VERSION ""

NS_ :

BS_:

BU_: PPIM HCP SGW IDCM EVCU2 BPCM

BO_ 834 GLIWA_T1_TX: 8 EVCU2
 SG_ N_PDU_342 : 7|64@0+ (1,0) [0|0] ""  SGW

BO_ 835 GLIWA_T1_RX: 8 SGW
 SG_ N_PDU_343 : 7|64@0+ (1,0) [0|0] ""  EVCU2

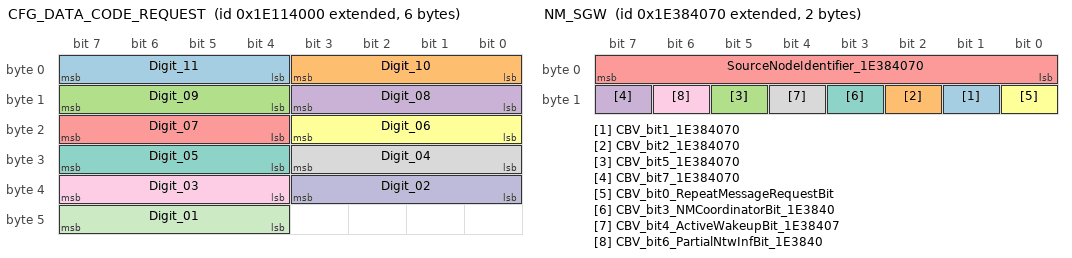
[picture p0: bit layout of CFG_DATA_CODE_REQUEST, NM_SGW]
BO_ 2651930624 CFG_DATA_CODE_REQUEST: 6 EVCU2
 SG_ Digit_11 : 7|4@0+ (1,0) [0|15] ""  PPIM,IDCM,BPCM
 SG_ Digit_10 : 3|4@0+ (1,0) [0|15] ""  PPIM,IDCM,BPCM
 SG_ Digit_09 : 15|4@0+ (1,0) [0|15] ""  PPIM,IDCM,BPCM
 SG_ Digit_08 : 11|4@0+ (1,0) [0|15] ""  PPIM,IDCM,BPCM
 SG_ Digit_07 : 23|4@0+ (1,0) [0|15] ""  PPIM,IDCM,BPCM
 SG_ Digit_06 : 19|4@0+ (1,0) [0|15] ""  PPIM,IDCM,BPCM
 SG_ Digit_05 : 31|4@0+ (1,0) [0|15] ""  PPIM,IDCM,BPCM
 SG_ Digit_04 : 27|4@0+ (1,0) [0|15] ""  PPIM,IDCM,BPCM
 SG_ Digit_03 : 39|4@0+ (1,0) [0|15] ""  PPIM,IDCM,BPCM
 SG_ Digit_02 : 35|4@0+ (1,0) [0|15] ""  PPIM,IDCM,BPCM
 SG_ Digit_01 : 47|4@0+ (1,0) [0|15] ""  PPIM,IDCM,BPCM

BO_ 2564554481 DIAGNOSTIC_REQUEST_FUNCTIONAL: 8 SGW
 SG_ N_PDU_18DBFEF1 : 7|64@0+ (1,0) [0|0] ""  PPIM,IDCM,BPCM,HCP

BO_ 2564502513 DIAGNOSTIC_REQUEST_FUNC_OBD: 8 SGW
 SG_ N_PDU_18DB33F1 : 7|64@0+ (1,0) [0|0] ""  EVCU2,IDCM,BPCM

BO_ 2564485444 DIAGNOSTIC_RESPONSE_BPCM: 8 BPCM
 SG_ N_PDU_18DAF144 : 7|64@0+ (1,0) [0|0] ""  SGW

BO_ 2564441329 DIAGNOSTIC_REQUEST_BPCM: 8 SGW
 SG_ N_PDU_18DA44F1 : 7|64@0+ (1,0) [0|0] ""  BPCM

BO_ 2564485451 DIAGNOSTIC_RESPONSE_HCP: 8 HCP
 SG_ N_PDU_18DAF14B : 7|64@0+ (1,0) [0|0] ""  SGW

BO_ 2564443121 DIAGNOSTIC_REQUEST_HCP: 8 SGW
 SG_ N_PDU_18DA4BF1 : 7|64@0+ (1,0) [0|0] ""  HCP

BO_ 2564485456 DIAGNOSTIC_RESPONSE_IDCM: 8 IDCM
 SG_ N_PDU_18DAF150 : 7|64@0+ (1,0) [0|0] ""  SGW

BO_ 2564444401 DIAGNOSTIC_REQUEST_IDCM: 8 SGW
 SG_ N_PDU_18DA50F1 : 7|64@0+ (1,0) [0|0] ""  IDCM

BO_ 1053 VIN: 32 EVCU2
 SG_ VIN_MSG : 75|2@0+ (1,0) [0|3] ""  PPIM,IDCM,BPCM
 SG_ VIN_DATA : 87|56@0+ (1,0) [0|7.20575940379279E+016] ""  PPIM,IDCM,BPCM

BO_ 520 TRANSM_FD_2: 32 EVCU2
 SG_ GearEngagedForDisplay : 15|5@0+ (1,0) [0|30] "-"  IDCM,BPCM

BO_ 156 TELEMATIC_FD_1: 32 EVCU2
 SG_ GPS_UTC_Second : 151|16@0+ (0.01,0) [0|59.99] "s"  IDCM,BPCM
 SG_ GPS_UTC_Minute : 47|8@0+ (1,0) [0|59] "min"  IDCM,BPCM
 SG_ GPS_UTC_Hour : 55|8@0+ (1,0) [0|23] "h"  IDCM,BPCM
 SG_ GPS_Date_Year : 167|16@0+ (1,0) [0|65534] "Years"  IDCM,BPCM
 SG_ GPS_Date_Month : 71|8@0+ (1,0) [1|12] "Months"  IDCM,BPCM
 SG_ GPS_Date_Day : 63|8@0+ (1,0) [1|31] "Days"  IDCM,BPCM

BO_ 1058 OBD_CONTENT_FRAME: 32 HCP
 SG_ CARB_PERM : 119|1@0+ (1,0) [0|1] "-"  BPCM
 SG_ OAT_PT_EstV : 60|1@0+ (1,0) [0|0] "-"  BPCM
 SG_ OAT_PT_Est : 55|8@0+ (1,-64) [-64|191] "°C"  BPCM

BO_ 1829 IPC_FD_1: 32 EVCU2
 SG_ TotalOdometer : 75|20@0+ (1,0) [0|1048575] "km"  PPIM,IDCM,BPCM

BO_ 1626 IMPACT_INFO: 32 EVCU2
 SG_ IMPACTConfirm : 81|1@0+ (1,0) [0|1] "-"  IDCM,BPCM
 SG_ IMPACTCommand : 80|1@0+ (1,0) [0|1] "-"  IDCM,BPCM

BO_ 2564554482 DIAGNOSTIC_REQUEST_FD_FUNCTIONAL: 64 SGW
 SG_ N_PDU_18DBFEF2 : 7|64@0+ (1,0) [0|0] ""  PPIM,EVCU2,IDCM,BPCM,HCP

BO_ 609 BRAKE_FD_4: 32 EVCU2
 SG_ EPBSts : 115|4@0+ (1,0) [0|14] "-"  IDCM,BPCM

BO_ 1066 BCM_FD_9: 32 EVCU2
 SG_ ExternalTemperature : 0|9@0+ (0.5,-85) [-85|170] "°C"  IDCM,BPCM

BO_ 1827 BCM_FD_7: 32 EVCU2
 SG_ IgnitionOnCounter : 95|16@0+ (1,0) [0|65535] "-"  PPIM,IDCM,BPCM

BO_ 256 BCM_FD_2: 32 EVCU2
 SG_ OperationalModeSts : 75|4@0+ (1,0) [0|15] ""  IDCM,BPCM

BO_ 1153 BCM_FD_10: 32 EVCU2
 SG_ ExternalTemperatureC : 80|9@0+ (0.5,-85) [-85|170] "°C"  PPIM,IDCM,BPCM
 SG_ CmdIgnSts : 138|3@0+ (1,0) [0|7] ""  PPIM,IDCM,BPCM

BO_ 1373 LV_CHARGER3: 32 BPCM
 SG_ DCDC_OutputPower : 81|10@0+ (3,0) [0|3066] "W"  SGW,HCP
 SG_ LVDC_LowVoltageSts : 112|1@0+ (1,0) [0|0] "-"  HCP
 SG_ LVDC_HighVoltageSts : 111|1@0+ (1,0) [0|0] "-"  HCP
 SG_ LVDC_HighCurrentSts : 103|1@0+ (1,0) [0|0] "-"  HCP
 SG_ HVDC_OvervoltageSts : 87|1@0+ (1,0) [0|0] "-"  HCP
 SG_ DCDC_Utilization : 102|7@0+ (1,0) [0|126] "%"  HCP
 SG_ DCDC_TotalOperatingTime : 23|16@0+ (1,0) [0|65534] "Hours"  HCP
 SG_ DCDC_InputPower : 65|10@0+ (3,0) [0|3066] "W"  HCP
 SG_ DCDC_DeratingReason : 86|5@0+ (1,0) [0|0] "-"  HCP
 SG_ DCDC_DeratingPower : 71|6@0+ (50,0) [0|3100] "W"  HCP
 SG_ DCDC_DeratingModeSts : 54|3@0+ (1,0) [0|0] "-"  HCP
 SG_ DCDC_CurrentCycleTime : 7|16@0+ (1,0) [0|65534] "sec"  HCP
 SG_ DCDC_BatteryFeedVoltage : 51|12@0+ (0.0097703,0) [0|40] "V"  HCP

BO_ 1030 LV_CHARGER2: 32 BPCM
 SG_ DCDC_FailureReason : 7|6@0+ (1,0) [0|0] "-"  SGW,HCP
 SG_ LVDC_VoltageSetpointFdbk : 63|8@0+ (0.0625,0) [0|15.875] "V"  HCP
 SG_ LVDC_CurrentSetpointFdbk : 16|9@0+ (1,-255) [-255|255] "Amp"  HCP
 SG_ HVDC_VoltageSetpointFdbk : 32|9@0+ (1,0) [0|510] "V"  HCP
 SG_ HVDC_CurrentSetpointFdbk : 1|10@0+ (0.2,-100) [-100|104.4] "Amp"  HCP
 SG_ DCDC_InternalMode : 19|3@0+ (1,0) [0|0] "-"  HCP
 SG_ DCDC_FailureType : 23|2@0+ (1,0) [0|0] "-"  HCP
 SG_ DCDC_EstimatedPowerLoss : 55|8@0+ (2,0) [0|504] "W"  HCP

BO_ 753 LV_CHARGER1: 32 IDCM
 SG_ LVDC_CurrentFeedback : 19|12@0+ (0.15,-299) [-299|299.5] "Amp"  HCP
 SG_ DCDC_OperationModeSts : 7|4@0+ (1,0) [0|0] "-"  HCP
 SG_ MessageCounter_LV_CHARGER1 : 179|4@0+ (1,0) [0|15] "-" Vector__XXX
 SG_ CRC_LV_CHARGER1 : 191|8@0+ (1,0) [0|255] "-" Vector__XXX
 SG_ LVDC_VoltageFeedback : 51|12@0+ (0.005,0) [0|199.999] "V"  HCP
 SG_ HVDC_VoltageFeedback : 35|12@0+ (0.125,0) [0|510] "V"  HCP
 SG_ HVDC_CurrentFeedback : 3|12@0+ (0.1,-149) [-149|150] "Amp"  HCP
 SG_ IDCM_Wakeup_HCP : 23|1@0+ (1,0) [0|1] "-"  EVCU2

BO_ 752 IBS3_DATA_1: 32 HCP
 SG_ IBS3_Vbatt : 96|9@0+ (0.025,5) [5|17.75] "V"  BPCM

BO_ 267 HYBRID_SYSTEM_EPT1: 32 EVCU2
 SG_ MessageCounter_HYBRID_SYSTEM_EPT : 179|4@0+ (1,0) [0|15] "-"  BPCM
 SG_ LOC_DiagEnable_ePT : 9|2@0+ (1,0) [0|0] "-"  BPCM
 SG_ HybridDriveModeSts : 3|4@0+ (1,0) [0|0] "-"  SGW
 SG_ HCP_ShutdownCommand : 6|3@0+ (1,0) [0|0] "-"  BPCM
 SG_ CRC_HYBRID_SYSTEM_EPT1 : 191|8@0+ (1,0) [0|255] "-"  BPCM
 SG_ WU_Timer_Value : 23|16@0+ (1,0) [0|65535] "min"  IDCM,BPCM
 SG_ PerWakeUp_Diag : 33|10@0+ (1,0) [0|1023] "-"  IDCM,BPCM
 SG_ PropulsionSystemActive_10B : 7|1@0+ (1,0) [0|1] "-"  BPCM

BO_ 1956 HYBRID_RM_MOTORS: 32 HCP
 SG_ MotorB_Temperature : 151|8@0+ (1,-40) [-40|215] "oC"  SGW
 SG_ MotorB_RPM : 23|16@0+ (1,-32768) [-32768|32767] "RPM"  SGW
 SG_ MotorB_InverterTemp : 159|8@0+ (1,-40) [-40|215] "oC"  SGW
 SG_ MotorB_DC_Voltage : 113|10@0+ (1,0) [0|1023] "V"  SGW
 SG_ MotorB_DC_Current : 54|15@0+ (0.1,-1638.4) [-1638.4|1638.3] "A"  SGW
 SG_ MotorA_Temperature : 135|8@0+ (1,-40) [-40|215] "oC"  SGW
 SG_ MotorA_RPM : 7|16@0+ (1,-32768) [-32768|32767] "RPM"  SGW
 SG_ MotorA_InverterTemp : 143|8@0+ (1,-40) [-40|215] "oC"  SGW
 SG_ MotorA_DC_Voltage : 97|10@0+ (1,0) [0|1023] "V"  SGW
 SG_ MotorA_DC_Current : 38|15@0+ (0.1,-1638.4) [-1638.4|1638.3] "A"  SGW
 SG_ Warning_MotorB_Overtemp : 55|1@0+ (1,0) [0|1] ""  SGW
 SG_ Warning_MotorA_Overtemp : 39|1@0+ (1,0) [0|1] ""  SGW
 SG_ Warning_InverterA_Overtemp : 69|1@0+ (1,0) [0|1] ""  SGW
 SG_ Warning_DCDCTemp_DPT : 71|1@0+ (1,0) [0|1] ""  SGW
 SG_ Warning_DCDCPerformance_DPT : 85|1@0+ (1,0) [0|1] ""  SGW
 SG_ MotorB_InverterState : 117|4@0+ (1,0) [0|15] ""  SGW
 SG_ MotorA_InverterState : 101|4@0+ (1,0) [0|15] ""  SGW
 SG_ Warning_InverterB_Overtemp : 70|1@0+ (1,0) [0|1] ""  SGW
 SG_ MotorB_TorqueAchieved : 84|13@0+ (0.125,-512) [-512|511.875] "Nm"  SGW
 SG_ MotorA_TorqueAchieved : 68|13@0+ (0.125,-512) [-512|511.875] "Nm"  SGW

BO_ 1033 HYBRID_POWERTRAIN5: 32 HCP
 SG_ MCP_DC_Current : 6|15@0+ (0.1,-1638.4) [-1638.3|1638.3] "Amp"  BPCM
 SG_ MCP_DC_CurrentV : 23|1@0+ (1,0) [0|0] "-"  BPCM

BO_ 1834 HVBATTERY5: 32 BPCM
 SG_ HVBattery_RealTimeClockV : 36|1@0+ (1,0) [0|0] "-"  EVCU2
 SG_ HVBattery_RealTimeClock : 7|32@0+ (1,0) [0|4294967294] "sec"  EVCU2
 SG_ HVBatteryBalanceMode : 54|1@0+ (1,0) [0|0] "-"  HCP
 SG_ HVBatteryBalanceComplete : 55|1@0+ (1,0) [0|0] "-"  HCP
 SG_ HVBatCellOCVoltage_MinV : 39|1@0+ (1,0) [0|0] "-"  HCP
 SG_ HVBatCellOCVoltage_Min : 67|12@0+ (0.001,1.5) [1.5|4.5] "Volts"  HCP
 SG_ HVBatCellOCVoltage_MaxV : 38|1@0+ (1,0) [0|0] "-"  HCP
 SG_ HVBatCellOCVoltage_Max : 51|12@0+ (0.001,1.5) [1.5|4.5] "Volts"  HCP
 SG_ HVBatCellOCVoltage_AverageV : 37|1@0+ (1,0) [0|0] "-"  HCP
 SG_ HVBatCellOCVoltage_Average : 35|12@0+ (0.001,1.5) [1.5|4.5] "Volts"  HCP
 SG_ HVBatCellDischargeImped_Min : 99|12@0+ (0.01,0) [0|40.9] "Ohms"  HCP
 SG_ HVBatCellDischargeImped_Max : 83|12@0+ (0.01,0) [0|40.9] "Ohms"  HCP

BO_ 1029 HVBATTERY3: 32 BPCM
 SG_ HVBatPowerLimited : 117|1@0+ (1,0) [0|0] "-"  HCP
 SG_ BSGDischargePower_ShortV : 114|1@0+ (1,0) [0|0] "-"  HCP
 SG_ BSGDischargePower_Short : 87|8@0+ (0.1,0) [0|25] "kW"  HCP
 SG_ BSGDischargePower_LongV : 113|1@0+ (1,0) [0|0] "-"  HCP
 SG_ BSGDischargePower_Long : 79|8@0+ (0.1,0) [0|25] "kW"  HCP
 SG_ BSGDischargePower_InstantV : 115|1@0+ (1,0) [0|0] "-"  HCP
 SG_ BSGDischargePower_Instant : 95|8@0+ (0.1,0) [0|25] "kW"  HCP
 SG_ BSGChargePower_ShortV : 111|1@0+ (1,0) [0|0] "-"  HCP
 SG_ BSGChargePower_Short : 63|8@0+ (0.1,0) [0|25] "kW"  HCP
 SG_ BSGChargePower_LongV : 110|1@0+ (1,0) [0|0] "-"  HCP
 SG_ BSGChargePower_Long : 55|8@0+ (0.1,0) [0|25] "kW"  HCP
 SG_ BSGChargePower_InstantV : 112|1@0+ (1,0) [0|0] "-"  HCP
 SG_ BSGChargePower_Instant : 71|8@0+ (0.1,0) [0|25] "kW"  HCP

BO_ 1027 HVBATTERY2: 32 BPCM
 SG_ HVBatterySOCV : 52|1@0+ (1,0) [0|0] "-"  HCP
 SG_ HVBatterySOC : 3|12@0+ (0.02442,0) [0|100] "%"  SGW,HCP
 SG_ HVBatteryMILRequest : 7|1@0+ (1,0) [0|0] "-"  HCP
 SG_ HVBatterySOH : 39|8@0+ (0.2,50) [50|100] "%"  HCP
 SG_ HVBatterySOC_Min : 31|8@0+ (0.392157,0) [0|100] "%"  HCP
 SG_ HVBatterySOC_Max : 23|8@0+ (0.392157,0) [0|100] "%"  HCP
 SG_ HVBatteryServiceRequest : 51|1@0+ (1,0) [0|0] "-"  HCP
 SG_ PrechargePenaltyTimer : 49|10@0+ (2,0) [0|1800] "sec"  HCP

BO_ 266 HVBATTERY1: 32 BPCM
 SG_ HVBatteryCurrent : 5|14@0+ (0.1,-512.1) [-512|512] "Amp"  HCP
 SG_ HVBatContactorSts : 23|3@0+ (1,0) [0|0] "-"  HCP
 SG_ HVBatCellVoltage_NumMax : 71|4@0+ (1,0) [0|15] "Volts"  HCP
 SG_ HVBatCellVoltage_Min : 108|13@0+ (0.001,0) [0|5] "Volts"  HCP
 SG_ HVBatCellVoltage_Max : 36|13@0+ (0.001,0) [0|5] "Volts"  HCP
 SG_ HVBatteryVoltageV : 98|1@0+ (1,0) [0|0] "-"  HCP
 SG_ HVBatteryReady : 97|1@0+ (1,0) [0|0] "-"  HCP
 SG_ HVBatteryCurrentV : 96|1@0+ (1,0) [0|0] "-"  HCP
 SG_ HVBatContactorReq : 55|1@0+ (1,0) [0|0] "-"  HCP
 SG_ HVBatContactorOpen : 39|1@0+ (1,0) [0|0] "-"  HCP
 SG_ HVBatCellVoltage_MinV : 101|1@0+ (1,0) [0|0] "-"  HCP
 SG_ HVBatCellVoltage_MaxV : 100|1@0+ (1,0) [0|0] "-"  HCP
 SG_ HVBatCellVoltage_AverageV : 99|1@0+ (1,0) [0|0] "-"  HCP
 SG_ HVBatCellVoltage_Average : 20|13@0+ (0.001,0) [0|5] "Volts"  HCP
 SG_ HVBatteryVoltage_BSG : 85|6@0+ (1,20) [20|70] "-"  HCP
 SG_ HVBatCellVoltage_NumMin : 51|4@0+ (1,0) [0|15] "Volts"  HCP
 SG_ HVBatShutdownReady : 183|2@0+ (1,0) [0|3] "-"  HCP
 SG_ HVBatContactorWelded : 110|2@0+ (1,0) [0|2] "-"  HCP

BO_ 1034 HVBATTERY_THERMAL: 48 BPCM
 SG_ HVBatModuleTemp_MinV : 87|1@0+ (1,0) [0|0] "-"  HCP
 SG_ HVBatModuleTemp_Min : 159|8@0+ (1,-40) [-40|214] "°C"  SGW,HCP
 SG_ HVBatModuleTemp_MaxV : 209|1@0+ (1,0) [0|0] "-"  HCP
 SG_ HVBatModuleTemp_Max : 151|8@0+ (1,-40) [-40|214] "°C"  SGW,HCP
 SG_ HVBatSleepTime : 7|8@0+ (0.2,0) [0|48] "Days"  EVCU2
 SG_ HVBatModuleTemp_AverageV : 210|1@0+ (1,0) [0|0] "-"  HCP
 SG_ HVBatModuleTemp_Average : 143|8@0+ (1,-40) [-40|214] "°C"  HCP
 SG_ HVBatLowTempThreshold : 231|8@0+ (1,-40) [-40|214] "°C"  HCP
 SG_ HVBatHighTempThreshold : 223|8@0+ (1,-40) [-40|214] "°C"  HCP
 SG_ HVBatModuleTemp_NumMin : 268|5@0+ (1,0) [0|31] "-"  SGW
 SG_ HVBatModuleTemp_NumMax : 260|5@0+ (1,0) [0|31] "-"  SGW

BO_ 1839 HVBATTERY_RM_MODS1: 48 BPCM
 SG_ HVBatModuleTemp_16 : 127|8@0+ (1,-40) [-40|215] "°C"  SGW
 SG_ HVBatModuleTemp_15 : 119|8@0+ (1,-40) [-40|215] "°C"  SGW
 SG_ HVBatModuleTemp_14 : 111|8@0+ (1,-40) [-40|215] "°C"  SGW
 SG_ HVBatModuleTemp_13 : 103|8@0+ (1,-40) [-40|215] "°C"  SGW
 SG_ HVBatModuleTemp_12 : 95|8@0+ (1,-40) [-40|215] "°C"  SGW
 SG_ HVBatModuleTemp_11 : 87|8@0+ (1,-40) [-40|215] "°C"  SGW
 SG_ HVBatModuleTemp_10 : 79|8@0+ (1,-40) [-40|215] "°C"  SGW
 SG_ HVBatModuleTemp_09 : 71|8@0+ (1,-40) [-40|215] "°C"  SGW
 SG_ HVBatModuleTemp_08 : 63|8@0+ (1,-40) [-40|215] "°C"  SGW
 SG_ HVBatModuleTemp_07 : 55|8@0+ (1,-40) [-40|215] "°C"  SGW
 SG_ HVBatModuleTemp_06 : 47|8@0+ (1,-40) [-40|215] "°C"  SGW
 SG_ HVBatModuleTemp_05 : 39|8@0+ (1,-40) [-40|215] "°C"  SGW
 SG_ HVBatModuleTemp_04 : 31|8@0+ (1,-40) [-40|215] "°C"  SGW
 SG_ HVBatModuleTemp_03 : 23|8@0+ (1,-40) [-40|215] "°C"  SGW
 SG_ HVBatModuleTemp_02 : 15|8@0+ (1,-40) [-40|215] "°C"  SGW
 SG_ HVBatModuleTemp_01 : 7|8@0+ (1,-40) [-40|215] "°C"  SGW
 SG_ HVBatModuleTemp_38 : 303|8@0+ (1,-40) [-40|215] "°C" Vector__XXX
 SG_ HVBatModuleTemp_37 : 295|8@0+ (1,-40) [-40|215] "°C" Vector__XXX
 SG_ HVBatModuleTemp_36 : 287|8@0+ (1,-40) [-40|215] "°C" Vector__XXX
 SG_ HVBatModuleTemp_35 : 279|8@0+ (1,-40) [-40|215] "°C" Vector__XXX
 SG_ HVBatModuleTemp_34 : 271|8@0+ (1,-40) [-40|215] "°C" Vector__XXX
 SG_ HVBatModuleTemp_33 : 263|8@0+ (1,-40) [-40|215] "°C" Vector__XXX
 SG_ HVBatModuleTemp_32 : 255|8@0+ (1,-40) [-40|215] "°C" Vector__XXX
 SG_ HVBatModuleTemp_31 : 247|8@0+ (1,-40) [-40|215] "°C" Vector__XXX
 SG_ HVBatModuleTemp_30 : 239|8@0+ (1,-40) [-40|215] "°C" Vector__XXX
 SG_ HVBatModuleTemp_29 : 231|8@0+ (1,-40) [-40|215] "°C" Vector__XXX
 SG_ HVBatModuleTemp_28 : 223|8@0+ (1,-40) [-40|215] "°C" Vector__XXX
 SG_ HVBatModuleTemp_27 : 215|8@0+ (1,-40) [-40|215] "°C" Vector__XXX
 SG_ HVBatModuleTemp_26 : 207|8@0+ (1,-40) [-40|215] "°C" Vector__XXX
 SG_ HVBatModuleTemp_25 : 199|8@0+ (1,-40) [-40|215] "°C" Vector__XXX
 SG_ HVBatModuleTemp_24 : 191|8@0+ (1,-40) [-40|215] "°C" Vector__XXX
 SG_ HVBatModuleTemp_23 : 183|8@0+ (1,-40) [-40|215] "°C" Vector__XXX
 SG_ HVBatModuleTemp_22 : 175|8@0+ (1,-40) [-40|215] "°C" Vector__XXX
 SG_ HVBatModuleTemp_21 : 167|8@0+ (1,-40) [-40|215] "°C" Vector__XXX
 SG_ HVBatModuleTemp_20 : 159|8@0+ (1,-40) [-40|215] "°C" Vector__XXX
 SG_ HVBatModuleTemp_19 : 151|8@0+ (1,-40) [-40|215] "°C" Vector__XXX
 SG_ HVBatModuleTemp_18 : 143|8@0+ (1,-40) [-40|215] "°C" Vector__XXX
 SG_ HVBatModuleTemp_17 : 135|8@0+ (1,-40) [-40|215] "°C" Vector__XXX

BO_ 1840 HVBATTERY_RM_CHARGING1: 32 BPCM
 SG_ IsolationResistance : 7|16@0+ (1,0) [0|65534] "kOhm"  SGW
 SG_ Warning_SOCJump : 24|1@0+ (1,0) [0|1] "-"  SGW
 SG_ Warning_PackUnmatched : 27|1@0+ (1,0) [0|1] "-"  SGW
 SG_ Warning_PackUndervoltage : 19|1@0+ (1,0) [0|1] "-"  SGW
 SG_ Warning_PackTempHigh : 26|1@0+ (1,0) [0|1] "-"  EVCU2,SGW
 SG_ Warning_PackTempDiff : 25|1@0+ (1,0) [0|1] "-"  SGW
 SG_ Warning_PackOvervoltage : 20|1@0+ (1,0) [0|1] "-"  SGW
 SG_ Warning_Overcharging : 21|1@0+ (1,0) [0|1] "-"  SGW
 SG_ Warning_LowSOC : 22|1@0+ (1,0) [0|1] "-"  SGW
 SG_ Warning_Insulation : 28|1@0+ (1,0) [0|1] "-"  SGW
 SG_ Warning_HVIL : 29|1@0+ (1,0) [0|1] "-"  SGW
 SG_ Warning_HighSOC : 23|1@0+ (1,0) [0|1] "-"  SGW
 SG_ Warning_CellUndervoltage : 17|1@0+ (1,0) [0|1] "-"  SGW
 SG_ Warning_CellOvervoltage : 18|1@0+ (1,0) [0|1] "-"  SGW
 SG_ Warning_CellBalance : 16|1@0+ (1,0) [0|1] "-"  SGW
 SG_ HighestWarningLevel : 39|2@0+ (1,0) [0|3] "-"  SGW

BO_ 1838 HVBATTERY_RM_CELLS4: 64 BPCM
 SG_ HVBatCellVoltage_Cell096 : 228|13@0+ (0.001,0) [0|5] "V"  SGW
 SG_ HVBatCellVoltage_Cell095 : 212|13@0+ (0.001,0) [0|5] "V"  SGW
 SG_ HVBatCellVoltage_Cell094 : 196|13@0+ (0.001,0) [0|5] "V"  SGW
 SG_ HVBatCellVoltage_Cell093 : 180|13@0+ (0.001,0) [0|5] "V"  SGW
 SG_ HVBatCellVoltage_Cell092 : 164|13@0+ (0.001,0) [0|5] "V"  SGW
 SG_ HVBatCellVoltage_Cell091 : 148|13@0+ (0.001,0) [0|5] "V"  SGW
 SG_ HVBatCellVoltage_Cell090 : 132|13@0+ (0.001,0) [0|5] "V"  SGW
 SG_ HVBatCellVoltage_Cell089 : 116|13@0+ (0.001,0) [0|5] "V"  SGW
 SG_ HVBatCellVoltage_Cell088 : 100|13@0+ (0.001,0) [0|5] "V"  SGW
 SG_ HVBatCellVoltage_Cell087 : 84|13@0+ (0.001,0) [0|5] "V"  SGW
 SG_ HVBatCellVoltage_Cell086 : 68|13@0+ (0.001,0) [0|5] "V"  SGW
 SG_ HVBatCellVoltage_Cell085 : 52|13@0+ (0.001,0) [0|5] "V"  SGW
 SG_ HVBatCellVoltage_Cell084 : 36|13@0+ (0.001,0) [0|5] "V"  SGW
 SG_ HVBatCellVoltage_Cell083 : 20|13@0+ (0.001,0) [0|5] "V"  SGW
 SG_ HVBatCellVoltage_Cell082 : 4|13@0+ (0.001,0) [0|5] "V"  SGW
 SG_ HVBatCellVoltage_Cell108 : 420|13@0+ (0.001,0) [0|5] "V"  SGW
 SG_ HVBatCellVoltage_Cell107 : 404|13@0+ (0.001,0) [0|5] "V"  SGW
 SG_ HVBatCellVoltage_Cell106 : 388|13@0+ (0.001,0) [0|5] "V"  SGW
 SG_ HVBatCellVoltage_Cell105 : 372|13@0+ (0.001,0) [0|5] "V"  SGW
 SG_ HVBatCellVoltage_Cell104 : 356|13@0+ (0.001,0) [0|5] "V"  SGW
 SG_ HVBatCellVoltage_Cell103 : 340|13@0+ (0.001,0) [0|5] "V"  SGW
 SG_ HVBatCellVoltage_Cell102 : 324|13@0+ (0.001,0) [0|5] "V"  SGW
 SG_ HVBatCellVoltage_Cell101 : 308|13@0+ (0.001,0) [0|5] "V"  SGW
 SG_ HVBatCellVoltage_Cell100 : 292|13@0+ (0.001,0) [0|5] "V"  SGW
 SG_ HVBatCellVoltage_Cell099 : 276|13@0+ (0.001,0) [0|5] "V"  SGW
 SG_ HVBatCellVoltage_Cell098 : 260|13@0+ (0.001,0) [0|5] "V"  SGW
 SG_ HVBatCellVoltage_Cell097 : 244|13@0+ (0.001,0) [0|5] "V"  SGW

BO_ 1837 HVBATTERY_RM_CELLS3: 64 BPCM
 SG_ HVBatCellVoltage_Cell081 : 420|13@0+ (0.001,0) [0|5] "V"  SGW
 SG_ HVBatCellVoltage_Cell080 : 404|13@0+ (0.001,0) [0|5] "V"  SGW
 SG_ HVBatCellVoltage_Cell079 : 388|13@0+ (0.001,0) [0|5] "V"  SGW
 SG_ HVBatCellVoltage_Cell078 : 372|13@0+ (0.001,0) [0|5] "V"  SGW
 SG_ HVBatCellVoltage_Cell077 : 356|13@0+ (0.001,0) [0|5] "V"  SGW
 SG_ HVBatCellVoltage_Cell076 : 340|13@0+ (0.001,0) [0|5] "V"  SGW
 SG_ HVBatCellVoltage_Cell075 : 324|13@0+ (0.001,0) [0|5] "V"  SGW
 SG_ HVBatCellVoltage_Cell074 : 308|13@0+ (0.001,0) [0|5] "V"  SGW
 SG_ HVBatCellVoltage_Cell073 : 292|13@0+ (0.001,0) [0|5] "V"  SGW
 SG_ HVBatCellVoltage_Cell072 : 276|13@0+ (0.001,0) [0|5] "V"  SGW
 SG_ HVBatCellVoltage_Cell071 : 260|13@0+ (0.001,0) [0|5] "V"  SGW
 SG_ HVBatCellVoltage_Cell070 : 244|13@0+ (0.001,0) [0|5] "V"  SGW
 SG_ HVBatCellVoltage_Cell069 : 228|13@0+ (0.001,0) [0|5] "V"  SGW
 SG_ HVBatCellVoltage_Cell068 : 212|13@0+ (0.001,0) [0|5] "V"  SGW
 SG_ HVBatCellVoltage_Cell067 : 196|13@0+ (0.001,0) [0|5] "V"  SGW
 SG_ HVBatCellVoltage_Cell066 : 180|13@0+ (0.001,0) [0|5] "V"  SGW
 SG_ HVBatCellVoltage_Cell065 : 164|13@0+ (0.001,0) [0|5] "V"  SGW
 SG_ HVBatCellVoltage_Cell064 : 148|13@0+ (0.001,0) [0|5] "V"  SGW
 SG_ HVBatCellVoltage_Cell063 : 132|13@0+ (0.001,0) [0|5] "V"  SGW
 SG_ HVBatCellVoltage_Cell062 : 116|13@0+ (0.001,0) [0|5] "V"  SGW
 SG_ HVBatCellVoltage_Cell061 : 100|13@0+ (0.001,0) [0|5] "V"  SGW
 SG_ HVBatCellVoltage_Cell060 : 84|13@0+ (0.001,0) [0|5] "V"  SGW
 SG_ HVBatCellVoltage_Cell059 : 68|13@0+ (0.001,0) [0|5] "V"  SGW
 SG_ HVBatCellVoltage_Cell058 : 52|13@0+ (0.001,0) [0|5] "V"  SGW
 SG_ HVBatCellVoltage_Cell057 : 36|13@0+ (0.001,0) [0|5] "V"  SGW
 SG_ HVBatCellVoltage_Cell056 : 20|13@0+ (0.001,0) [0|5] "V"  SGW
 SG_ HVBatCellVoltage_Cell055 : 4|13@0+ (0.001,0) [0|5] "V"  SGW

BO_ 1836 HVBATTERY_RM_CELLS2: 64 BPCM
 SG_ HVBatCellVoltage_Cell054 : 420|13@0+ (0.001,0) [0|5] "V"  SGW
 SG_ HVBatCellVoltage_Cell053 : 404|13@0+ (0.001,0) [0|5] "V"  SGW
 SG_ HVBatCellVoltage_Cell052 : 388|13@0+ (0.001,0) [0|5] "V"  SGW
 SG_ HVBatCellVoltage_Cell051 : 372|13@0+ (0.001,0) [0|5] "V"  SGW
 SG_ HVBatCellVoltage_Cell050 : 356|13@0+ (0.001,0) [0|5] "V"  SGW
 SG_ HVBatCellVoltage_Cell049 : 340|13@0+ (0.001,0) [0|5] "V"  SGW
 SG_ HVBatCellVoltage_Cell048 : 324|13@0+ (0.001,0) [0|5] "V"  SGW
 SG_ HVBatCellVoltage_Cell047 : 308|13@0+ (0.001,0) [0|5] "V"  SGW
 SG_ HVBatCellVoltage_Cell046 : 292|13@0+ (0.001,0) [0|5] "V"  SGW
 SG_ HVBatCellVoltage_Cell045 : 276|13@0+ (0.001,0) [0|5] "V"  SGW
 SG_ HVBatCellVoltage_Cell044 : 260|13@0+ (0.001,0) [0|5] "V"  SGW
 SG_ HVBatCellVoltage_Cell043 : 244|13@0+ (0.001,0) [0|5] "V"  SGW
 SG_ HVBatCellVoltage_Cell042 : 228|13@0+ (0.001,0) [0|5] "V"  SGW
 SG_ HVBatCellVoltage_Cell041 : 212|13@0+ (0.001,0) [0|5] "V"  SGW
 SG_ HVBatCellVoltage_Cell040 : 196|13@0+ (0.001,0) [0|5] "V"  SGW
 SG_ HVBatCellVoltage_Cell039 : 180|13@0+ (0.001,0) [0|5] "V"  SGW
 SG_ HVBatCellVoltage_Cell038 : 164|13@0+ (0.001,0) [0|5] "V"  SGW
 SG_ HVBatCellVoltage_Cell037 : 148|13@0+ (0.001,0) [0|5] "V"  SGW
 SG_ HVBatCellVoltage_Cell036 : 132|13@0+ (0.001,0) [0|5] "V"  SGW
 SG_ HVBatCellVoltage_Cell035 : 116|13@0+ (0.001,0) [0|5] "V"  SGW
 SG_ HVBatCellVoltage_Cell034 : 100|13@0+ (0.001,0) [0|5] "V"  SGW
 SG_ HVBatCellVoltage_Cell033 : 84|13@0+ (0.001,0) [0|5] "V"  SGW
 SG_ HVBatCellVoltage_Cell032 : 68|13@0+ (0.001,0) [0|5] "V"  SGW
 SG_ HVBatCellVoltage_Cell031 : 52|13@0+ (0.001,0) [0|5] "V"  SGW
 SG_ HVBatCellVoltage_Cell030 : 36|13@0+ (0.001,0) [0|5] "V"  SGW
 SG_ HVBatCellVoltage_Cell029 : 20|13@0+ (0.001,0) [0|5] "V"  SGW
 SG_ HVBatCellVoltage_Cell028 : 4|13@0+ (0.001,0) [0|5] "V"  SGW

BO_ 1835 HVBATTERY_RM_CELLS1: 64 BPCM
 SG_ HVBatCellVoltage_Cell027 : 420|13@0+ (0.001,0) [0|5] "V"  SGW
 SG_ HVBatCellVoltage_Cell026 : 404|13@0+ (0.001,0) [0|5] "V"  SGW
 SG_ HVBatCellVoltage_Cell025 : 388|13@0+ (0.001,0) [0|5] "V"  SGW
 SG_ HVBatCellVoltage_Cell024 : 372|13@0+ (0.001,0) [0|5] "V"  SGW
 SG_ HVBatCellVoltage_Cell023 : 356|13@0+ (0.001,0) [0|5] "V"  SGW
 SG_ HVBatCellVoltage_Cell022 : 340|13@0+ (0.001,0) [0|5] "V"  SGW
 SG_ HVBatCellVoltage_Cell021 : 324|13@0+ (0.001,0) [0|5] "V"  SGW
 SG_ HVBatCellVoltage_Cell020 : 308|13@0+ (0.001,0) [0|5] "V"  SGW
 SG_ HVBatCellVoltage_Cell019 : 292|13@0+ (0.001,0) [0|5] "V"  SGW
 SG_ HVBatCellVoltage_Cell018 : 276|13@0+ (0.001,0) [0|5] "V"  SGW
 SG_ HVBatCellVoltage_Cell017 : 260|13@0+ (0.001,0) [0|5] "V"  SGW
 SG_ HVBatCellVoltage_Cell016 : 244|13@0+ (0.001,0) [0|5] "V"  SGW
 SG_ HVBatCellVoltage_Cell015 : 228|13@0+ (0.001,0) [0|5] "V"  SGW
 SG_ HVBatCellVoltage_Cell014 : 212|13@0+ (0.001,0) [0|5] "V"  SGW
 SG_ HVBatCellVoltage_Cell013 : 196|13@0+ (0.001,0) [0|5] "V"  SGW
 SG_ HVBatCellVoltage_Cell012 : 180|13@0+ (0.001,0) [0|5] "V"  SGW
 SG_ HVBatCellVoltage_Cell011 : 164|13@0+ (0.001,0) [0|5] "V"  SGW
 SG_ HVBatCellVoltage_Cell010 : 148|13@0+ (0.001,0) [0|5] "V"  SGW
 SG_ HVBatCellVoltage_Cell009 : 132|13@0+ (0.001,0) [0|5] "V"  SGW
 SG_ HVBatCellVoltage_Cell008 : 116|13@0+ (0.001,0) [0|5] "V"  SGW
 SG_ HVBatCellVoltage_Cell007 : 100|13@0+ (0.001,0) [0|5] "V"  SGW
 SG_ HVBatCellVoltage_Cell006 : 84|13@0+ (0.001,0) [0|5] "V"  SGW
 SG_ HVBatCellVoltage_Cell005 : 68|13@0+ (0.001,0) [0|5] "V"  SGW
 SG_ HVBatCellVoltage_Cell004 : 52|13@0+ (0.001,0) [0|5] "V"  SGW
 SG_ HVBatCellVoltage_Cell003 : 36|13@0+ (0.001,0) [0|5] "V"  SGW
 SG_ HVBatCellVoltage_Cell002 : 20|13@0+ (0.001,0) [0|5] "V"  SGW
 SG_ HVBatCellVoltage_Cell001 : 4|13@0+ (0.001,0) [0|5] "V"  SGW

BO_ 1035 ENGINE_HYBD_FD_3: 32 HCP
 SG_ RadFanReq : 158|7@0+ (1,0) [0|100] "%"  BPCM
 SG_ EngSpd : 7|16@0+ (0.125,0) [0|8160] "rpm"  BPCM
 SG_ EngCltTmpV : 69|1@0+ (1,0) [0|1] ""  BPCM
 SG_ EngCltTmp : 167|8@0+ (1,-40) [-40|214] "°C"  BPCM

BO_ 750 BCM_FD_3: 32 EVCU2
 SG_ Battery_Volt_1 : 56|9@0+ (0.025,5) [5|17.75] "Volt"  PPIM,IDCM,BPCM

BO_ 1436 BCM_FD_27: 32 HCP
 SG_ Blower_Speed : 136|9@0+ (1,0) [0|350] "Hz"  BPCM

BO_ 2654486640 NM_SGW: 2 SGW
 SG_ CBV_bit1_1E384070 : 9|1@0+ (1,0) [0|1] ""  EVCU2,IDCM,BPCM,HCP
 SG_ CBV_bit2_1E384070 : 10|1@0+ (1,0) [0|1] ""  EVCU2,IDCM,BPCM,HCP
 SG_ CBV_bit5_1E384070 : 13|1@0+ (1,0) [0|1] ""  EVCU2,IDCM,BPCM,HCP
 SG_ CBV_bit7_1E384070 : 15|1@0+ (1,0) [0|1] ""  EVCU2,IDCM,BPCM,HCP
 SG_ SourceNodeIdentifier_1E384070 : 7|8@0+ (1,0) [0|255] "-"  EVCU2,IDCM,BPCM,HCP
 SG_ CBV_bit0_RepeatMessageRequestBit : 8|1@0+ (1,0) [0|1] ""  EVCU2,IDCM,BPCM,HCP
 SG_ CBV_bit3_NMCoordinatorBit_1E3840 : 11|1@0+ (1,0) [0|1] ""  EVCU2,IDCM,BPCM,HCP
 SG_ CBV_bit4_ActiveWakeupBit_1E38407 : 12|1@0+ (1,0) [0|1] ""  EVCU2,IDCM,BPCM,HCP
 SG_ CBV_bit6_PartialNtwInfBit_1E3840 : 14|1@0+ (1,0) [0|1] ""  EVCU2,IDCM,BPCM,HCP

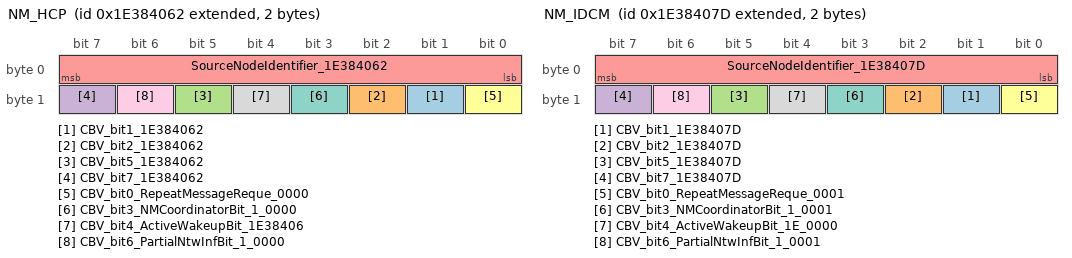
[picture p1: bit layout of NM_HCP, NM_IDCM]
BO_ 2654486626 NM_HCP: 2 HCP
 SG_ CBV_bit1_1E384062 : 9|1@0+ (1,0) [0|1] ""  PPIM,EVCU2,IDCM,SGW,BPCM
 SG_ CBV_bit2_1E384062 : 10|1@0+ (1,0) [0|1] ""  PPIM,EVCU2,IDCM,SGW,BPCM
 SG_ CBV_bit5_1E384062 : 13|1@0+ (1,0) [0|1] ""  PPIM,EVCU2,IDCM,SGW,BPCM
 SG_ CBV_bit7_1E384062 : 15|1@0+ (1,0) [0|1] ""  PPIM,EVCU2,IDCM,SGW,BPCM
 SG_ SourceNodeIdentifier_1E384062 : 7|8@0+ (1,0) [0|255] "-"  PPIM,EVCU2,IDCM,SGW,BPCM
 SG_ CBV_bit0_RepeatMessageReque_0000 : 8|1@0+ (1,0) [0|1] ""  PPIM,EVCU2,IDCM,SGW,BPCM
 SG_ CBV_bit3_NMCoordinatorBit_1_0000 : 11|1@0+ (1,0) [0|1] ""  PPIM,EVCU2,IDCM,SGW,BPCM
 SG_ CBV_bit4_ActiveWakeupBit_1E38406 : 12|1@0+ (1,0) [0|1] ""  PPIM,EVCU2,IDCM,SGW,BPCM
 SG_ CBV_bit6_PartialNtwInfBit_1_0000 : 14|1@0+ (1,0) [0|1] ""  PPIM,EVCU2,IDCM,SGW,BPCM

BO_ 276 HYBRID_POWERTRAIN1: 64 EVCU2
 SG_ HEV_ESS_Mode : 271|4@0+ (1,0) [0|0] "-"  BPCM
 SG_ PropulsionSystemActive_114 : 408|1@0+ (1,0) [0|1] "-"  BPCM

BO_ 262 ENGINE_FD_2: 64 EVCU2
 SG_ PowertrainPrplsnActv : 181|1@0+ (1,0) [0|1] ""  IDCM,BPCM
 SG_ EngineSpeed_W : 21|14@0+ (1,0) [0|16382] "1/min"  PPIM,IDCM,BPCM

BO_ 258 BRAKE_FD_2: 64 EVCU2
 SG_ VehicleSpeedVSOSig : 4|13@0+ (0.0625,0) [0|511.875] "Km/h"  PPIM,IDCM,BPCM

BO_ 2654486653 NM_IDCM: 2 IDCM
 SG_ CBV_bit1_1E38407D : 9|1@0+ (1,0) [0|1] ""  PPIM,EVCU2,SGW,BPCM,HCP
 SG_ CBV_bit2_1E38407D : 10|1@0+ (1,0) [0|1] ""  PPIM,EVCU2,SGW,BPCM,HCP
 SG_ CBV_bit5_1E38407D : 13|1@0+ (1,0) [0|1] ""  PPIM,EVCU2,SGW,BPCM,HCP
 SG_ CBV_bit7_1E38407D : 15|1@0+ (1,0) [0|1] ""  PPIM,EVCU2,SGW,BPCM,HCP
 SG_ SourceNodeIdentifier_1E38407D : 7|8@0+ (1,0) [0|255] "-"  PPIM,EVCU2,SGW,BPCM,HCP
 SG_ CBV_bit0_RepeatMessageReque_0001 : 8|1@0+ (1,0) [0|1] ""  PPIM,EVCU2,SGW,BPCM,HCP
 SG_ CBV_bit3_NMCoordinatorBit_1_0001 : 11|1@0+ (1,0) [0|1] ""  PPIM,EVCU2,SGW,BPCM,HCP
 SG_ CBV_bit4_ActiveWakeupBit_1E_0000 : 12|1@0+ (1,0) [0|1] ""  PPIM,EVCU2,SGW,BPCM,HCP
 SG_ CBV_bit6_PartialNtwInfBit_1_0001 : 14|1@0+ (1,0) [0|1] ""  PPIM,EVCU2,SGW,BPCM,HCP

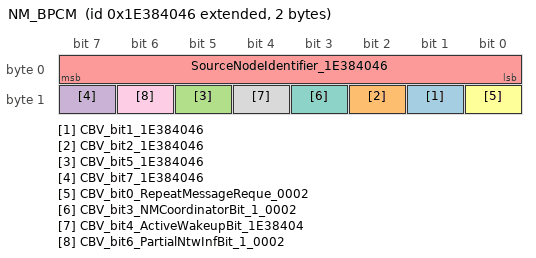
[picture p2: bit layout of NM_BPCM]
BO_ 2654486598 NM_BPCM: 2 BPCM
 SG_ CBV_bit1_1E384046 : 9|1@0+ (1,0) [0|1] ""  EVCU2,IDCM,SGW,HCP
 SG_ CBV_bit2_1E384046 : 10|1@0+ (1,0) [0|1] ""  EVCU2,IDCM,SGW,HCP
 SG_ CBV_bit5_1E384046 : 13|1@0+ (1,0) [0|1] ""  EVCU2,IDCM,SGW,HCP
 SG_ CBV_bit7_1E384046 : 15|1@0+ (1,0) [0|1] ""  EVCU2,IDCM,SGW,HCP
 SG_ SourceNodeIdentifier_1E384046 : 7|8@0+ (1,0) [0|255] "-"  EVCU2,IDCM,SGW,HCP
 SG_ CBV_bit0_RepeatMessageReque_0002 : 8|1@0+ (1,0) [0|1] ""  EVCU2,IDCM,SGW,HCP
 SG_ CBV_bit3_NMCoordinatorBit_1_0002 : 11|1@0+ (1,0) [0|1] ""  EVCU2,IDCM,SGW,HCP
 SG_ CBV_bit4_ActiveWakeupBit_1E38404 : 12|1@0+ (1,0) [0|1] ""  EVCU2,IDCM,SGW,HCP
 SG_ CBV_bit6_PartialNtwInfBit_1_0002 : 14|1@0+ (1,0) [0|1] ""  EVCU2,IDCM,SGW,HCP

BO_TX_BU_ 2651930624 : EVCU2,SGW,HCP;
BO_TX_BU_ 1053 : EVCU2,HCP;
BO_TX_BU_ 520 : EVCU2,HCP;
BO_TX_BU_ 1829 : EVCU2,HCP;
BO_TX_BU_ 1827 : EVCU2,HCP;
BO_TX_BU_ 1153 : EVCU2,HCP;
BO_TX_BU_ 753 : IDCM,BPCM;
BO_TX_BU_ 267 : EVCU2,HCP;
BO_TX_BU_ 1840 : BPCM,HCP;
BO_TX_BU_ 750 : EVCU2,HCP;
BO_TX_BU_ 276 : EVCU2,HCP;
BO_TX_BU_ 262 : EVCU2,HCP;
BO_TX_BU_ 258 : EVCU2,HCP;

CM_ "Project_WS25_ProjectStandard_FD-CAN11 [CS00155_FD]";
CM_ SG_ 2564554481 N_PDU_18DBFEF1 "This signal is used for diagnostic purposes";
CM_ SG_ 2564502513 N_PDU_18DB33F1 "This signal is used for diagnostic purposes";
CM_ SG_ 2564485444 N_PDU_18DAF144 "This signal is used for diagnostic purposes";
CM_ SG_ 2564441329 N_PDU_18DA44F1 "This signal is used for diagnostic purposes";
CM_ SG_ 2564485451 N_PDU_18DAF14B "This signal is used for diagnostic purposes";
CM_ SG_ 2564443121 N_PDU_18DA4BF1 "This signal is used for diagnostic purposes";
CM_ SG_ 2564485456 N_PDU_18DAF150 "This signal is used for diagnostic purposes";
CM_ SG_ 2564444401 N_PDU_18DA50F1 "This signal is used for diagnostic purposes";
CM_ SG_ 1053 VIN_MSG "VIN Message Information";
CM_ SG_ 1053 VIN_DATA "VIN Digits (8 bit ascii encoded)";
CM_ SG_ 520 GearEngagedForDisplay "Transmission Gear engaged signal for Display on cluster.";
CM_ SG_ 156 GPS_UTC_Second "GPS UTC second";
CM_ SG_ 156 GPS_UTC_Minute "GPS UTC minute";
CM_ SG_ 156 GPS_UTC_Hour "GPS UTC hour";
CM_ SG_ 156 GPS_Date_Year "GPS date year";
CM_ SG_ 156 GPS_Date_Month "GPS date month";
CM_ SG_ 156 GPS_Date_Day "GPS date day";
CM_ SG_ 1058 CARB_PERM "Fault code for diagnostics.";
CM_ SG_ 1058 OAT_PT_EstV "Outside air temperature powertrain estimated validity; Invalid = [1]";
CM_ SG_ 1058 OAT_PT_Est "Outside air temperature powertrain estimated";
CM_ SG_ 1829 TotalOdometer "Used to give information about the total odometer value in km.";
CM_ SG_ 1626 IMPACTConfirm "This signal is used to confirm that a crash happened";
CM_ SG_ 1626 IMPACTCommand "This signal is used to indicate that a crash happened";
CM_ SG_ 2564554482 N_PDU_18DBFEF2 "This signal is used for diagnostic purposes";
CM_ SG_ 609 EPBSts "0";
CM_ SG_ 1153 ExternalTemperatureC "Used to indicate the external temperature value in °C";
CM_ SG_ 1153 CmdIgnSts "Used to give information about the key selector position";
CM_ SG_ 1373 DCDC_OutputPower "APM output power";
CM_ SG_ 1373 LVDC_LowVoltageSts "Low voltage at LV side";
CM_ SG_ 1373 LVDC_HighVoltageSts "High voltage at LV side";
CM_ SG_ 1373 LVDC_HighCurrentSts "High current at LV side";
CM_ SG_ 1373 HVDC_OvervoltageSts "over voltage at HV";
CM_ SG_ 1373 DCDC_Utilization "Utilization of DCDC output power capability";
CM_ SG_ 1373 DCDC_TotalOperatingTime "APM total operating time in hours";
CM_ SG_ 1373 DCDC_InputPower "APM input power";
CM_ SG_ 1373 DCDC_DeratingReason "APM Derating";
CM_ SG_ 1373 DCDC_DeratingPower "Available power during derating mode";
CM_ SG_ 1373 DCDC_DeratingModeSts "APM Derating status during operation";
CM_ SG_ 1373 DCDC_CurrentCycleTime "APM current cycle time";
CM_ SG_ 1373 DCDC_BatteryFeedVoltage "Battery feed voltage";
CM_ SG_ 1030 DCDC_FailureReason "FailureReason";
CM_ SG_ 1030 LVDC_VoltageSetpointFdbk "setpoint of low voltage";
CM_ SG_ 1030 LVDC_CurrentSetpointFdbk "APM LV  Current set point feedback";
CM_ SG_ 1030 HVDC_VoltageSetpointFdbk "APM HV  Voltage set point feedback";
CM_ SG_ 1030 HVDC_CurrentSetpointFdbk "Feedback of set point high voltage current";
CM_ SG_ 1030 DCDC_InternalMode "APM internal mode status";
CM_ SG_ 1030 DCDC_FailureType "APM Failure type";
CM_ SG_ 1030 DCDC_EstimatedPowerLoss "Estimated Power Loss";
CM_ SG_ 753 LVDC_CurrentFeedback "Low side current feedback";
CM_ SG_ 753 DCDC_OperationModeSts "APM Operation  mode  Status";
CM_ SG_ 753 MessageCounter_LV_CHARGER1 "This signal is a counter used for safety checks strategies. This counter is incremented of 1 (one) unit at each frame transmission.";
CM_ SG_ 753 CRC_LV_CHARGER1 "CRC according to SAE J1850 standard at each frame transmission.";
CM_ SG_ 753 LVDC_VoltageFeedback "Low side voltage feedback";
CM_ SG_ 753 HVDC_VoltageFeedback "High side  voltage feedback";
CM_ SG_ 753 HVDC_CurrentFeedback "High side current feedback";
CM_ SG_ 753 IDCM_Wakeup_HCP "IDCM wakeup event for charging";
CM_ SG_ 752 IBS3_Vbatt "Battery voltage measured at the terminals";
CM_ SG_ 267 MessageCounter_HYBRID_SYSTEM_EPT "This signal is a counter used for safety checks strategies. This counter is incremented of 1 (one) unit at each frame transmission.";
CM_ SG_ 267 LOC_DiagEnable_ePT ".";
CM_ SG_ 267 HybridDriveModeSts "Drive mode select switch status (from CAN C).";
CM_ SG_ 267 HCP_ShutdownCommand "HCP System Shutdown Command";
CM_ SG_ 267 CRC_HYBRID_SYSTEM_EPT1 "CRC according to SAE J1850 standard at each frame transmission.";
CM_ SG_ 267 WU_Timer_Value "HCP wake-up timer value";
CM_ SG_ 267 PerWakeUp_Diag "Periodic wakeup diagnostics";
CM_ SG_ 267 PropulsionSystemActive_10B "Propulsion system active, [1] = active";
CM_ SG_ 1956 MotorB_Temperature "Motor B temperature";
CM_ SG_ 1956 MotorB_RPM "Motor B Speed Raw";
CM_ SG_ 1956 MotorB_InverterTemp "Inverter B Temperature";
CM_ SG_ 1956 MotorB_DC_Voltage "Motor B DC Voltage";
CM_ SG_ 1956 MotorB_DC_Current "Motor B DC Current";
CM_ SG_ 1956 MotorA_Temperature "Motor A temperature";
CM_ SG_ 1956 MotorA_RPM "Motor A Speed Raw";
CM_ SG_ 1956 MotorA_InverterTemp "Inverter A Temperature";
CM_ SG_ 1956 MotorA_DC_Voltage "Motor A DC Voltage";
CM_ SG_ 1956 MotorA_DC_Current "Motor A DC Current";
CM_ SG_ 1956 Warning_MotorB_Overtemp "Motor B over-temperature warning";
CM_ SG_ 1956 Warning_MotorA_Overtemp "Motor A over-temperature warning";
CM_ SG_ 1956 Warning_InverterA_Overtemp "Motor A inverter over-temperature warning";
CM_ SG_ 1956 Warning_DCDCTemp_DPT "APM temperature warning";
CM_ SG_ 1956 Warning_DCDCPerformance_DPT "APM performance warning";
CM_ SG_ 1956 MotorB_InverterState "Inverter State of Operation";
CM_ SG_ 1956 MotorA_InverterState "Inverter State of Operation";
CM_ SG_ 1956 Warning_InverterB_Overtemp "Motor B inverter over-temperature warning";
CM_ SG_ 1956 MotorB_TorqueAchieved "Motor B Torque Achieved";
CM_ SG_ 1956 MotorA_TorqueAchieved "Motor A Torque Achieved";
CM_ SG_ 1033 MCP_DC_Current "MCP DC Current for BPCM";
CM_ SG_ 1033 MCP_DC_CurrentV "MCP DC Current validity for BPCM";
CM_ SG_ 1834 HVBattery_RealTimeClockV "-";
CM_ SG_ 1834 HVBattery_RealTimeClock "32 bit Real Time Clock";
CM_ SG_ 1834 HVBatteryBalanceMode "Balance mode in progress";
CM_ SG_ 1834 HVBatteryBalanceComplete "Battery Balance complete...";
CM_ SG_ 1834 HVBatCellOCVoltage_MinV "Cell open circuit voltage minimum validity; Invalid = [1]";
CM_ SG_ 1834 HVBatCellOCVoltage_Min "Cell Open Circuit Voltage Minimum";
CM_ SG_ 1834 HVBatCellOCVoltage_MaxV "Cell open circuit voltage maximum validity; Invalid = [1]";
CM_ SG_ 1834 HVBatCellOCVoltage_Max "Cell Open Circuit Voltage Maximum";
CM_ SG_ 1834 HVBatCellOCVoltage_AverageV "Cell open circuit voltage average validity; Invalid = [1]";
CM_ SG_ 1834 HVBatCellOCVoltage_Average "Cell Open Circuit Voltage Average";
CM_ SG_ 1834 HVBatCellDischargeImped_Min "Minimum cell discharge impedance";
CM_ SG_ 1834 HVBatCellDischargeImped_Max "Maximum Cell disCharge Impedance";
CM_ SG_ 1029 HVBatPowerLimited "Limp Home Mode Enabled";
CM_ SG_ 1029 BSGDischargePower_ShortV "High Voltage Battery Discharge Power Short Validity, 2 seconds; Invalid = [1]";
CM_ SG_ 1029 BSGDischargePower_Short "High Voltage Battery Discharge Power Short, 2 seconds";
CM_ SG_ 1029 BSGDischargePower_LongV "High Voltage Battery Discharge Power Long Validity, 10 seconds; Invalid = [1]";
CM_ SG_ 1029 BSGDischargePower_Long "High Voltage Battery Discharge Power Long, 10 seconds";
CM_ SG_ 1029 BSGDischargePower_InstantV "High Voltage Battery Discharge Power Instant Validity, 0.5 seconds; Invalid = [1]";
CM_ SG_ 1029 BSGDischargePower_Instant "High Voltage Battery Discharge Power Instant, 0.5 seconds";
CM_ SG_ 1029 BSGChargePower_ShortV "High Voltage Battery Charge Power Short Validity, 2 seconds; Invalid = [1]";
CM_ SG_ 1029 BSGChargePower_Short "High Voltage Battery Charge Power Short, 2 seconds";
CM_ SG_ 1029 BSGChargePower_LongV "High Voltage Battery Charge Power Validity, 10 seconds; Invalid = [1]";
CM_ SG_ 1029 BSGChargePower_Long "High Voltage Battery Charge Power Long, 10 seconds";
CM_ SG_ 1029 BSGChargePower_InstantV "High Voltage Battery Charge Power Instant Validity, 0.5 seconds; Invalid = [1]";
CM_ SG_ 1029 BSGChargePower_Instant "High Voltage Battery Charge Power Instant, 0.5 seconds";
CM_ SG_ 1027 HVBatterySOCV "High voltage battery state of charge validity. 0-Valid, 1-Invalid.";
CM_ SG_ 1027 HVBatterySOC "High voltage battery pack state of charge";
CM_ SG_ 1027 HVBatteryMILRequest "MIL Lamp request from BPCM.";
CM_ SG_ 1027 HVBatterySOH "HV Battery percentage of State of Health.  Last-Known value to be stored in EEPROM.";
CM_ SG_ 1027 HVBatterySOC_Min "Minimum HV battery cell state of charge";
CM_ SG_ 1027 HVBatterySOC_Max "Maximum HV battery cell state of charge";
CM_ SG_ 1027 HVBatteryServiceRequest "Ev service On request from BPCM";
CM_ SG_ 1027 PrechargePenaltyTimer "Precharge Penalty Timer";
CM_ SG_ 266 HVBatteryCurrent "High voltage Battery pack current...";
CM_ SG_ 266 HVBatContactorSts "HV Battery pack contactor state";
CM_ SG_ 266 HVBatCellVoltage_NumMax "Cell number - maximum voltage";
CM_ SG_ 266 HVBatCellVoltage_Min "Min cell voltage";
CM_ SG_ 266 HVBatCellVoltage_Max "Max cell voltage";
CM_ SG_ 266 HVBatteryVoltageV "High voltage battery pack voltage validity; Invalid = [1]";
CM_ SG_ 266 HVBatteryReady "High Voltage Battery Ready";
CM_ SG_ 266 HVBatteryCurrentV "High voltage battery pack current valid; Invalid = [1]";
CM_ SG_ 266 HVBatContactorReq "HV Battery pack contactor request";
CM_ SG_ 266 HVBatContactorOpen "HV Battery Pack contactor Open";
CM_ SG_ 266 HVBatCellVoltage_MinV "Min cell voltage valid; Invalid = [1]";
CM_ SG_ 266 HVBatCellVoltage_MaxV "Max cell voltage valid; Invalid = [1]";
CM_ SG_ 266 HVBatCellVoltage_AverageV "Average cell voltage valid; Invalid = [1]";
CM_ SG_ 266 HVBatCellVoltage_Average "Average cell voltage";
CM_ SG_ 266 HVBatteryVoltage_BSG "High voltage battery pack voltage";
CM_ SG_ 266 HVBatCellVoltage_NumMin "Cell number - minimum voltage";
CM_ SG_ 266 HVBatShutdownReady "High voltage battery pack shutdown readiness status.";
CM_ SG_ 266 HVBatContactorWelded "Contactor welded and has impeded opening when commanded by BPCM.";
CM_ SG_ 1034 HVBatModuleTemp_MinV "HV battery pack minimum temperature validity; Invalid = [1]";
CM_ SG_ 1034 HVBatModuleTemp_Min "HV Battery pack Minimum temperature";
CM_ SG_ 1034 HVBatModuleTemp_MaxV "HV battery pack maximum temperature validity; Invalid = [1]";
CM_ SG_ 1034 HVBatModuleTemp_Max "HV Battery pack Maximum temperature";
CM_ SG_ 1034 HVBatSleepTime "Time since BPCM last went to sleep.";
CM_ SG_ 1034 HVBatModuleTemp_AverageV "HV battery pack average temperature validity; Invalid = [1]";
CM_ SG_ 1034 HVBatModuleTemp_Average "HV Battery pack average temperature";
CM_ SG_ 1034 HVBatLowTempThreshold "High Voltage Battery low Temperature Threshold";
CM_ SG_ 1034 HVBatHighTempThreshold "High Voltage Battery High Temperature Threshold";
CM_ SG_ 1034 HVBatModuleTemp_NumMin "Module number - minimum temperature";
CM_ SG_ 1034 HVBatModuleTemp_NumMax "Module number - maximum temperature";
CM_ SG_ 1839 HVBatModuleTemp_16 "High voltage battery module temperature";
CM_ SG_ 1839 HVBatModuleTemp_15 "High voltage battery module temperature";
CM_ SG_ 1839 HVBatModuleTemp_14 "High voltage battery module temperature";
CM_ SG_ 1839 HVBatModuleTemp_13 "High voltage battery module temperature";
CM_ SG_ 1839 HVBatModuleTemp_12 "High voltage battery module temperature";
CM_ SG_ 1839 HVBatModuleTemp_11 "High voltage battery module temperature";
CM_ SG_ 1839 HVBatModuleTemp_10 "High voltage battery module temperature";
CM_ SG_ 1839 HVBatModuleTemp_09 "High voltage battery module temperature";
CM_ SG_ 1839 HVBatModuleTemp_08 "High voltage battery module temperature";
CM_ SG_ 1839 HVBatModuleTemp_07 "High voltage battery module temperature";
CM_ SG_ 1839 HVBatModuleTemp_06 "High voltage battery module temperature";
CM_ SG_ 1839 HVBatModuleTemp_05 "High voltage battery module temperature";
CM_ SG_ 1839 HVBatModuleTemp_04 "High voltage battery module temperature";
CM_ SG_ 1839 HVBatModuleTemp_03 "High voltage battery module temperature";
CM_ SG_ 1839 HVBatModuleTemp_02 "High voltage battery module temperature";
CM_ SG_ 1839 HVBatModuleTemp_01 "High voltage battery module temperature";
CM_ SG_ 1839 HVBatModuleTemp_38 "High voltage battery module temperature";
CM_ SG_ 1839 HVBatModuleTemp_37 "High voltage battery module temperature";
CM_ SG_ 1839 HVBatModuleTemp_36 "High voltage battery module temperature";
CM_ SG_ 1839 HVBatModuleTemp_35 "High voltage battery module temperature";
CM_ SG_ 1839 HVBatModuleTemp_34 "High voltage battery module temperature";
CM_ SG_ 1839 HVBatModuleTemp_33 "High voltage battery module temperature";
CM_ SG_ 1839 HVBatModuleTemp_32 "High voltage battery module temperature";
CM_ SG_ 1839 HVBatModuleTemp_31 "High voltage battery module temperature";
CM_ SG_ 1839 HVBatModuleTemp_30 "High voltage battery module temperature";
CM_ SG_ 1839 HVBatModuleTemp_29 "High voltage battery module temperature";
CM_ SG_ 1839 HVBatModuleTemp_28 "High voltage battery module temperature";
CM_ SG_ 1839 HVBatModuleTemp_27 "High voltage battery module temperature";
CM_ SG_ 1839 HVBatModuleTemp_26 "High voltage battery module temperature";
CM_ SG_ 1839 HVBatModuleTemp_25 "High voltage battery module temperature";
CM_ SG_ 1839 HVBatModuleTemp_24 "High voltage battery module temperature";
CM_ SG_ 1839 HVBatModuleTemp_23 "High voltage battery module temperature";
CM_ SG_ 1839 HVBatModuleTemp_22 "High voltage battery module temperature";
CM_ SG_ 1839 HVBatModuleTemp_21 "High voltage battery module temperature";
CM_ SG_ 1839 HVBatModuleTemp_20 "High voltage battery module temperature";
CM_ SG_ 1839 HVBatModuleTemp_19 "High voltage battery module temperature";
CM_ SG_ 1839 HVBatModuleTemp_18 "High voltage battery module temperature";
CM_ SG_ 1839 HVBatModuleTemp_17 "High voltage battery module temperature";
CM_ SG_ 1840 IsolationResistance "Insulation resistance";
CM_ SG_ 1840 Warning_SOCJump "Battery SOC jump warning";
CM_ SG_ 1840 Warning_PackUnmatched "Battery unmatched warning";
CM_ SG_ 1840 Warning_PackUndervoltage "Battery undervoltage warning";
CM_ SG_ 1840 Warning_PackTempHigh "Battery high temperature warning";
CM_ SG_ 1840 Warning_PackTempDiff "Temperature difference warning";
CM_ SG_ 1840 Warning_PackOvervoltage "Battery overvoltage warning";
CM_ SG_ 1840 Warning_Overcharging "Overcharge warning";
CM_ SG_ 1840 Warning_LowSOC "Battery low SOC warning";
CM_ SG_ 1840 Warning_Insulation "Insulation warning";
CM_ SG_ 1840 Warning_HVIL "HV interlock state warning";
CM_ SG_ 1840 Warning_HighSOC "Battery high SOC warning";
CM_ SG_ 1840 Warning_CellUndervoltage "Cell undervoltage warning";
CM_ SG_ 1840 Warning_CellOvervoltage "Cell overvoltage warning";
CM_ SG_ 1840 Warning_CellBalance "Poor cell consistency warning";
CM_ SG_ 1840 HighestWarningLevel "Highest warning level detected";
CM_ SG_ 1838 HVBatCellVoltage_Cell096 "High voltage battery cell voltage for Cell 96";
CM_ SG_ 1838 HVBatCellVoltage_Cell095 "High voltage battery cell voltage for Cell 95";
CM_ SG_ 1838 HVBatCellVoltage_Cell094 "High voltage battery cell voltage for Cell 94";
CM_ SG_ 1838 HVBatCellVoltage_Cell093 "High voltage battery cell voltage for Cell 93";
CM_ SG_ 1838 HVBatCellVoltage_Cell092 "High voltage battery cell voltage for Cell 92";
CM_ SG_ 1838 HVBatCellVoltage_Cell091 "High voltage battery cell voltage for Cell 91";
CM_ SG_ 1838 HVBatCellVoltage_Cell090 "High voltage battery cell voltage for Cell 90";
CM_ SG_ 1838 HVBatCellVoltage_Cell089 "High voltage battery cell voltage for Cell 89";
CM_ SG_ 1838 HVBatCellVoltage_Cell088 "High voltage battery cell voltage for Cell 88";
CM_ SG_ 1838 HVBatCellVoltage_Cell087 "High voltage battery cell voltage for Cell 87";
CM_ SG_ 1838 HVBatCellVoltage_Cell086 "High voltage battery cell voltage for Cell 86";
CM_ SG_ 1838 HVBatCellVoltage_Cell085 "High voltage battery cell voltage for Cell 85";
CM_ SG_ 1838 HVBatCellVoltage_Cell084 "High voltage battery cell voltage for Cell 84";
CM_ SG_ 1838 HVBatCellVoltage_Cell083 "High voltage battery cell voltage for Cell 83";
CM_ SG_ 1838 HVBatCellVoltage_Cell082 "High voltage battery cell voltage for Cell 82";
CM_ SG_ 1838 HVBatCellVoltage_Cell108 "High voltage battery cell voltage for Cell 108";
CM_ SG_ 1838 HVBatCellVoltage_Cell107 "High voltage battery cell voltage for Cell 107";
CM_ SG_ 1838 HVBatCellVoltage_Cell106 "High voltage battery cell voltage for Cell 106";
CM_ SG_ 1838 HVBatCellVoltage_Cell105 "High voltage battery cell voltage for Cell 105";
CM_ SG_ 1838 HVBatCellVoltage_Cell104 "High voltage battery cell voltage for Cell 104";
CM_ SG_ 1838 HVBatCellVoltage_Cell103 "High voltage battery cell voltage for Cell 103";
CM_ SG_ 1838 HVBatCellVoltage_Cell102 "High voltage battery cell voltage for Cell 102";
CM_ SG_ 1838 HVBatCellVoltage_Cell101 "High voltage battery cell voltage for Cell 101";
CM_ SG_ 1838 HVBatCellVoltage_Cell100 "High voltage battery cell voltage for Cell 100";
CM_ SG_ 1838 HVBatCellVoltage_Cell099 "High voltage battery cell voltage for Cell 99";
CM_ SG_ 1838 HVBatCellVoltage_Cell098 "High voltage battery cell voltage for Cell 98";
CM_ SG_ 1838 HVBatCellVoltage_Cell097 "High voltage battery cell voltage for Cell 97";
CM_ SG_ 1837 HVBatCellVoltage_Cell081 "High voltage battery cell voltage for Cell 81";
CM_ SG_ 1837 HVBatCellVoltage_Cell080 "High voltage battery cell voltage for Cell 80";
CM_ SG_ 1837 HVBatCellVoltage_Cell079 "High voltage battery cell voltage for Cell 79";
CM_ SG_ 1837 HVBatCellVoltage_Cell078 "High voltage battery cell voltage for Cell 78";
CM_ SG_ 1837 HVBatCellVoltage_Cell077 "High voltage battery cell voltage for Cell 77";
CM_ SG_ 1837 HVBatCellVoltage_Cell076 "High voltage battery cell voltage for Cell 76";
CM_ SG_ 1837 HVBatCellVoltage_Cell075 "High voltage battery cell voltage for Cell 75";
CM_ SG_ 1837 HVBatCellVoltage_Cell074 "High voltage battery cell voltage for Cell 74";
CM_ SG_ 1837 HVBatCellVoltage_Cell073 "High voltage battery cell voltage for Cell 73";
CM_ SG_ 1837 HVBatCellVoltage_Cell072 "High voltage battery cell voltage for Cell 72";
CM_ SG_ 1837 HVBatCellVoltage_Cell071 "High voltage battery cell voltage for Cell 71";
CM_ SG_ 1837 HVBatCellVoltage_Cell070 "High voltage battery cell voltage for Cell 70";
CM_ SG_ 1837 HVBatCellVoltage_Cell069 "High voltage battery cell voltage for Cell 69";
CM_ SG_ 1837 HVBatCellVoltage_Cell068 "High voltage battery cell voltage for Cell 68";
CM_ SG_ 1837 HVBatCellVoltage_Cell067 "High voltage battery cell voltage for Cell 67";
CM_ SG_ 1837 HVBatCellVoltage_Cell066 "High voltage battery cell voltage for Cell 66";
CM_ SG_ 1837 HVBatCellVoltage_Cell065 "High voltage battery cell voltage for Cell 65";
CM_ SG_ 1837 HVBatCellVoltage_Cell064 "High voltage battery cell voltage for Cell 64";
CM_ SG_ 1837 HVBatCellVoltage_Cell063 "High voltage battery cell voltage for Cell 63";
CM_ SG_ 1837 HVBatCellVoltage_Cell062 "High voltage battery cell voltage for Cell 62";
CM_ SG_ 1837 HVBatCellVoltage_Cell061 "High voltage battery cell voltage for Cell 61";
CM_ SG_ 1837 HVBatCellVoltage_Cell060 "High voltage battery cell voltage for Cell 60";
CM_ SG_ 1837 HVBatCellVoltage_Cell059 "High voltage battery cell voltage for Cell 59";
CM_ SG_ 1837 HVBatCellVoltage_Cell058 "High voltage battery cell voltage for Cell 58";
CM_ SG_ 1837 HVBatCellVoltage_Cell057 "High voltage battery cell voltage for Cell 57";
CM_ SG_ 1837 HVBatCellVoltage_Cell056 "High voltage battery cell voltage for Cell 56";
CM_ SG_ 1837 HVBatCellVoltage_Cell055 "High voltage battery cell voltage for Cell 55";
CM_ SG_ 1836 HVBatCellVoltage_Cell054 "High voltage battery cell voltage for Cell 54";
CM_ SG_ 1836 HVBatCellVoltage_Cell053 "High voltage battery cell voltage for Cell 53";
CM_ SG_ 1836 HVBatCellVoltage_Cell052 "High voltage battery cell voltage for Cell 52";
CM_ SG_ 1836 HVBatCellVoltage_Cell051 "High voltage battery cell voltage for Cell 51";
CM_ SG_ 1836 HVBatCellVoltage_Cell050 "High voltage battery cell voltage for Cell 50";
CM_ SG_ 1836 HVBatCellVoltage_Cell049 "High voltage battery cell voltage for Cell 49";
CM_ SG_ 1836 HVBatCellVoltage_Cell048 "High voltage battery cell voltage for Cell 48";
CM_ SG_ 1836 HVBatCellVoltage_Cell047 "High voltage battery cell voltage for Cell 47";
CM_ SG_ 1836 HVBatCellVoltage_Cell046 "High voltage battery cell voltage for Cell 46";
CM_ SG_ 1836 HVBatCellVoltage_Cell045 "High voltage battery cell voltage for Cell 45";
CM_ SG_ 1836 HVBatCellVoltage_Cell044 "High voltage battery cell voltage for Cell 44";
CM_ SG_ 1836 HVBatCellVoltage_Cell043 "High voltage battery cell voltage for Cell 43";
CM_ SG_ 1836 HVBatCellVoltage_Cell042 "High voltage battery cell voltage for Cell 42";
CM_ SG_ 1836 HVBatCellVoltage_Cell041 "High voltage battery cell voltage for Cell 41";
CM_ SG_ 1836 HVBatCellVoltage_Cell040 "High voltage battery cell voltage for Cell 40";
CM_ SG_ 1836 HVBatCellVoltage_Cell039 "High voltage battery cell voltage for Cell 39";
CM_ SG_ 1836 HVBatCellVoltage_Cell038 "High voltage battery cell voltage for Cell 38";
CM_ SG_ 1836 HVBatCellVoltage_Cell037 "High voltage battery cell voltage for Cell 37";
CM_ SG_ 1836 HVBatCellVoltage_Cell036 "High voltage battery cell voltage for Cell 36";
CM_ SG_ 1836 HVBatCellVoltage_Cell035 "High voltage battery cell voltage for Cell 35";
CM_ SG_ 1836 HVBatCellVoltage_Cell034 "High voltage battery cell voltage for Cell 34";
CM_ SG_ 1836 HVBatCellVoltage_Cell033 "High voltage battery cell voltage for Cell 33";
CM_ SG_ 1836 HVBatCellVoltage_Cell032 "High voltage battery cell voltage for Cell 32";
CM_ SG_ 1836 HVBatCellVoltage_Cell031 "High voltage battery cell voltage for Cell 31";
CM_ SG_ 1836 HVBatCellVoltage_Cell030 "High voltage battery cell voltage for Cell 30";
CM_ SG_ 1836 HVBatCellVoltage_Cell029 "High voltage battery cell voltage for Cell 29";
CM_ SG_ 1836 HVBatCellVoltage_Cell028 "High voltage battery cell voltage for Cell 28";
CM_ SG_ 1835 HVBatCellVoltage_Cell027 "High voltage battery cell voltage for Cell 27";
CM_ SG_ 1835 HVBatCellVoltage_Cell026 "High voltage battery cell voltage for Cell 26";
CM_ SG_ 1835 HVBatCellVoltage_Cell025 "High voltage battery cell voltage for Cell 25";
CM_ SG_ 1835 HVBatCellVoltage_Cell024 "High voltage battery cell voltage for Cell 24";
CM_ SG_ 1835 HVBatCellVoltage_Cell023 "High voltage battery cell voltage for Cell 23";
CM_ SG_ 1835 HVBatCellVoltage_Cell022 "High voltage battery cell voltage for Cell 22";
CM_ SG_ 1835 HVBatCellVoltage_Cell021 "High voltage battery cell voltage for Cell 21";
CM_ SG_ 1835 HVBatCellVoltage_Cell020 "High voltage battery cell voltage for Cell 20";
CM_ SG_ 1835 HVBatCellVoltage_Cell019 "High voltage battery cell voltage for Cell 19";
CM_ SG_ 1835 HVBatCellVoltage_Cell018 "High voltage battery cell voltage for Cell 18";
CM_ SG_ 1835 HVBatCellVoltage_Cell017 "High voltage battery cell voltage for Cell 17";
CM_ SG_ 1835 HVBatCellVoltage_Cell016 "High voltage battery cell voltage for Cell 16";
CM_ SG_ 1835 HVBatCellVoltage_Cell015 "High voltage battery cell voltage for Cell 15";
CM_ SG_ 1835 HVBatCellVoltage_Cell014 "High voltage battery cell voltage for Cell 14";
CM_ SG_ 1835 HVBatCellVoltage_Cell013 "High voltage battery cell voltage for Cell 13";
CM_ SG_ 1835 HVBatCellVoltage_Cell012 "High voltage battery cell voltage for Cell 12";
CM_ SG_ 1835 HVBatCellVoltage_Cell011 "High voltage battery cell voltage for Cell 11";
CM_ SG_ 1835 HVBatCellVoltage_Cell010 "High voltage battery cell voltage for Cell 10";
CM_ SG_ 1835 HVBatCellVoltage_Cell009 "High voltage battery cell voltage for Cell 09";
CM_ SG_ 1835 HVBatCellVoltage_Cell008 "High voltage battery cell voltage for Cell 08";
CM_ SG_ 1835 HVBatCellVoltage_Cell007 "High voltage battery cell voltage for Cell 07";
CM_ SG_ 1835 HVBatCellVoltage_Cell006 "High voltage battery cell voltage for Cell 06";
CM_ SG_ 1835 HVBatCellVoltage_Cell005 "High voltage battery cell voltage for Cell 05";
CM_ SG_ 1835 HVBatCellVoltage_Cell004 "High voltage battery cell voltage for Cell 04";
CM_ SG_ 1835 HVBatCellVoltage_Cell003 "High voltage battery cell voltage for Cell 03";
CM_ SG_ 1835 HVBatCellVoltage_Cell002 "High voltage battery cell voltage for Cell 02";
CM_ SG_ 1835 HVBatCellVoltage_Cell001 "High voltage battery cell voltage for Cell 01";
CM_ SG_ 1035 RadFanReq "Radiator Fan request";
CM_ SG_ 1035 EngSpd "Engine speed";
CM_ SG_ 1035 EngCltTmpV "Engine Coolant Temperature Validity";
CM_ SG_ 1035 EngCltTmp "Engine Coolant Temp";
CM_ SG_ 750 Battery_Volt_1 "Battery Volt 1 signal";
CM_ SG_ 1436 Blower_Speed "Frequency Feedback received from the Blower";
CM_ SG_ 2654486640 SourceNodeIdentifier_1E384070 "Source Node Identifier";
CM_ SG_ 2654486640 CBV_bit0_RepeatMessageRequestBit "Repeat Message Request Bit";
CM_ SG_ 2654486640 CBV_bit3_NMCoordinatorBit_1E3840 "NM Coordinator Sleep Bit";
CM_ SG_ 2654486640 CBV_bit4_ActiveWakeupBit_1E38407 "Active Wakeup Bit";
CM_ SG_ 2654486640 CBV_bit6_PartialNtwInfBit_1E3840 "Partial Network Information Bit (PNI)";
CM_ SG_ 2654486626 SourceNodeIdentifier_1E384062 "Source Node Identifier";
CM_ SG_ 2654486626 CBV_bit0_RepeatMessageReque_0000 "Repeat Message Request Bit";
CM_ SG_ 2654486626 CBV_bit3_NMCoordinatorBit_1_0000 "NM Coordinator Sleep Bit";
CM_ SG_ 2654486626 CBV_bit4_ActiveWakeupBit_1E38406 "Active Wakeup Bit";
CM_ SG_ 2654486626 CBV_bit6_PartialNtwInfBit_1_0000 "Partial Network Information Bit (PNI)";
CM_ SG_ 276 HEV_ESS_Mode "Engine start stop information:  engine start stop mode";
CM_ SG_ 276 PropulsionSystemActive_114 "Propulsion system active, [1] = active";
CM_ SG_ 262 PowertrainPrplsnActv "Powertrain Propulsion Status.";
CM_ SG_ 262 EngineSpeed_W "It gives information on C-CAN network about  engine speed";
CM_ SG_ 258 VehicleSpeedVSOSig "It is the average vehicle speed calculated.";
CM_ SG_ 2654486653 SourceNodeIdentifier_1E38407D "Source Node Identifier";
CM_ SG_ 2654486653 CBV_bit0_RepeatMessageReque_0001 "Repeat Message Request Bit";
CM_ SG_ 2654486653 CBV_bit3_NMCoordinatorBit_1_0001 "NM Coordinator Sleep Bit";
CM_ SG_ 2654486653 CBV_bit4_ActiveWakeupBit_1E_0000 "Active Wakeup Bit";
CM_ SG_ 2654486653 CBV_bit6_PartialNtwInfBit_1_0001 "Partial Network Information Bit (PNI)";
CM_ SG_ 2654486598 SourceNodeIdentifier_1E384046 "Source Node Identifier";
CM_ SG_ 2654486598 CBV_bit0_RepeatMessageReque_0002 "Repeat Message Request Bit";
CM_ SG_ 2654486598 CBV_bit3_NMCoordinatorBit_1_0002 "NM Coordinator Sleep Bit";
CM_ SG_ 2654486598 CBV_bit4_ActiveWakeupBit_1E38404 "Active Wakeup Bit";
CM_ SG_ 2654486598 CBV_bit6_PartialNtwInfBit_1_0002 "Partial Network Information Bit (PNI)";
BA_DEF_ SG_  "GenSigTimeoutTime_HCP" INT 0 65535;
BA_DEF_ SG_  "GenSigTimeoutTime_PPIM" INT 0 65535;
BA_DEF_ SG_  "GenSigStartValue" INT 0 2147483647;
BA_DEF_ SG_  "GenSigInactiveValue" INT 0 2147483647;
BA_DEF_ SG_  "GenSigSendType" ENUM  "NotUsed","OnWrite","OnWriteWithRepetition","OnChange","OnChangeWithRepetition","IfActive","IfActiveWithRepetition","NoSigSendType";
BA_DEF_ SG_  "GenSigTimeoutTime_BPCM" INT 0 65535;
BA_DEF_ SG_  "GenSigTimeoutTime_EVCU2" INT 0 65535;
BA_DEF_ SG_  "GenSigTimeoutTime_IDCM" INT 0 65535;
BA_DEF_ SG_  "GenSigTimeoutTime_SGW" INT 0 65535;
BA_DEF_ BO_  "DiagRequest" ENUM  "No","Yes";
BA_DEF_ BO_  "Type" ENUM  "P","C","PE","COC","PE_Cntrl","E","E_Cntrl","OC","S","BAF","DC","EM","MM","ISO-TP","-";
BA_DEF_ BO_  "DiagResponse" ENUM  "No","Yes";
BA_DEF_ BO_  "NmMessage" ENUM  "No","Yes";
BA_DEF_ BO_  "GenMsgSendType" ENUM  "Cyclic","NotUsed","NotUsed","NotUsed","NotUsed","NotUsed","NotUsed","NotUsed","NoMsgSendType";
BA_DEF_ BO_  "GenMsgNrOfRepetition" INT 0 255;
BA_DEF_ BO_  "GenMsgILSupport" ENUM  "No","Yes";
BA_DEF_ BO_  "GenMsgStartDelayTime" INT 0 65535;
BA_DEF_ BO_  "GenMsgCycleTimeFast" INT 0 65535;
BA_DEF_ BO_  "GenMsgCycleTime" INT 0 65535;
BA_DEF_ BO_  "GenMsgDelayTime" INT 0 65535;
BA_DEF_ BO_  "NmAsrMessage" ENUM  "No","Yes";
BA_DEF_ BO_  "DiagState" ENUM  "No","Yes";
BA_DEF_ BO_  "DiagConnection" HEX 0 65535;
BA_DEF_ BO_  "CanTpFcFrameId" HEX 0 2147483647;
BA_DEF_ BO_  "VFrameFormat" ENUM  "StandardCAN","ExtendedCAN","reserved","reserved","reserved","reserved","reserved","reserved","reserved","reserved","reserved","reserved","reserved","reserved","StandardCAN_FD","ExtendedCAN_FD";
BA_DEF_ BO_  "CANFD_BRS" ENUM  "0","1";
BA_DEF_  "Manufacturer" STRING ;
BA_DEF_  "NmType" STRING ;
BA_DEF_  "BusType" STRING ;
BA_DEF_  "Baudrate" INT 0 1000000;
BA_DEF_  "DBName" STRING ;
BA_DEF_  "NmAsrTimeoutTime" INT 1 65535;
BA_DEF_  "NmAsrWaitBusSleepTime" INT 1 65535;
BA_DEF_  "NmAsrRepeatMessageTime" INT 1 65535;
BA_DEF_  "NmAsrMessageCount" INT 1 256;
BA_DEF_  "NmAsrBaseAddress" HEX 235487232 2147483647;
BA_DEF_  "NmAsrCanMsgCycleTime" INT 1 65535;
BA_DEF_  "Version" HEX 0 255;
BA_DEF_  "VersionWeek" INT 0 53;
BA_DEF_  "VersionYear" INT 0 99;
BA_DEF_ BU_  "Description" STRING ;
BA_DEF_ BU_  "NmStationAddress" HEX 0 255;
BA_DEF_ BU_  "NmNode" ENUM  "No","Yes";
BA_DEF_ BU_  "NmAsrNode" ENUM  "No","Yes";
BA_DEF_ BU_  "NmAsrNodeIdentifier" HEX 0 255;
BA_DEF_ BU_  "NmAsrCanMsgReducedTime" INT 1 65535;
BA_DEF_ BU_  "NmNodeType" ENUM  "+15_NotWakeable","+30_Wakeable","+30_NotWakeable","kMaster","kSlave15","kSlave30","none";
BA_DEF_ BU_  "NwmNodeType" ENUM  "+15_NotWakeable","+30_Wakeable","+30_NotWakeable","kMaster","kSlave15","kSlave30","none";
BA_DEF_ SG_  "SystemSignalLongSymbol" STRING ;
BA_DEF_DEF_  "GenSigTimeoutTime_HCP" 2500;
BA_DEF_DEF_  "GenSigTimeoutTime_PPIM" 2500;
BA_DEF_DEF_  "GenSigStartValue" 0;
BA_DEF_DEF_  "GenSigInactiveValue" 0;
BA_DEF_DEF_  "GenSigSendType" "NoSigSendType";
BA_DEF_DEF_  "GenSigTimeoutTime_BPCM" 2500;
BA_DEF_DEF_  "GenSigTimeoutTime_EVCU2" 2500;
BA_DEF_DEF_  "GenSigTimeoutTime_IDCM" 2500;
BA_DEF_DEF_  "GenSigTimeoutTime_SGW" 2500;
BA_DEF_DEF_  "DiagRequest" "No";
BA_DEF_DEF_  "Type" "-";
BA_DEF_DEF_  "DiagResponse" "No";
BA_DEF_DEF_  "NmMessage" "No";
BA_DEF_DEF_  "GenMsgSendType" "NoMsgSendType";
BA_DEF_DEF_  "GenMsgNrOfRepetition" 0;
BA_DEF_DEF_  "GenMsgILSupport" "No";
BA_DEF_DEF_  "GenMsgStartDelayTime" 0;
BA_DEF_DEF_  "GenMsgCycleTimeFast" 0;
BA_DEF_DEF_  "GenMsgCycleTime" 0;
BA_DEF_DEF_  "GenMsgDelayTime" 0;
BA_DEF_DEF_  "NmAsrMessage" "No";
BA_DEF_DEF_  "DiagState" "No";
BA_DEF_DEF_  "DiagConnection" 0;
BA_DEF_DEF_  "CanTpFcFrameId" 2147483647;
BA_DEF_DEF_  "VFrameFormat" "StandardCAN_FD";
BA_DEF_DEF_  "CANFD_BRS" "0";
BA_DEF_DEF_  "Manufacturer" "Fiat";
BA_DEF_DEF_  "NmType" "";
BA_DEF_DEF_  "BusType" "CAN";
BA_DEF_DEF_  "Baudrate" 500000;
BA_DEF_DEF_  "DBName" "CAN";
BA_DEF_DEF_  "NmAsrTimeoutTime" 1000;
BA_DEF_DEF_  "NmAsrWaitBusSleepTime" 750;
BA_DEF_DEF_  "NmAsrRepeatMessageTime" 800;
BA_DEF_DEF_  "NmAsrMessageCount" 256;
BA_DEF_DEF_  "NmAsrBaseAddress" 506724352;
BA_DEF_DEF_  "NmAsrCanMsgCycleTime" 200;
BA_DEF_DEF_  "Version" 160;
BA_DEF_DEF_  "VersionWeek" 17;
BA_DEF_DEF_  "VersionYear" 23;
BA_DEF_DEF_  "Description" "";
BA_DEF_DEF_  "NmStationAddress" 0;
BA_DEF_DEF_  "NmNode" "Yes";
BA_DEF_DEF_  "NmAsrNode" "Yes";
BA_DEF_DEF_  "NmAsrNodeIdentifier" 0;
BA_DEF_DEF_  "NmAsrCanMsgReducedTime" 100;
BA_DEF_DEF_  "NmNodeType" "none";
BA_DEF_DEF_  "NwmNodeType" "none";
BA_DEF_DEF_  "SystemSignalLongSymbol" "";
BA_ "NmAsrCanMsgCycleTime" 1000;
BA_ "NmAsrBaseAddress" 507002880;
BA_ "NmAsrRepeatMessageTime" 5000;
BA_ "NmAsrWaitBusSleepTime" 1000;
BA_ "NmAsrTimeoutTime" 8000;
BA_ "BusType" "CAN FD";
BA_ "NmType" "NmAsr";
BA_ "DBName" "FDCAN11";
BA_ "NwmNodeType" BU_ PPIM 1;
BA_ "NmNodeType" BU_ PPIM 1;
BA_ "NmAsrCanMsgReducedTime" BU_ PPIM 625;
BA_ "NmAsrNodeIdentifier" BU_ PPIM 214;
BA_ "NmStationAddress" BU_ PPIM 214;
BA_ "Description" BU_ PPIM "Power Panel Inverter Module";
BA_ "NwmNodeType" BU_ HCP 2;
BA_ "NmNodeType" BU_ HCP 2;
BA_ "NmAsrCanMsgReducedTime" BU_ HCP 750;
BA_ "NmAsrNodeIdentifier" BU_ HCP 98;
BA_ "NmStationAddress" BU_ HCP 98;
BA_ "Description" BU_ HCP "Hybrid Control Processor";
BA_ "NwmNodeType" BU_ SGW 1;
BA_ "NmNodeType" BU_ SGW 1;
BA_ "NmAsrCanMsgReducedTime" BU_ SGW 800;
BA_ "NmAsrNodeIdentifier" BU_ SGW 112;
BA_ "NmStationAddress" BU_ SGW 112;
BA_ "Description" BU_ SGW "Security Gateway Module";
BA_ "NwmNodeType" BU_ IDCM 1;
BA_ "NmNodeType" BU_ IDCM 1;
BA_ "NmAsrCanMsgReducedTime" BU_ IDCM 600;
BA_ "NmAsrNodeIdentifier" BU_ IDCM 125;
BA_ "NmStationAddress" BU_ IDCM 125;
BA_ "Description" BU_ IDCM "Integrated Dual Charge Module";
BA_ "NwmNodeType" BU_ EVCU2 1;
BA_ "NmNodeType" BU_ EVCU2 1;
BA_ "NmAsrCanMsgReducedTime" BU_ EVCU2 950;
BA_ "NmAsrNodeIdentifier" BU_ EVCU2 64;
BA_ "NmStationAddress" BU_ EVCU2 64;
BA_ "Description" BU_ EVCU2 "Electric Vehicle Control Unit 2";
BA_ "NwmNodeType" BU_ BPCM 1;
BA_ "NmNodeType" BU_ BPCM 1;
BA_ "NmAsrCanMsgReducedTime" BU_ BPCM 525;
BA_ "NmAsrNodeIdentifier" BU_ BPCM 70;
BA_ "NmStationAddress" BU_ BPCM 70;
BA_ "Description" BU_ BPCM "Battery Pack Control Module";
BA_ "GenMsgCycleTime" BO_ 834 100;
BA_ "VFrameFormat" BO_ 834 0;
BA_ "GenMsgCycleTime" BO_ 835 100;
BA_ "VFrameFormat" BO_ 835 0;
BA_ "CANFD_BRS" BO_ 2651930624 1;
BA_ "GenMsgDelayTime" BO_ 2651930624 10;
BA_ "GenMsgILSupport" BO_ 2651930624 1;
BA_ "Type" BO_ 2651930624 8;
BA_ "VFrameFormat" BO_ 2651930624 15;
BA_ "VFrameFormat" BO_ 2564554481 1;
BA_ "DiagConnection" BO_ 2564554481 61950;
BA_ "DiagState" BO_ 2564554481 1;
BA_ "Type" BO_ 2564554481 8;
BA_ "VFrameFormat" BO_ 2564502513 1;
BA_ "DiagConnection" BO_ 2564502513 61747;
BA_ "DiagState" BO_ 2564502513 1;
BA_ "Type" BO_ 2564502513 8;
BA_ "VFrameFormat" BO_ 2564485444 1;
BA_ "DiagConnection" BO_ 2564485444 61764;
BA_ "DiagResponse" BO_ 2564485444 1;
BA_ "Type" BO_ 2564485444 8;
BA_ "VFrameFormat" BO_ 2564441329 1;
BA_ "DiagConnection" BO_ 2564441329 61764;
BA_ "Type" BO_ 2564441329 8;
BA_ "DiagRequest" BO_ 2564441329 1;
BA_ "VFrameFormat" BO_ 2564485451 1;
BA_ "DiagConnection" BO_ 2564485451 61771;
BA_ "DiagResponse" BO_ 2564485451 1;
BA_ "Type" BO_ 2564485451 8;
BA_ "VFrameFormat" BO_ 2564443121 1;
BA_ "DiagConnection" BO_ 2564443121 61771;
BA_ "Type" BO_ 2564443121 8;
BA_ "DiagRequest" BO_ 2564443121 1;
BA_ "VFrameFormat" BO_ 2564485456 1;
BA_ "DiagConnection" BO_ 2564485456 61776;
BA_ "DiagResponse" BO_ 2564485456 1;
BA_ "Type" BO_ 2564485456 8;
BA_ "VFrameFormat" BO_ 2564444401 1;
BA_ "DiagConnection" BO_ 2564444401 61776;
BA_ "Type" BO_ 2564444401 8;
BA_ "DiagRequest" BO_ 2564444401 1;
BA_ "CANFD_BRS" BO_ 1053 1;
BA_ "GenMsgCycleTime" BO_ 1053 100;
BA_ "GenMsgILSupport" BO_ 1053 1;
BA_ "GenMsgSendType" BO_ 1053 0;
BA_ "Type" BO_ 1053 1;
BA_ "CANFD_BRS" BO_ 520 1;
BA_ "GenMsgCycleTime" BO_ 520 20;
BA_ "GenMsgILSupport" BO_ 520 1;
BA_ "GenMsgSendType" BO_ 520 0;
BA_ "Type" BO_ 520 1;
BA_ "CANFD_BRS" BO_ 156 1;
BA_ "GenMsgILSupport" BO_ 156 1;
BA_ "Type" BO_ 156 8;
BA_ "CANFD_BRS" BO_ 1058 1;
BA_ "GenMsgCycleTime" BO_ 1058 100;
BA_ "GenMsgILSupport" BO_ 1058 1;
BA_ "GenMsgSendType" BO_ 1058 0;
BA_ "Type" BO_ 1058 1;
BA_ "CANFD_BRS" BO_ 1829 1;
BA_ "GenMsgCycleTime" BO_ 1829 1000;
BA_ "GenMsgILSupport" BO_ 1829 1;
BA_ "GenMsgSendType" BO_ 1829 0;
BA_ "Type" BO_ 1829 1;
BA_ "CANFD_BRS" BO_ 1626 1;
BA_ "GenMsgCycleTime" BO_ 1626 500;
BA_ "GenMsgCycleTimeFast" BO_ 1626 10;
BA_ "GenMsgILSupport" BO_ 1626 1;
BA_ "GenMsgSendType" BO_ 1626 0;
BA_ "Type" BO_ 1626 10;
BA_ "CANFD_BRS" BO_ 2564554482 1;
BA_ "DiagConnection" BO_ 2564554482 62206;
BA_ "DiagState" BO_ 2564554482 1;
BA_ "Type" BO_ 2564554482 8;
BA_ "VFrameFormat" BO_ 2564554482 15;
BA_ "CANFD_BRS" BO_ 609 1;
BA_ "GenMsgCycleTime" BO_ 609 100;
BA_ "GenMsgCycleTimeFast" BO_ 609 20;
BA_ "GenMsgILSupport" BO_ 609 1;
BA_ "GenMsgNrOfRepetition" BO_ 609 2;
BA_ "GenMsgSendType" BO_ 609 0;
BA_ "Type" BO_ 609 3;
BA_ "CANFD_BRS" BO_ 1066 1;
BA_ "GenMsgDelayTime" BO_ 1066 20;
BA_ "GenMsgCycleTime" BO_ 1066 250;
BA_ "GenMsgCycleTimeFast" BO_ 1066 20;
BA_ "GenMsgILSupport" BO_ 1066 1;
BA_ "GenMsgNrOfRepetition" BO_ 1066 2;
BA_ "GenMsgSendType" BO_ 1066 0;
BA_ "Type" BO_ 1066 3;
BA_ "CANFD_BRS" BO_ 1827 1;
BA_ "GenMsgCycleTime" BO_ 1827 1000;
BA_ "GenMsgILSupport" BO_ 1827 1;
BA_ "GenMsgSendType" BO_ 1827 0;
BA_ "Type" BO_ 1827 1;
BA_ "CANFD_BRS" BO_ 256 1;
BA_ "GenMsgCycleTime" BO_ 256 10;
BA_ "GenMsgILSupport" BO_ 256 1;
BA_ "GenMsgSendType" BO_ 256 0;
BA_ "Type" BO_ 256 1;
BA_ "CANFD_BRS" BO_ 1153 1;
BA_ "GenMsgDelayTime" BO_ 1153 20;
BA_ "GenMsgCycleTime" BO_ 1153 500;
BA_ "GenMsgCycleTimeFast" BO_ 1153 20;
BA_ "GenMsgILSupport" BO_ 1153 1;
BA_ "GenMsgNrOfRepetition" BO_ 1153 2;
BA_ "GenMsgSendType" BO_ 1153 0;
BA_ "Type" BO_ 1153 3;
BA_ "CANFD_BRS" BO_ 1373 1;
BA_ "GenMsgCycleTime" BO_ 1373 250;
BA_ "GenMsgILSupport" BO_ 1373 1;
BA_ "GenMsgSendType" BO_ 1373 0;
BA_ "Type" BO_ 1373 1;
BA_ "CANFD_BRS" BO_ 1030 1;
BA_ "GenMsgCycleTime" BO_ 1030 100;
BA_ "GenMsgILSupport" BO_ 1030 1;
BA_ "GenMsgSendType" BO_ 1030 0;
BA_ "Type" BO_ 1030 1;
BA_ "CANFD_BRS" BO_ 753 1;
BA_ "GenMsgCycleTime" BO_ 753 50;
BA_ "GenMsgILSupport" BO_ 753 1;
BA_ "GenMsgSendType" BO_ 753 0;
BA_ "Type" BO_ 753 1;
BA_ "CANFD_BRS" BO_ 752 1;
BA_ "GenMsgCycleTime" BO_ 752 50;
BA_ "GenMsgILSupport" BO_ 752 1;
BA_ "GenMsgSendType" BO_ 752 0;
BA_ "Type" BO_ 752 1;
BA_ "CANFD_BRS" BO_ 267 1;
BA_ "GenMsgCycleTime" BO_ 267 10;
BA_ "GenMsgILSupport" BO_ 267 1;
BA_ "GenMsgSendType" BO_ 267 0;
BA_ "Type" BO_ 267 1;
BA_ "CANFD_BRS" BO_ 1956 1;
BA_ "GenMsgCycleTime" BO_ 1956 1000;
BA_ "GenMsgILSupport" BO_ 1956 1;
BA_ "GenMsgSendType" BO_ 1956 0;
BA_ "Type" BO_ 1956 1;
BA_ "CANFD_BRS" BO_ 1033 1;
BA_ "GenMsgCycleTime" BO_ 1033 100;
BA_ "GenMsgILSupport" BO_ 1033 1;
BA_ "GenMsgSendType" BO_ 1033 0;
BA_ "Type" BO_ 1033 1;
BA_ "CANFD_BRS" BO_ 1834 1;
BA_ "GenMsgCycleTime" BO_ 1834 1000;
BA_ "GenMsgILSupport" BO_ 1834 1;
BA_ "GenMsgSendType" BO_ 1834 0;
BA_ "Type" BO_ 1834 1;
BA_ "CANFD_BRS" BO_ 1029 1;
BA_ "GenMsgCycleTime" BO_ 1029 100;
BA_ "GenMsgILSupport" BO_ 1029 1;
BA_ "GenMsgSendType" BO_ 1029 0;
BA_ "Type" BO_ 1029 1;
BA_ "CANFD_BRS" BO_ 1027 1;
BA_ "GenMsgCycleTime" BO_ 1027 100;
BA_ "GenMsgILSupport" BO_ 1027 1;
BA_ "GenMsgSendType" BO_ 1027 0;
BA_ "Type" BO_ 1027 1;
BA_ "CANFD_BRS" BO_ 266 1;
BA_ "GenMsgCycleTime" BO_ 266 10;
BA_ "GenMsgILSupport" BO_ 266 1;
BA_ "GenMsgSendType" BO_ 266 0;
BA_ "Type" BO_ 266 1;
BA_ "CANFD_BRS" BO_ 1034 1;
BA_ "GenMsgCycleTime" BO_ 1034 100;
BA_ "GenMsgILSupport" BO_ 1034 1;
BA_ "GenMsgSendType" BO_ 1034 0;
BA_ "Type" BO_ 1034 1;
BA_ "CANFD_BRS" BO_ 1839 1;
BA_ "GenMsgCycleTime" BO_ 1839 1000;
BA_ "GenMsgILSupport" BO_ 1839 1;
BA_ "GenMsgSendType" BO_ 1839 0;
BA_ "Type" BO_ 1839 1;
BA_ "CANFD_BRS" BO_ 1840 1;
BA_ "GenMsgCycleTime" BO_ 1840 1000;
BA_ "GenMsgILSupport" BO_ 1840 1;
BA_ "GenMsgSendType" BO_ 1840 0;
BA_ "Type" BO_ 1840 1;
BA_ "CANFD_BRS" BO_ 1838 1;
BA_ "GenMsgCycleTime" BO_ 1838 1000;
BA_ "GenMsgILSupport" BO_ 1838 1;
BA_ "GenMsgSendType" BO_ 1838 0;
BA_ "Type" BO_ 1838 1;
BA_ "CANFD_BRS" BO_ 1837 1;
BA_ "GenMsgCycleTime" BO_ 1837 1000;
BA_ "GenMsgILSupport" BO_ 1837 1;
BA_ "GenMsgSendType" BO_ 1837 0;
BA_ "Type" BO_ 1837 1;
BA_ "GenMsgCycleTime" BO_ 1836 1000;
BA_ "GenMsgILSupport" BO_ 1836 1;
BA_ "GenMsgSendType" BO_ 1836 0;
BA_ "Type" BO_ 1836 1;
BA_ "CANFD_BRS" BO_ 1836 1;
BA_ "CANFD_BRS" BO_ 1835 1;
BA_ "GenMsgCycleTime" BO_ 1835 1000;
BA_ "GenMsgILSupport" BO_ 1835 1;
BA_ "GenMsgSendType" BO_ 1835 0;
BA_ "Type" BO_ 1835 1;
BA_ "CANFD_BRS" BO_ 1035 1;
BA_ "GenMsgCycleTime" BO_ 1035 100;
BA_ "GenMsgILSupport" BO_ 1035 1;
BA_ "GenMsgSendType" BO_ 1035 0;
BA_ "Type" BO_ 1035 1;
BA_ "GenMsgCycleTime" BO_ 750 50;
BA_ "GenMsgILSupport" BO_ 750 1;
BA_ "GenMsgSendType" BO_ 750 0;
BA_ "Type" BO_ 750 1;
BA_ "CANFD_BRS" BO_ 750 1;
BA_ "CANFD_BRS" BO_ 1436 1;
BA_ "GenMsgDelayTime" BO_ 1436 20;
BA_ "GenMsgCycleTime" BO_ 1436 1000;
BA_ "GenMsgCycleTimeFast" BO_ 1436 20;
BA_ "GenMsgILSupport" BO_ 1436 1;
BA_ "GenMsgNrOfRepetition" BO_ 1436 2;
BA_ "GenMsgSendType" BO_ 1436 0;
BA_ "Type" BO_ 1436 3;
BA_ "NmAsrMessage" BO_ 2654486640 1;
BA_ "NmMessage" BO_ 2654486640 1;
BA_ "Type" BO_ 2654486640 8;
BA_ "CANFD_BRS" BO_ 2654486640 1;
BA_ "VFrameFormat" BO_ 2654486640 15;
BA_ "CANFD_BRS" BO_ 2654486626 1;
BA_ "NmAsrMessage" BO_ 2654486626 1;
BA_ "NmMessage" BO_ 2654486626 1;
BA_ "Type" BO_ 2654486626 8;
BA_ "VFrameFormat" BO_ 2654486626 15;
BA_ "CANFD_BRS" BO_ 276 1;
BA_ "GenMsgCycleTime" BO_ 276 10;
BA_ "GenMsgILSupport" BO_ 276 1;
BA_ "GenMsgSendType" BO_ 276 0;
BA_ "Type" BO_ 276 1;
BA_ "CANFD_BRS" BO_ 262 1;
BA_ "GenMsgCycleTime" BO_ 262 10;
BA_ "GenMsgILSupport" BO_ 262 1;
BA_ "GenMsgSendType" BO_ 262 0;
BA_ "Type" BO_ 262 1;
BA_ "CANFD_BRS" BO_ 258 1;
BA_ "GenMsgCycleTime" BO_ 258 10;
BA_ "GenMsgILSupport" BO_ 258 1;
BA_ "GenMsgSendType" BO_ 258 0;
BA_ "Type" BO_ 258 1;
BA_ "CANFD_BRS" BO_ 2654486653 1;
BA_ "NmAsrMessage" BO_ 2654486653 1;
BA_ "NmMessage" BO_ 2654486653 1;
BA_ "Type" BO_ 2654486653 8;
BA_ "VFrameFormat" BO_ 2654486653 15;
BA_ "CANFD_BRS" BO_ 2654486598 1;
BA_ "NmAsrMessage" BO_ 2654486598 1;
BA_ "NmMessage" BO_ 2654486598 1;
BA_ "Type" BO_ 2654486598 8;
BA_ "VFrameFormat" BO_ 2654486598 15;
BA_ "GenSigTimeoutTime_SGW" SG_ 2651930624 Digit_11 0;
BA_ "GenSigTimeoutTime_EVCU2" SG_ 2651930624 Digit_11 0;
BA_ "GenSigTimeoutTime_HCP" SG_ 2651930624 Digit_11 0;
BA_ "GenSigTimeoutTime_SGW" SG_ 2651930624 Digit_10 0;
BA_ "GenSigTimeoutTime_EVCU2" SG_ 2651930624 Digit_10 0;
BA_ "GenSigTimeoutTime_HCP" SG_ 2651930624 Digit_10 0;
BA_ "GenSigTimeoutTime_SGW" SG_ 2651930624 Digit_09 0;
BA_ "GenSigTimeoutTime_EVCU2" SG_ 2651930624 Digit_09 0;
BA_ "GenSigTimeoutTime_HCP" SG_ 2651930624 Digit_09 0;
BA_ "GenSigTimeoutTime_SGW" SG_ 2651930624 Digit_08 0;
BA_ "GenSigTimeoutTime_EVCU2" SG_ 2651930624 Digit_08 0;
BA_ "GenSigTimeoutTime_HCP" SG_ 2651930624 Digit_08 0;
BA_ "GenSigTimeoutTime_SGW" SG_ 2651930624 Digit_07 0;
BA_ "GenSigTimeoutTime_EVCU2" SG_ 2651930624 Digit_07 0;
BA_ "GenSigTimeoutTime_HCP" SG_ 2651930624 Digit_07 0;
BA_ "GenSigTimeoutTime_SGW" SG_ 2651930624 Digit_06 0;
BA_ "GenSigTimeoutTime_EVCU2" SG_ 2651930624 Digit_06 0;
BA_ "GenSigTimeoutTime_HCP" SG_ 2651930624 Digit_06 0;
BA_ "GenSigTimeoutTime_SGW" SG_ 2651930624 Digit_05 0;
BA_ "GenSigTimeoutTime_EVCU2" SG_ 2651930624 Digit_05 0;
BA_ "GenSigTimeoutTime_HCP" SG_ 2651930624 Digit_05 0;
BA_ "GenSigTimeoutTime_SGW" SG_ 2651930624 Digit_04 0;
BA_ "GenSigTimeoutTime_EVCU2" SG_ 2651930624 Digit_04 0;
BA_ "GenSigTimeoutTime_HCP" SG_ 2651930624 Digit_04 0;
BA_ "GenSigTimeoutTime_SGW" SG_ 2651930624 Digit_03 0;
BA_ "GenSigTimeoutTime_EVCU2" SG_ 2651930624 Digit_03 0;
BA_ "GenSigTimeoutTime_HCP" SG_ 2651930624 Digit_03 0;
BA_ "GenSigTimeoutTime_SGW" SG_ 2651930624 Digit_02 0;
BA_ "GenSigTimeoutTime_EVCU2" SG_ 2651930624 Digit_02 0;
BA_ "GenSigTimeoutTime_HCP" SG_ 2651930624 Digit_02 0;
BA_ "GenSigTimeoutTime_SGW" SG_ 2651930624 Digit_01 0;
BA_ "GenSigTimeoutTime_EVCU2" SG_ 2651930624 Digit_01 0;
BA_ "GenSigTimeoutTime_HCP" SG_ 2651930624 Digit_01 0;
BA_ "GenSigTimeoutTime_SGW" SG_ 2564554481 N_PDU_18DBFEF1 0;
BA_ "GenSigTimeoutTime_IDCM" SG_ 2564554481 N_PDU_18DBFEF1 0;
BA_ "GenSigTimeoutTime_EVCU2" SG_ 2564554481 N_PDU_18DBFEF1 0;
BA_ "GenSigTimeoutTime_BPCM" SG_ 2564554481 N_PDU_18DBFEF1 0;
BA_ "GenSigTimeoutTime_PPIM" SG_ 2564554481 N_PDU_18DBFEF1 0;
BA_ "GenSigTimeoutTime_HCP" SG_ 2564554481 N_PDU_18DBFEF1 0;
BA_ "GenSigTimeoutTime_SGW" SG_ 2564502513 N_PDU_18DB33F1 0;
BA_ "GenSigTimeoutTime_IDCM" SG_ 2564502513 N_PDU_18DB33F1 0;
BA_ "GenSigTimeoutTime_EVCU2" SG_ 2564502513 N_PDU_18DB33F1 0;
BA_ "GenSigTimeoutTime_BPCM" SG_ 2564502513 N_PDU_18DB33F1 0;
BA_ "GenSigTimeoutTime_PPIM" SG_ 2564502513 N_PDU_18DB33F1 0;
BA_ "GenSigTimeoutTime_HCP" SG_ 2564502513 N_PDU_18DB33F1 0;
BA_ "GenSigTimeoutTime_SGW" SG_ 2564485444 N_PDU_18DAF144 0;
BA_ "GenSigTimeoutTime_IDCM" SG_ 2564485444 N_PDU_18DAF144 0;
BA_ "GenSigTimeoutTime_EVCU2" SG_ 2564485444 N_PDU_18DAF144 0;
BA_ "GenSigTimeoutTime_BPCM" SG_ 2564485444 N_PDU_18DAF144 0;
BA_ "GenSigTimeoutTime_PPIM" SG_ 2564485444 N_PDU_18DAF144 0;
BA_ "GenSigTimeoutTime_HCP" SG_ 2564485444 N_PDU_18DAF144 0;
BA_ "GenSigTimeoutTime_SGW" SG_ 2564441329 N_PDU_18DA44F1 0;
BA_ "GenSigTimeoutTime_IDCM" SG_ 2564441329 N_PDU_18DA44F1 0;
BA_ "GenSigTimeoutTime_EVCU2" SG_ 2564441329 N_PDU_18DA44F1 0;
BA_ "GenSigTimeoutTime_BPCM" SG_ 2564441329 N_PDU_18DA44F1 0;
BA_ "GenSigTimeoutTime_PPIM" SG_ 2564441329 N_PDU_18DA44F1 0;
BA_ "GenSigTimeoutTime_HCP" SG_ 2564441329 N_PDU_18DA44F1 0;
BA_ "GenSigTimeoutTime_SGW" SG_ 2564485451 N_PDU_18DAF14B 0;
BA_ "GenSigTimeoutTime_IDCM" SG_ 2564485451 N_PDU_18DAF14B 0;
BA_ "GenSigTimeoutTime_EVCU2" SG_ 2564485451 N_PDU_18DAF14B 0;
BA_ "GenSigTimeoutTime_BPCM" SG_ 2564485451 N_PDU_18DAF14B 0;
BA_ "GenSigTimeoutTime_PPIM" SG_ 2564485451 N_PDU_18DAF14B 0;
BA_ "GenSigTimeoutTime_HCP" SG_ 2564485451 N_PDU_18DAF14B 0;
BA_ "GenSigTimeoutTime_SGW" SG_ 2564443121 N_PDU_18DA4BF1 0;
BA_ "GenSigTimeoutTime_IDCM" SG_ 2564443121 N_PDU_18DA4BF1 0;
BA_ "GenSigTimeoutTime_EVCU2" SG_ 2564443121 N_PDU_18DA4BF1 0;
BA_ "GenSigTimeoutTime_BPCM" SG_ 2564443121 N_PDU_18DA4BF1 0;
BA_ "GenSigTimeoutTime_PPIM" SG_ 2564443121 N_PDU_18DA4BF1 0;
BA_ "GenSigTimeoutTime_HCP" SG_ 2564443121 N_PDU_18DA4BF1 0;
BA_ "GenSigTimeoutTime_SGW" SG_ 2564485456 N_PDU_18DAF150 0;
BA_ "GenSigTimeoutTime_IDCM" SG_ 2564485456 N_PDU_18DAF150 0;
BA_ "GenSigTimeoutTime_EVCU2" SG_ 2564485456 N_PDU_18DAF150 0;
BA_ "GenSigTimeoutTime_BPCM" SG_ 2564485456 N_PDU_18DAF150 0;
BA_ "GenSigTimeoutTime_PPIM" SG_ 2564485456 N_PDU_18DAF150 0;
BA_ "GenSigTimeoutTime_HCP" SG_ 2564485456 N_PDU_18DAF150 0;
BA_ "GenSigTimeoutTime_SGW" SG_ 2564444401 N_PDU_18DA50F1 0;
BA_ "GenSigTimeoutTime_IDCM" SG_ 2564444401 N_PDU_18DA50F1 0;
BA_ "GenSigTimeoutTime_EVCU2" SG_ 2564444401 N_PDU_18DA50F1 0;
BA_ "GenSigTimeoutTime_BPCM" SG_ 2564444401 N_PDU_18DA50F1 0;
BA_ "GenSigTimeoutTime_PPIM" SG_ 2564444401 N_PDU_18DA50F1 0;
BA_ "GenSigTimeoutTime_HCP" SG_ 2564444401 N_PDU_18DA50F1 0;
BA_ "GenSigTimeoutTime_SGW" SG_ 1053 VIN_MSG 0;
BA_ "GenSigTimeoutTime_EVCU2" SG_ 1053 VIN_MSG 0;
BA_ "GenSigStartValue" SG_ 1053 VIN_MSG 3;
BA_ "GenSigTimeoutTime_HCP" SG_ 1053 VIN_MSG 0;
BA_ "GenSigTimeoutTime_SGW" SG_ 1053 VIN_DATA 0;
BA_ "GenSigTimeoutTime_EVCU2" SG_ 1053 VIN_DATA 0;
BA_ "GenSigTimeoutTime_HCP" SG_ 1053 VIN_DATA 0;
BA_ "GenSigTimeoutTime_SGW" SG_ 520 GearEngagedForDisplay 0;
BA_ "GenSigTimeoutTime_EVCU2" SG_ 520 GearEngagedForDisplay 0;
BA_ "GenSigStartValue" SG_ 520 GearEngagedForDisplay 31;
BA_ "GenSigTimeoutTime_PPIM" SG_ 520 GearEngagedForDisplay 0;
BA_ "GenSigTimeoutTime_HCP" SG_ 520 GearEngagedForDisplay 0;
BA_ "GenSigTimeoutTime_SGW" SG_ 156 GPS_UTC_Second 0;
BA_ "GenSigTimeoutTime_EVCU2" SG_ 156 GPS_UTC_Second 0;
BA_ "GenSigStartValue" SG_ 156 GPS_UTC_Second 65535;
BA_ "GenSigTimeoutTime_PPIM" SG_ 156 GPS_UTC_Second 0;
BA_ "GenSigTimeoutTime_HCP" SG_ 156 GPS_UTC_Second 0;
BA_ "GenSigTimeoutTime_SGW" SG_ 156 GPS_UTC_Minute 0;
BA_ "GenSigTimeoutTime_EVCU2" SG_ 156 GPS_UTC_Minute 0;
BA_ "GenSigStartValue" SG_ 156 GPS_UTC_Minute 255;
BA_ "GenSigTimeoutTime_PPIM" SG_ 156 GPS_UTC_Minute 0;
BA_ "GenSigTimeoutTime_HCP" SG_ 156 GPS_UTC_Minute 0;
BA_ "GenSigTimeoutTime_SGW" SG_ 156 GPS_UTC_Hour 0;
BA_ "GenSigTimeoutTime_EVCU2" SG_ 156 GPS_UTC_Hour 0;
BA_ "GenSigStartValue" SG_ 156 GPS_UTC_Hour 255;
BA_ "GenSigTimeoutTime_PPIM" SG_ 156 GPS_UTC_Hour 0;
BA_ "GenSigTimeoutTime_HCP" SG_ 156 GPS_UTC_Hour 0;
BA_ "GenSigTimeoutTime_SGW" SG_ 156 GPS_Date_Year 0;
BA_ "GenSigTimeoutTime_EVCU2" SG_ 156 GPS_Date_Year 0;
BA_ "GenSigStartValue" SG_ 156 GPS_Date_Year 65535;
BA_ "GenSigTimeoutTime_PPIM" SG_ 156 GPS_Date_Year 0;
BA_ "GenSigTimeoutTime_HCP" SG_ 156 GPS_Date_Year 0;
BA_ "GenSigTimeoutTime_SGW" SG_ 156 GPS_Date_Month 0;
BA_ "GenSigTimeoutTime_EVCU2" SG_ 156 GPS_Date_Month 0;
BA_ "GenSigStartValue" SG_ 156 GPS_Date_Month 255;
BA_ "GenSigTimeoutTime_PPIM" SG_ 156 GPS_Date_Month 0;
BA_ "GenSigTimeoutTime_HCP" SG_ 156 GPS_Date_Month 0;
BA_ "GenSigTimeoutTime_SGW" SG_ 156 GPS_Date_Day 0;
BA_ "GenSigTimeoutTime_EVCU2" SG_ 156 GPS_Date_Day 0;
BA_ "GenSigStartValue" SG_ 156 GPS_Date_Day 255;
BA_ "GenSigTimeoutTime_PPIM" SG_ 156 GPS_Date_Day 0;
BA_ "GenSigTimeoutTime_HCP" SG_ 156 GPS_Date_Day 0;
BA_ "GenSigTimeoutTime_SGW" SG_ 1058 CARB_PERM 0;
BA_ "GenSigTimeoutTime_IDCM" SG_ 1058 CARB_PERM 0;
BA_ "GenSigTimeoutTime_EVCU2" SG_ 1058 CARB_PERM 0;
BA_ "GenSigTimeoutTime_PPIM" SG_ 1058 CARB_PERM 0;
BA_ "GenSigTimeoutTime_HCP" SG_ 1058 CARB_PERM 0;
BA_ "GenSigTimeoutTime_SGW" SG_ 1058 OAT_PT_EstV 0;
BA_ "GenSigTimeoutTime_IDCM" SG_ 1058 OAT_PT_EstV 0;
BA_ "GenSigTimeoutTime_EVCU2" SG_ 1058 OAT_PT_EstV 0;
BA_ "GenSigTimeoutTime_PPIM" SG_ 1058 OAT_PT_EstV 0;
BA_ "GenSigTimeoutTime_HCP" SG_ 1058 OAT_PT_EstV 0;
BA_ "GenSigTimeoutTime_SGW" SG_ 1058 OAT_PT_Est 0;
BA_ "GenSigTimeoutTime_IDCM" SG_ 1058 OAT_PT_Est 0;
BA_ "GenSigTimeoutTime_EVCU2" SG_ 1058 OAT_PT_Est 0;
BA_ "GenSigTimeoutTime_PPIM" SG_ 1058 OAT_PT_Est 0;
BA_ "GenSigTimeoutTime_HCP" SG_ 1058 OAT_PT_Est 0;
BA_ "GenSigTimeoutTime_SGW" SG_ 1829 TotalOdometer 0;
BA_ "GenSigTimeoutTime_EVCU2" SG_ 1829 TotalOdometer 0;
BA_ "GenSigTimeoutTime_HCP" SG_ 1829 TotalOdometer 0;
BA_ "GenSigTimeoutTime_SGW" SG_ 1626 IMPACTConfirm 0;
BA_ "GenSigTimeoutTime_EVCU2" SG_ 1626 IMPACTConfirm 0;
BA_ "GenSigSendType" SG_ 1626 IMPACTConfirm 5;
BA_ "GenSigInactiveValue" SG_ 1626 IMPACTConfirm 1;
BA_ "GenSigStartValue" SG_ 1626 IMPACTConfirm 1;
BA_ "GenSigTimeoutTime_PPIM" SG_ 1626 IMPACTConfirm 0;
BA_ "GenSigTimeoutTime_HCP" SG_ 1626 IMPACTConfirm 0;
BA_ "GenSigTimeoutTime_SGW" SG_ 1626 IMPACTCommand 0;
BA_ "GenSigTimeoutTime_EVCU2" SG_ 1626 IMPACTCommand 0;
BA_ "GenSigSendType" SG_ 1626 IMPACTCommand 5;
BA_ "GenSigTimeoutTime_PPIM" SG_ 1626 IMPACTCommand 0;
BA_ "GenSigTimeoutTime_HCP" SG_ 1626 IMPACTCommand 0;
BA_ "GenSigTimeoutTime_SGW" SG_ 2564554482 N_PDU_18DBFEF2 0;
BA_ "GenSigTimeoutTime_IDCM" SG_ 2564554482 N_PDU_18DBFEF2 0;
BA_ "GenSigTimeoutTime_EVCU2" SG_ 2564554482 N_PDU_18DBFEF2 0;
BA_ "GenSigTimeoutTime_BPCM" SG_ 2564554482 N_PDU_18DBFEF2 0;
BA_ "GenSigTimeoutTime_PPIM" SG_ 2564554482 N_PDU_18DBFEF2 0;
BA_ "GenSigTimeoutTime_HCP" SG_ 2564554482 N_PDU_18DBFEF2 0;
BA_ "GenSigTimeoutTime_SGW" SG_ 609 EPBSts 0;
BA_ "GenSigTimeoutTime_EVCU2" SG_ 609 EPBSts 0;
BA_ "GenSigSendType" SG_ 609 EPBSts 3;
BA_ "GenSigTimeoutTime_PPIM" SG_ 609 EPBSts 0;
BA_ "GenSigTimeoutTime_HCP" SG_ 609 EPBSts 0;
BA_ "GenSigTimeoutTime_SGW" SG_ 1066 ExternalTemperature 0;
BA_ "GenSigTimeoutTime_EVCU2" SG_ 1066 ExternalTemperature 0;
BA_ "GenSigTimeoutTime_PPIM" SG_ 1066 ExternalTemperature 0;
BA_ "GenSigTimeoutTime_HCP" SG_ 1066 ExternalTemperature 0;
BA_ "GenSigTimeoutTime_SGW" SG_ 1827 IgnitionOnCounter 0;
BA_ "GenSigTimeoutTime_EVCU2" SG_ 1827 IgnitionOnCounter 0;
BA_ "GenSigTimeoutTime_HCP" SG_ 1827 IgnitionOnCounter 0;
BA_ "GenSigTimeoutTime_SGW" SG_ 256 OperationalModeSts 0;
BA_ "GenSigTimeoutTime_EVCU2" SG_ 256 OperationalModeSts 0;
BA_ "GenSigTimeoutTime_SGW" SG_ 1153 ExternalTemperatureC 0;
BA_ "GenSigTimeoutTime_EVCU2" SG_ 1153 ExternalTemperatureC 0;
BA_ "GenSigStartValue" SG_ 1153 ExternalTemperatureC 511;
BA_ "GenSigTimeoutTime_HCP" SG_ 1153 ExternalTemperatureC 0;
BA_ "GenSigTimeoutTime_SGW" SG_ 1153 CmdIgnSts 0;
BA_ "GenSigTimeoutTime_EVCU2" SG_ 1153 CmdIgnSts 0;
BA_ "GenSigSendType" SG_ 1153 CmdIgnSts 3;
BA_ "GenSigTimeoutTime_HCP" SG_ 1153 CmdIgnSts 0;
BA_ "GenSigTimeoutTime_IDCM" SG_ 1373 DCDC_OutputPower 0;
BA_ "GenSigTimeoutTime_EVCU2" SG_ 1373 DCDC_OutputPower 0;
BA_ "GenSigTimeoutTime_BPCM" SG_ 1373 DCDC_OutputPower 0;
BA_ "GenSigTimeoutTime_PPIM" SG_ 1373 DCDC_OutputPower 0;
BA_ "GenSigTimeoutTime_SGW" SG_ 1373 LVDC_LowVoltageSts 0;
BA_ "GenSigTimeoutTime_IDCM" SG_ 1373 LVDC_LowVoltageSts 0;
BA_ "GenSigTimeoutTime_EVCU2" SG_ 1373 LVDC_LowVoltageSts 0;
BA_ "GenSigTimeoutTime_BPCM" SG_ 1373 LVDC_LowVoltageSts 0;
BA_ "GenSigTimeoutTime_PPIM" SG_ 1373 LVDC_LowVoltageSts 0;
BA_ "GenSigTimeoutTime_SGW" SG_ 1373 LVDC_HighVoltageSts 0;
BA_ "GenSigTimeoutTime_IDCM" SG_ 1373 LVDC_HighVoltageSts 0;
BA_ "GenSigTimeoutTime_EVCU2" SG_ 1373 LVDC_HighVoltageSts 0;
BA_ "GenSigTimeoutTime_BPCM" SG_ 1373 LVDC_HighVoltageSts 0;
BA_ "GenSigTimeoutTime_PPIM" SG_ 1373 LVDC_HighVoltageSts 0;
BA_ "GenSigTimeoutTime_SGW" SG_ 1373 LVDC_HighCurrentSts 0;
BA_ "GenSigTimeoutTime_IDCM" SG_ 1373 LVDC_HighCurrentSts 0;
BA_ "GenSigTimeoutTime_EVCU2" SG_ 1373 LVDC_HighCurrentSts 0;
BA_ "GenSigTimeoutTime_BPCM" SG_ 1373 LVDC_HighCurrentSts 0;
BA_ "GenSigTimeoutTime_PPIM" SG_ 1373 LVDC_HighCurrentSts 0;
BA_ "GenSigTimeoutTime_SGW" SG_ 1373 HVDC_OvervoltageSts 0;
BA_ "GenSigTimeoutTime_IDCM" SG_ 1373 HVDC_OvervoltageSts 0;
BA_ "GenSigTimeoutTime_EVCU2" SG_ 1373 HVDC_OvervoltageSts 0;
BA_ "GenSigTimeoutTime_BPCM" SG_ 1373 HVDC_OvervoltageSts 0;
BA_ "GenSigTimeoutTime_PPIM" SG_ 1373 HVDC_OvervoltageSts 0;
BA_ "GenSigTimeoutTime_SGW" SG_ 1373 DCDC_Utilization 0;
BA_ "GenSigTimeoutTime_IDCM" SG_ 1373 DCDC_Utilization 0;
BA_ "GenSigTimeoutTime_EVCU2" SG_ 1373 DCDC_Utilization 0;
BA_ "GenSigTimeoutTime_BPCM" SG_ 1373 DCDC_Utilization 0;
BA_ "GenSigTimeoutTime_PPIM" SG_ 1373 DCDC_Utilization 0;
BA_ "GenSigTimeoutTime_SGW" SG_ 1373 DCDC_TotalOperatingTime 0;
BA_ "GenSigTimeoutTime_IDCM" SG_ 1373 DCDC_TotalOperatingTime 0;
BA_ "GenSigTimeoutTime_EVCU2" SG_ 1373 DCDC_TotalOperatingTime 0;
BA_ "GenSigTimeoutTime_BPCM" SG_ 1373 DCDC_TotalOperatingTime 0;
BA_ "GenSigTimeoutTime_PPIM" SG_ 1373 DCDC_TotalOperatingTime 0;
BA_ "GenSigTimeoutTime_SGW" SG_ 1373 DCDC_InputPower 0;
BA_ "GenSigTimeoutTime_IDCM" SG_ 1373 DCDC_InputPower 0;
BA_ "GenSigTimeoutTime_EVCU2" SG_ 1373 DCDC_InputPower 0;
BA_ "GenSigTimeoutTime_BPCM" SG_ 1373 DCDC_InputPower 0;
BA_ "GenSigTimeoutTime_PPIM" SG_ 1373 DCDC_InputPower 0;
BA_ "GenSigTimeoutTime_SGW" SG_ 1373 DCDC_DeratingReason 0;
BA_ "GenSigTimeoutTime_IDCM" SG_ 1373 DCDC_DeratingReason 0;
BA_ "GenSigTimeoutTime_EVCU2" SG_ 1373 DCDC_DeratingReason 0;
BA_ "GenSigTimeoutTime_BPCM" SG_ 1373 DCDC_DeratingReason 0;
BA_ "GenSigTimeoutTime_PPIM" SG_ 1373 DCDC_DeratingReason 0;
BA_ "GenSigStartValue" SG_ 1373 DCDC_DeratingPower 61;
BA_ "GenSigTimeoutTime_PPIM" SG_ 1373 DCDC_DeratingPower 0;
BA_ "GenSigTimeoutTime_SGW" SG_ 1373 DCDC_DeratingPower 0;
BA_ "GenSigTimeoutTime_IDCM" SG_ 1373 DCDC_DeratingPower 0;
BA_ "GenSigTimeoutTime_EVCU2" SG_ 1373 DCDC_DeratingPower 0;
BA_ "GenSigTimeoutTime_BPCM" SG_ 1373 DCDC_DeratingPower 0;
BA_ "GenSigTimeoutTime_SGW" SG_ 1373 DCDC_DeratingModeSts 0;
BA_ "GenSigTimeoutTime_IDCM" SG_ 1373 DCDC_DeratingModeSts 0;
BA_ "GenSigTimeoutTime_EVCU2" SG_ 1373 DCDC_DeratingModeSts 0;
BA_ "GenSigTimeoutTime_BPCM" SG_ 1373 DCDC_DeratingModeSts 0;
BA_ "GenSigTimeoutTime_PPIM" SG_ 1373 DCDC_DeratingModeSts 0;
BA_ "GenSigTimeoutTime_SGW" SG_ 1373 DCDC_CurrentCycleTime 0;
BA_ "GenSigTimeoutTime_IDCM" SG_ 1373 DCDC_CurrentCycleTime 0;
BA_ "GenSigTimeoutTime_EVCU2" SG_ 1373 DCDC_CurrentCycleTime 0;
BA_ "GenSigTimeoutTime_BPCM" SG_ 1373 DCDC_CurrentCycleTime 0;
BA_ "GenSigTimeoutTime_PPIM" SG_ 1373 DCDC_CurrentCycleTime 0;
BA_ "GenSigTimeoutTime_SGW" SG_ 1373 DCDC_BatteryFeedVoltage 0;
BA_ "GenSigTimeoutTime_IDCM" SG_ 1373 DCDC_BatteryFeedVoltage 0;
BA_ "GenSigTimeoutTime_EVCU2" SG_ 1373 DCDC_BatteryFeedVoltage 0;
BA_ "GenSigTimeoutTime_BPCM" SG_ 1373 DCDC_BatteryFeedVoltage 0;
BA_ "GenSigTimeoutTime_PPIM" SG_ 1373 DCDC_BatteryFeedVoltage 0;
BA_ "GenSigTimeoutTime_IDCM" SG_ 1030 DCDC_FailureReason 0;
BA_ "GenSigTimeoutTime_EVCU2" SG_ 1030 DCDC_FailureReason 0;
BA_ "GenSigTimeoutTime_BPCM" SG_ 1030 DCDC_FailureReason 0;
BA_ "GenSigTimeoutTime_PPIM" SG_ 1030 DCDC_FailureReason 0;
BA_ "GenSigTimeoutTime_SGW" SG_ 1030 LVDC_VoltageSetpointFdbk 0;
BA_ "GenSigTimeoutTime_IDCM" SG_ 1030 LVDC_VoltageSetpointFdbk 0;
BA_ "GenSigTimeoutTime_EVCU2" SG_ 1030 LVDC_VoltageSetpointFdbk 0;
BA_ "GenSigTimeoutTime_BPCM" SG_ 1030 LVDC_VoltageSetpointFdbk 0;
BA_ "GenSigStartValue" SG_ 1030 LVDC_VoltageSetpointFdbk 217;
BA_ "GenSigTimeoutTime_PPIM" SG_ 1030 LVDC_VoltageSetpointFdbk 0;
BA_ "GenSigTimeoutTime_SGW" SG_ 1030 LVDC_CurrentSetpointFdbk 0;
BA_ "GenSigTimeoutTime_IDCM" SG_ 1030 LVDC_CurrentSetpointFdbk 0;
BA_ "GenSigTimeoutTime_EVCU2" SG_ 1030 LVDC_CurrentSetpointFdbk 0;
BA_ "GenSigTimeoutTime_BPCM" SG_ 1030 LVDC_CurrentSetpointFdbk 0;
BA_ "GenSigStartValue" SG_ 1030 LVDC_CurrentSetpointFdbk 508;
BA_ "GenSigTimeoutTime_PPIM" SG_ 1030 LVDC_CurrentSetpointFdbk 0;
BA_ "GenSigTimeoutTime_SGW" SG_ 1030 HVDC_VoltageSetpointFdbk 0;
BA_ "GenSigTimeoutTime_IDCM" SG_ 1030 HVDC_VoltageSetpointFdbk 0;
BA_ "GenSigTimeoutTime_EVCU2" SG_ 1030 HVDC_VoltageSetpointFdbk 0;
BA_ "GenSigTimeoutTime_BPCM" SG_ 1030 HVDC_VoltageSetpointFdbk 0;
BA_ "GenSigTimeoutTime_PPIM" SG_ 1030 HVDC_VoltageSetpointFdbk 0;
BA_ "GenSigTimeoutTime_SGW" SG_ 1030 HVDC_CurrentSetpointFdbk 0;
BA_ "GenSigTimeoutTime_IDCM" SG_ 1030 HVDC_CurrentSetpointFdbk 0;
BA_ "GenSigTimeoutTime_EVCU2" SG_ 1030 HVDC_CurrentSetpointFdbk 0;
BA_ "GenSigTimeoutTime_BPCM" SG_ 1030 HVDC_CurrentSetpointFdbk 0;
BA_ "GenSigStartValue" SG_ 1030 HVDC_CurrentSetpointFdbk 1021;
BA_ "GenSigTimeoutTime_PPIM" SG_ 1030 HVDC_CurrentSetpointFdbk 0;
BA_ "GenSigTimeoutTime_SGW" SG_ 1030 DCDC_InternalMode 0;
BA_ "GenSigTimeoutTime_IDCM" SG_ 1030 DCDC_InternalMode 0;
BA_ "GenSigTimeoutTime_EVCU2" SG_ 1030 DCDC_InternalMode 0;
BA_ "GenSigTimeoutTime_BPCM" SG_ 1030 DCDC_InternalMode 0;
BA_ "GenSigTimeoutTime_PPIM" SG_ 1030 DCDC_InternalMode 0;
BA_ "GenSigTimeoutTime_SGW" SG_ 1030 DCDC_FailureType 0;
BA_ "GenSigTimeoutTime_IDCM" SG_ 1030 DCDC_FailureType 0;
BA_ "GenSigTimeoutTime_EVCU2" SG_ 1030 DCDC_FailureType 0;
BA_ "GenSigTimeoutTime_BPCM" SG_ 1030 DCDC_FailureType 0;
BA_ "GenSigTimeoutTime_PPIM" SG_ 1030 DCDC_FailureType 0;
BA_ "GenSigTimeoutTime_SGW" SG_ 1030 DCDC_EstimatedPowerLoss 0;
BA_ "GenSigTimeoutTime_IDCM" SG_ 1030 DCDC_EstimatedPowerLoss 0;
BA_ "GenSigTimeoutTime_EVCU2" SG_ 1030 DCDC_EstimatedPowerLoss 0;
BA_ "GenSigTimeoutTime_BPCM" SG_ 1030 DCDC_EstimatedPowerLoss 0;
BA_ "GenSigTimeoutTime_PPIM" SG_ 1030 DCDC_EstimatedPowerLoss 0;
BA_ "GenSigStartValue" SG_ 753 LVDC_CurrentFeedback 4095;
BA_ "GenSigTimeoutTime_PPIM" SG_ 753 LVDC_CurrentFeedback 0;
BA_ "GenSigTimeoutTime_SGW" SG_ 753 LVDC_CurrentFeedback 0;
BA_ "GenSigTimeoutTime_IDCM" SG_ 753 LVDC_CurrentFeedback 0;
BA_ "GenSigTimeoutTime_EVCU2" SG_ 753 LVDC_CurrentFeedback 0;
BA_ "GenSigTimeoutTime_BPCM" SG_ 753 LVDC_CurrentFeedback 0;
BA_ "GenSigTimeoutTime_SGW" SG_ 753 DCDC_OperationModeSts 0;
BA_ "GenSigTimeoutTime_IDCM" SG_ 753 DCDC_OperationModeSts 0;
BA_ "GenSigTimeoutTime_EVCU2" SG_ 753 DCDC_OperationModeSts 0;
BA_ "GenSigTimeoutTime_BPCM" SG_ 753 DCDC_OperationModeSts 0;
BA_ "GenSigTimeoutTime_PPIM" SG_ 753 DCDC_OperationModeSts 0;
BA_ "GenSigTimeoutTime_SGW" SG_ 753 MessageCounter_LV_CHARGER1 0;
BA_ "GenSigTimeoutTime_IDCM" SG_ 753 MessageCounter_LV_CHARGER1 0;
BA_ "GenSigTimeoutTime_EVCU2" SG_ 753 MessageCounter_LV_CHARGER1 0;
BA_ "GenSigTimeoutTime_BPCM" SG_ 753 MessageCounter_LV_CHARGER1 0;
BA_ "GenSigTimeoutTime_SGW" SG_ 753 CRC_LV_CHARGER1 0;
BA_ "GenSigTimeoutTime_IDCM" SG_ 753 CRC_LV_CHARGER1 0;
BA_ "GenSigTimeoutTime_EVCU2" SG_ 753 CRC_LV_CHARGER1 0;
BA_ "GenSigTimeoutTime_BPCM" SG_ 753 CRC_LV_CHARGER1 0;
BA_ "GenSigTimeoutTime_SGW" SG_ 753 LVDC_VoltageFeedback 0;
BA_ "GenSigTimeoutTime_IDCM" SG_ 753 LVDC_VoltageFeedback 0;
BA_ "GenSigTimeoutTime_EVCU2" SG_ 753 LVDC_VoltageFeedback 0;
BA_ "GenSigTimeoutTime_BPCM" SG_ 753 LVDC_VoltageFeedback 0;
BA_ "GenSigTimeoutTime_PPIM" SG_ 753 LVDC_VoltageFeedback 0;
BA_ "GenSigTimeoutTime_SGW" SG_ 753 HVDC_VoltageFeedback 0;
BA_ "GenSigTimeoutTime_IDCM" SG_ 753 HVDC_VoltageFeedback 0;
BA_ "GenSigTimeoutTime_EVCU2" SG_ 753 HVDC_VoltageFeedback 0;
BA_ "GenSigTimeoutTime_BPCM" SG_ 753 HVDC_VoltageFeedback 0;
BA_ "GenSigTimeoutTime_PPIM" SG_ 753 HVDC_VoltageFeedback 0;
BA_ "GenSigTimeoutTime_SGW" SG_ 753 HVDC_CurrentFeedback 0;
BA_ "GenSigTimeoutTime_IDCM" SG_ 753 HVDC_CurrentFeedback 0;
BA_ "GenSigTimeoutTime_EVCU2" SG_ 753 HVDC_CurrentFeedback 0;
BA_ "GenSigTimeoutTime_BPCM" SG_ 753 HVDC_CurrentFeedback 0;
BA_ "GenSigStartValue" SG_ 753 HVDC_CurrentFeedback 1021;
BA_ "GenSigTimeoutTime_PPIM" SG_ 753 HVDC_CurrentFeedback 0;
BA_ "GenSigTimeoutTime_SGW" SG_ 753 IDCM_Wakeup_HCP 0;
BA_ "GenSigTimeoutTime_IDCM" SG_ 753 IDCM_Wakeup_HCP 0;
BA_ "GenSigTimeoutTime_BPCM" SG_ 753 IDCM_Wakeup_HCP 0;
BA_ "GenSigTimeoutTime_PPIM" SG_ 753 IDCM_Wakeup_HCP 0;
BA_ "GenSigTimeoutTime_HCP" SG_ 753 IDCM_Wakeup_HCP 0;
BA_ "GenSigTimeoutTime_SGW" SG_ 752 IBS3_Vbatt 0;
BA_ "GenSigTimeoutTime_IDCM" SG_ 752 IBS3_Vbatt 0;
BA_ "GenSigTimeoutTime_EVCU2" SG_ 752 IBS3_Vbatt 0;
BA_ "GenSigStartValue" SG_ 752 IBS3_Vbatt 511;
BA_ "GenSigTimeoutTime_PPIM" SG_ 752 IBS3_Vbatt 0;
BA_ "GenSigTimeoutTime_HCP" SG_ 752 IBS3_Vbatt 0;
BA_ "GenSigTimeoutTime_SGW" SG_ 267 MessageCounter_HYBRID_SYSTEM_EPT 0;
BA_ "GenSigTimeoutTime_IDCM" SG_ 267 MessageCounter_HYBRID_SYSTEM_EPT 0;
BA_ "GenSigTimeoutTime_EVCU2" SG_ 267 MessageCounter_HYBRID_SYSTEM_EPT 0;
BA_ "GenSigTimeoutTime_PPIM" SG_ 267 MessageCounter_HYBRID_SYSTEM_EPT 0;
BA_ "GenSigTimeoutTime_HCP" SG_ 267 MessageCounter_HYBRID_SYSTEM_EPT 0;
BA_ "SystemSignalLongSymbol" SG_ 267 MessageCounter_HYBRID_SYSTEM_EPT "MessageCounter_HYBRID_SYSTEM_EPT1";
BA_ "GenSigTimeoutTime_SGW" SG_ 267 LOC_DiagEnable_ePT 0;
BA_ "GenSigTimeoutTime_IDCM" SG_ 267 LOC_DiagEnable_ePT 0;
BA_ "GenSigTimeoutTime_EVCU2" SG_ 267 LOC_DiagEnable_ePT 0;
BA_ "GenSigTimeoutTime_PPIM" SG_ 267 LOC_DiagEnable_ePT 0;
BA_ "GenSigTimeoutTime_HCP" SG_ 267 LOC_DiagEnable_ePT 0;
BA_ "GenSigTimeoutTime_IDCM" SG_ 267 HybridDriveModeSts 0;
BA_ "GenSigTimeoutTime_EVCU2" SG_ 267 HybridDriveModeSts 0;
BA_ "GenSigTimeoutTime_BPCM" SG_ 267 HybridDriveModeSts 0;
BA_ "GenSigTimeoutTime_SGW" SG_ 267 HybridDriveModeSts 0;
BA_ "GenSigTimeoutTime_PPIM" SG_ 267 HybridDriveModeSts 0;
BA_ "GenSigTimeoutTime_HCP" SG_ 267 HybridDriveModeSts 0;
BA_ "GenSigTimeoutTime_SGW" SG_ 267 HCP_ShutdownCommand 0;
BA_ "GenSigTimeoutTime_IDCM" SG_ 267 HCP_ShutdownCommand 0;
BA_ "GenSigTimeoutTime_EVCU2" SG_ 267 HCP_ShutdownCommand 0;
BA_ "GenSigTimeoutTime_PPIM" SG_ 267 HCP_ShutdownCommand 0;
BA_ "GenSigTimeoutTime_HCP" SG_ 267 HCP_ShutdownCommand 0;
BA_ "GenSigTimeoutTime_SGW" SG_ 267 CRC_HYBRID_SYSTEM_EPT1 0;
BA_ "GenSigTimeoutTime_IDCM" SG_ 267 CRC_HYBRID_SYSTEM_EPT1 0;
BA_ "GenSigTimeoutTime_EVCU2" SG_ 267 CRC_HYBRID_SYSTEM_EPT1 0;
BA_ "GenSigTimeoutTime_PPIM" SG_ 267 CRC_HYBRID_SYSTEM_EPT1 0;
BA_ "GenSigTimeoutTime_HCP" SG_ 267 CRC_HYBRID_SYSTEM_EPT1 0;
BA_ "GenSigTimeoutTime_SGW" SG_ 267 WU_Timer_Value 0;
BA_ "GenSigTimeoutTime_EVCU2" SG_ 267 WU_Timer_Value 0;
BA_ "GenSigTimeoutTime_PPIM" SG_ 267 WU_Timer_Value 0;
BA_ "GenSigTimeoutTime_HCP" SG_ 267 WU_Timer_Value 0;
BA_ "GenSigTimeoutTime_SGW" SG_ 267 PerWakeUp_Diag 0;
BA_ "GenSigTimeoutTime_EVCU2" SG_ 267 PerWakeUp_Diag 0;
BA_ "GenSigTimeoutTime_PPIM" SG_ 267 PerWakeUp_Diag 0;
BA_ "GenSigTimeoutTime_HCP" SG_ 267 PerWakeUp_Diag 0;
BA_ "GenSigTimeoutTime_SGW" SG_ 267 PropulsionSystemActive_10B 0;
BA_ "GenSigTimeoutTime_IDCM" SG_ 267 PropulsionSystemActive_10B 0;
BA_ "GenSigTimeoutTime_EVCU2" SG_ 267 PropulsionSystemActive_10B 0;
BA_ "GenSigTimeoutTime_PPIM" SG_ 267 PropulsionSystemActive_10B 0;
BA_ "GenSigTimeoutTime_HCP" SG_ 267 PropulsionSystemActive_10B 0;
BA_ "GenSigTimeoutTime_IDCM" SG_ 1956 MotorB_Temperature 0;
BA_ "GenSigTimeoutTime_EVCU2" SG_ 1956 MotorB_Temperature 0;
BA_ "GenSigTimeoutTime_BPCM" SG_ 1956 MotorB_Temperature 0;
BA_ "GenSigStartValue" SG_ 1956 MotorB_Temperature 40;
BA_ "GenSigTimeoutTime_PPIM" SG_ 1956 MotorB_Temperature 0;
BA_ "GenSigTimeoutTime_HCP" SG_ 1956 MotorB_Temperature 0;
BA_ "GenSigTimeoutTime_IDCM" SG_ 1956 MotorB_RPM 0;
BA_ "GenSigTimeoutTime_EVCU2" SG_ 1956 MotorB_RPM 0;
BA_ "GenSigTimeoutTime_BPCM" SG_ 1956 MotorB_RPM 0;
BA_ "GenSigStartValue" SG_ 1956 MotorB_RPM 32768;
BA_ "GenSigTimeoutTime_PPIM" SG_ 1956 MotorB_RPM 0;
BA_ "GenSigTimeoutTime_HCP" SG_ 1956 MotorB_RPM 0;
BA_ "GenSigTimeoutTime_IDCM" SG_ 1956 MotorB_InverterTemp 0;
BA_ "GenSigTimeoutTime_EVCU2" SG_ 1956 MotorB_InverterTemp 0;
BA_ "GenSigTimeoutTime_BPCM" SG_ 1956 MotorB_InverterTemp 0;
BA_ "GenSigStartValue" SG_ 1956 MotorB_InverterTemp 40;
BA_ "GenSigTimeoutTime_PPIM" SG_ 1956 MotorB_InverterTemp 0;
BA_ "GenSigTimeoutTime_HCP" SG_ 1956 MotorB_InverterTemp 0;
BA_ "GenSigTimeoutTime_IDCM" SG_ 1956 MotorB_DC_Voltage 0;
BA_ "GenSigTimeoutTime_EVCU2" SG_ 1956 MotorB_DC_Voltage 0;
BA_ "GenSigTimeoutTime_BPCM" SG_ 1956 MotorB_DC_Voltage 0;
BA_ "GenSigTimeoutTime_PPIM" SG_ 1956 MotorB_DC_Voltage 0;
BA_ "GenSigTimeoutTime_HCP" SG_ 1956 MotorB_DC_Voltage 0;
BA_ "GenSigTimeoutTime_IDCM" SG_ 1956 MotorB_DC_Current 0;
BA_ "GenSigTimeoutTime_EVCU2" SG_ 1956 MotorB_DC_Current 0;
BA_ "GenSigTimeoutTime_BPCM" SG_ 1956 MotorB_DC_Current 0;
BA_ "GenSigStartValue" SG_ 1956 MotorB_DC_Current 16384;
BA_ "GenSigTimeoutTime_PPIM" SG_ 1956 MotorB_DC_Current 0;
BA_ "GenSigTimeoutTime_HCP" SG_ 1956 MotorB_DC_Current 0;
BA_ "GenSigTimeoutTime_IDCM" SG_ 1956 MotorA_Temperature 0;
BA_ "GenSigTimeoutTime_EVCU2" SG_ 1956 MotorA_Temperature 0;
BA_ "GenSigTimeoutTime_BPCM" SG_ 1956 MotorA_Temperature 0;
BA_ "GenSigStartValue" SG_ 1956 MotorA_Temperature 40;
BA_ "GenSigTimeoutTime_PPIM" SG_ 1956 MotorA_Temperature 0;
BA_ "GenSigTimeoutTime_HCP" SG_ 1956 MotorA_Temperature 0;
BA_ "GenSigTimeoutTime_IDCM" SG_ 1956 MotorA_RPM 0;
BA_ "GenSigTimeoutTime_EVCU2" SG_ 1956 MotorA_RPM 0;
BA_ "GenSigTimeoutTime_BPCM" SG_ 1956 MotorA_RPM 0;
BA_ "GenSigStartValue" SG_ 1956 MotorA_RPM 32768;
BA_ "GenSigTimeoutTime_PPIM" SG_ 1956 MotorA_RPM 0;
BA_ "GenSigTimeoutTime_HCP" SG_ 1956 MotorA_RPM 0;
BA_ "GenSigTimeoutTime_IDCM" SG_ 1956 MotorA_InverterTemp 0;
BA_ "GenSigTimeoutTime_EVCU2" SG_ 1956 MotorA_InverterTemp 0;
BA_ "GenSigTimeoutTime_BPCM" SG_ 1956 MotorA_InverterTemp 0;
BA_ "GenSigStartValue" SG_ 1956 MotorA_InverterTemp 40;
BA_ "GenSigTimeoutTime_PPIM" SG_ 1956 MotorA_InverterTemp 0;
BA_ "GenSigTimeoutTime_HCP" SG_ 1956 MotorA_InverterTemp 0;
BA_ "GenSigTimeoutTime_IDCM" SG_ 1956 MotorA_DC_Voltage 0;
BA_ "GenSigTimeoutTime_EVCU2" SG_ 1956 MotorA_DC_Voltage 0;
BA_ "GenSigTimeoutTime_BPCM" SG_ 1956 MotorA_DC_Voltage 0;
BA_ "GenSigTimeoutTime_PPIM" SG_ 1956 MotorA_DC_Voltage 0;
BA_ "GenSigTimeoutTime_HCP" SG_ 1956 MotorA_DC_Voltage 0;
BA_ "GenSigTimeoutTime_IDCM" SG_ 1956 MotorA_DC_Current 0;
BA_ "GenSigTimeoutTime_EVCU2" SG_ 1956 MotorA_DC_Current 0;
BA_ "GenSigTimeoutTime_BPCM" SG_ 1956 MotorA_DC_Current 0;
BA_ "GenSigStartValue" SG_ 1956 MotorA_DC_Current 16384;
BA_ "GenSigTimeoutTime_PPIM" SG_ 1956 MotorA_DC_Current 0;
BA_ "GenSigTimeoutTime_HCP" SG_ 1956 MotorA_DC_Current 0;
BA_ "GenSigTimeoutTime_IDCM" SG_ 1956 Warning_MotorB_Overtemp 0;
BA_ "GenSigTimeoutTime_EVCU2" SG_ 1956 Warning_MotorB_Overtemp 0;
BA_ "GenSigTimeoutTime_BPCM" SG_ 1956 Warning_MotorB_Overtemp 0;
BA_ "GenSigTimeoutTime_PPIM" SG_ 1956 Warning_MotorB_Overtemp 0;
BA_ "GenSigTimeoutTime_HCP" SG_ 1956 Warning_MotorB_Overtemp 0;
BA_ "GenSigTimeoutTime_IDCM" SG_ 1956 Warning_MotorA_Overtemp 0;
BA_ "GenSigTimeoutTime_EVCU2" SG_ 1956 Warning_MotorA_Overtemp 0;
BA_ "GenSigTimeoutTime_BPCM" SG_ 1956 Warning_MotorA_Overtemp 0;
BA_ "GenSigTimeoutTime_PPIM" SG_ 1956 Warning_MotorA_Overtemp 0;
BA_ "GenSigTimeoutTime_HCP" SG_ 1956 Warning_MotorA_Overtemp 0;
BA_ "GenSigTimeoutTime_IDCM" SG_ 1956 Warning_InverterA_Overtemp 0;
BA_ "GenSigTimeoutTime_EVCU2" SG_ 1956 Warning_InverterA_Overtemp 0;
BA_ "GenSigTimeoutTime_BPCM" SG_ 1956 Warning_InverterA_Overtemp 0;
BA_ "GenSigTimeoutTime_PPIM" SG_ 1956 Warning_InverterA_Overtemp 0;
BA_ "GenSigTimeoutTime_HCP" SG_ 1956 Warning_InverterA_Overtemp 0;
BA_ "GenSigTimeoutTime_IDCM" SG_ 1956 Warning_DCDCTemp_DPT 0;
BA_ "GenSigTimeoutTime_EVCU2" SG_ 1956 Warning_DCDCTemp_DPT 0;
BA_ "GenSigTimeoutTime_BPCM" SG_ 1956 Warning_DCDCTemp_DPT 0;
BA_ "GenSigTimeoutTime_PPIM" SG_ 1956 Warning_DCDCTemp_DPT 0;
BA_ "GenSigTimeoutTime_HCP" SG_ 1956 Warning_DCDCTemp_DPT 0;
BA_ "GenSigTimeoutTime_IDCM" SG_ 1956 Warning_DCDCPerformance_DPT 0;
BA_ "GenSigTimeoutTime_EVCU2" SG_ 1956 Warning_DCDCPerformance_DPT 0;
BA_ "GenSigTimeoutTime_BPCM" SG_ 1956 Warning_DCDCPerformance_DPT 0;
BA_ "GenSigTimeoutTime_PPIM" SG_ 1956 Warning_DCDCPerformance_DPT 0;
BA_ "GenSigTimeoutTime_HCP" SG_ 1956 Warning_DCDCPerformance_DPT 0;
BA_ "GenSigTimeoutTime_IDCM" SG_ 1956 MotorB_InverterState 0;
BA_ "GenSigTimeoutTime_EVCU2" SG_ 1956 MotorB_InverterState 0;
BA_ "GenSigTimeoutTime_BPCM" SG_ 1956 MotorB_InverterState 0;
BA_ "GenSigTimeoutTime_PPIM" SG_ 1956 MotorB_InverterState 0;
BA_ "GenSigTimeoutTime_HCP" SG_ 1956 MotorB_InverterState 0;
BA_ "GenSigTimeoutTime_IDCM" SG_ 1956 MotorA_InverterState 0;
BA_ "GenSigTimeoutTime_EVCU2" SG_ 1956 MotorA_InverterState 0;
BA_ "GenSigTimeoutTime_BPCM" SG_ 1956 MotorA_InverterState 0;
BA_ "GenSigTimeoutTime_PPIM" SG_ 1956 MotorA_InverterState 0;
BA_ "GenSigTimeoutTime_HCP" SG_ 1956 MotorA_InverterState 0;
BA_ "GenSigTimeoutTime_IDCM" SG_ 1956 Warning_InverterB_Overtemp 0;
BA_ "GenSigTimeoutTime_EVCU2" SG_ 1956 Warning_InverterB_Overtemp 0;
BA_ "GenSigTimeoutTime_BPCM" SG_ 1956 Warning_InverterB_Overtemp 0;
BA_ "GenSigTimeoutTime_PPIM" SG_ 1956 Warning_InverterB_Overtemp 0;
BA_ "GenSigTimeoutTime_HCP" SG_ 1956 Warning_InverterB_Overtemp 0;
BA_ "GenSigTimeoutTime_IDCM" SG_ 1956 MotorB_TorqueAchieved 0;
BA_ "GenSigTimeoutTime_EVCU2" SG_ 1956 MotorB_TorqueAchieved 0;
BA_ "GenSigTimeoutTime_BPCM" SG_ 1956 MotorB_TorqueAchieved 0;
BA_ "GenSigStartValue" SG_ 1956 MotorB_TorqueAchieved 4096;
BA_ "GenSigTimeoutTime_PPIM" SG_ 1956 MotorB_TorqueAchieved 0;
BA_ "GenSigTimeoutTime_HCP" SG_ 1956 MotorB_TorqueAchieved 0;
BA_ "GenSigTimeoutTime_IDCM" SG_ 1956 MotorA_TorqueAchieved 0;
BA_ "GenSigTimeoutTime_EVCU2" SG_ 1956 MotorA_TorqueAchieved 0;
BA_ "GenSigTimeoutTime_BPCM" SG_ 1956 MotorA_TorqueAchieved 0;
BA_ "GenSigStartValue" SG_ 1956 MotorA_TorqueAchieved 4096;
BA_ "GenSigTimeoutTime_PPIM" SG_ 1956 MotorA_TorqueAchieved 0;
BA_ "GenSigTimeoutTime_HCP" SG_ 1956 MotorA_TorqueAchieved 0;
BA_ "GenSigTimeoutTime_SGW" SG_ 1033 MCP_DC_Current 0;
BA_ "GenSigTimeoutTime_IDCM" SG_ 1033 MCP_DC_Current 0;
BA_ "GenSigTimeoutTime_EVCU2" SG_ 1033 MCP_DC_Current 0;
BA_ "GenSigTimeoutTime_PPIM" SG_ 1033 MCP_DC_Current 0;
BA_ "GenSigTimeoutTime_HCP" SG_ 1033 MCP_DC_Current 0;
BA_ "GenSigTimeoutTime_SGW" SG_ 1033 MCP_DC_CurrentV 0;
BA_ "GenSigTimeoutTime_IDCM" SG_ 1033 MCP_DC_CurrentV 0;
BA_ "GenSigTimeoutTime_EVCU2" SG_ 1033 MCP_DC_CurrentV 0;
BA_ "GenSigTimeoutTime_PPIM" SG_ 1033 MCP_DC_CurrentV 0;
BA_ "GenSigTimeoutTime_HCP" SG_ 1033 MCP_DC_CurrentV 0;
BA_ "GenSigTimeoutTime_SGW" SG_ 1834 HVBattery_RealTimeClockV 0;
BA_ "GenSigTimeoutTime_IDCM" SG_ 1834 HVBattery_RealTimeClockV 0;
BA_ "GenSigTimeoutTime_BPCM" SG_ 1834 HVBattery_RealTimeClockV 0;
BA_ "GenSigTimeoutTime_PPIM" SG_ 1834 HVBattery_RealTimeClockV 0;
BA_ "GenSigTimeoutTime_HCP" SG_ 1834 HVBattery_RealTimeClockV 0;
BA_ "GenSigTimeoutTime_SGW" SG_ 1834 HVBattery_RealTimeClock 0;
BA_ "GenSigTimeoutTime_IDCM" SG_ 1834 HVBattery_RealTimeClock 0;
BA_ "GenSigTimeoutTime_BPCM" SG_ 1834 HVBattery_RealTimeClock 0;
BA_ "GenSigTimeoutTime_PPIM" SG_ 1834 HVBattery_RealTimeClock 0;
BA_ "GenSigTimeoutTime_HCP" SG_ 1834 HVBattery_RealTimeClock 0;
BA_ "GenSigTimeoutTime_SGW" SG_ 1834 HVBatteryBalanceMode 0;
BA_ "GenSigTimeoutTime_IDCM" SG_ 1834 HVBatteryBalanceMode 0;
BA_ "GenSigTimeoutTime_EVCU2" SG_ 1834 HVBatteryBalanceMode 0;
BA_ "GenSigTimeoutTime_BPCM" SG_ 1834 HVBatteryBalanceMode 0;
BA_ "GenSigTimeoutTime_PPIM" SG_ 1834 HVBatteryBalanceMode 0;
BA_ "GenSigTimeoutTime_SGW" SG_ 1834 HVBatteryBalanceComplete 0;
BA_ "GenSigTimeoutTime_IDCM" SG_ 1834 HVBatteryBalanceComplete 0;
BA_ "GenSigTimeoutTime_EVCU2" SG_ 1834 HVBatteryBalanceComplete 0;
BA_ "GenSigTimeoutTime_BPCM" SG_ 1834 HVBatteryBalanceComplete 0;
BA_ "GenSigTimeoutTime_PPIM" SG_ 1834 HVBatteryBalanceComplete 0;
BA_ "GenSigTimeoutTime_SGW" SG_ 1834 HVBatCellOCVoltage_MinV 0;
BA_ "GenSigTimeoutTime_IDCM" SG_ 1834 HVBatCellOCVoltage_MinV 0;
BA_ "GenSigTimeoutTime_EVCU2" SG_ 1834 HVBatCellOCVoltage_MinV 0;
BA_ "GenSigTimeoutTime_BPCM" SG_ 1834 HVBatCellOCVoltage_MinV 0;
BA_ "GenSigTimeoutTime_PPIM" SG_ 1834 HVBatCellOCVoltage_MinV 0;
BA_ "GenSigTimeoutTime_SGW" SG_ 1834 HVBatCellOCVoltage_Min 0;
BA_ "GenSigTimeoutTime_IDCM" SG_ 1834 HVBatCellOCVoltage_Min 0;
BA_ "GenSigTimeoutTime_EVCU2" SG_ 1834 HVBatCellOCVoltage_Min 0;
BA_ "GenSigTimeoutTime_BPCM" SG_ 1834 HVBatCellOCVoltage_Min 0;
BA_ "GenSigTimeoutTime_PPIM" SG_ 1834 HVBatCellOCVoltage_Min 0;
BA_ "GenSigTimeoutTime_SGW" SG_ 1834 HVBatCellOCVoltage_MaxV 0;
BA_ "GenSigTimeoutTime_IDCM" SG_ 1834 HVBatCellOCVoltage_MaxV 0;
BA_ "GenSigTimeoutTime_EVCU2" SG_ 1834 HVBatCellOCVoltage_MaxV 0;
BA_ "GenSigTimeoutTime_BPCM" SG_ 1834 HVBatCellOCVoltage_MaxV 0;
BA_ "GenSigTimeoutTime_PPIM" SG_ 1834 HVBatCellOCVoltage_MaxV 0;
BA_ "GenSigTimeoutTime_SGW" SG_ 1834 HVBatCellOCVoltage_Max 0;
BA_ "GenSigTimeoutTime_IDCM" SG_ 1834 HVBatCellOCVoltage_Max 0;
BA_ "GenSigTimeoutTime_EVCU2" SG_ 1834 HVBatCellOCVoltage_Max 0;
BA_ "GenSigTimeoutTime_BPCM" SG_ 1834 HVBatCellOCVoltage_Max 0;
BA_ "GenSigTimeoutTime_PPIM" SG_ 1834 HVBatCellOCVoltage_Max 0;
BA_ "GenSigTimeoutTime_SGW" SG_ 1834 HVBatCellOCVoltage_AverageV 0;
BA_ "GenSigTimeoutTime_IDCM" SG_ 1834 HVBatCellOCVoltage_AverageV 0;
BA_ "GenSigTimeoutTime_EVCU2" SG_ 1834 HVBatCellOCVoltage_AverageV 0;
BA_ "GenSigTimeoutTime_BPCM" SG_ 1834 HVBatCellOCVoltage_AverageV 0;
BA_ "GenSigTimeoutTime_PPIM" SG_ 1834 HVBatCellOCVoltage_AverageV 0;
BA_ "GenSigTimeoutTime_SGW" SG_ 1834 HVBatCellOCVoltage_Average 0;
BA_ "GenSigTimeoutTime_IDCM" SG_ 1834 HVBatCellOCVoltage_Average 0;
BA_ "GenSigTimeoutTime_EVCU2" SG_ 1834 HVBatCellOCVoltage_Average 0;
BA_ "GenSigTimeoutTime_BPCM" SG_ 1834 HVBatCellOCVoltage_Average 0;
BA_ "GenSigTimeoutTime_PPIM" SG_ 1834 HVBatCellOCVoltage_Average 0;
BA_ "GenSigTimeoutTime_SGW" SG_ 1834 HVBatCellDischargeImped_Min 0;
BA_ "GenSigTimeoutTime_IDCM" SG_ 1834 HVBatCellDischargeImped_Min 0;
BA_ "GenSigTimeoutTime_EVCU2" SG_ 1834 HVBatCellDischargeImped_Min 0;
BA_ "GenSigTimeoutTime_BPCM" SG_ 1834 HVBatCellDischargeImped_Min 0;
BA_ "GenSigTimeoutTime_PPIM" SG_ 1834 HVBatCellDischargeImped_Min 0;
BA_ "GenSigTimeoutTime_SGW" SG_ 1834 HVBatCellDischargeImped_Max 0;
BA_ "GenSigTimeoutTime_IDCM" SG_ 1834 HVBatCellDischargeImped_Max 0;
BA_ "GenSigTimeoutTime_EVCU2" SG_ 1834 HVBatCellDischargeImped_Max 0;
BA_ "GenSigTimeoutTime_BPCM" SG_ 1834 HVBatCellDischargeImped_Max 0;
BA_ "GenSigTimeoutTime_PPIM" SG_ 1834 HVBatCellDischargeImped_Max 0;
BA_ "GenSigTimeoutTime_SGW" SG_ 1029 HVBatPowerLimited 0;
BA_ "GenSigTimeoutTime_IDCM" SG_ 1029 HVBatPowerLimited 0;
BA_ "GenSigTimeoutTime_EVCU2" SG_ 1029 HVBatPowerLimited 0;
BA_ "GenSigTimeoutTime_BPCM" SG_ 1029 HVBatPowerLimited 0;
BA_ "GenSigTimeoutTime_PPIM" SG_ 1029 HVBatPowerLimited 0;
BA_ "GenSigTimeoutTime_SGW" SG_ 1029 BSGDischargePower_ShortV 0;
BA_ "GenSigTimeoutTime_IDCM" SG_ 1029 BSGDischargePower_ShortV 0;
BA_ "GenSigTimeoutTime_EVCU2" SG_ 1029 BSGDischargePower_ShortV 0;
BA_ "GenSigTimeoutTime_BPCM" SG_ 1029 BSGDischargePower_ShortV 0;
BA_ "GenSigTimeoutTime_PPIM" SG_ 1029 BSGDischargePower_ShortV 0;
BA_ "GenSigTimeoutTime_SGW" SG_ 1029 BSGDischargePower_Short 0;
BA_ "GenSigTimeoutTime_IDCM" SG_ 1029 BSGDischargePower_Short 0;
BA_ "GenSigTimeoutTime_EVCU2" SG_ 1029 BSGDischargePower_Short 0;
BA_ "GenSigTimeoutTime_BPCM" SG_ 1029 BSGDischargePower_Short 0;
BA_ "GenSigTimeoutTime_PPIM" SG_ 1029 BSGDischargePower_Short 0;
BA_ "GenSigTimeoutTime_SGW" SG_ 1029 BSGDischargePower_LongV 0;
BA_ "GenSigTimeoutTime_IDCM" SG_ 1029 BSGDischargePower_LongV 0;
BA_ "GenSigTimeoutTime_EVCU2" SG_ 1029 BSGDischargePower_LongV 0;
BA_ "GenSigTimeoutTime_BPCM" SG_ 1029 BSGDischargePower_LongV 0;
BA_ "GenSigTimeoutTime_PPIM" SG_ 1029 BSGDischargePower_LongV 0;
BA_ "GenSigTimeoutTime_SGW" SG_ 1029 BSGDischargePower_Long 0;
BA_ "GenSigTimeoutTime_IDCM" SG_ 1029 BSGDischargePower_Long 0;
BA_ "GenSigTimeoutTime_EVCU2" SG_ 1029 BSGDischargePower_Long 0;
BA_ "GenSigTimeoutTime_BPCM" SG_ 1029 BSGDischargePower_Long 0;
BA_ "GenSigTimeoutTime_PPIM" SG_ 1029 BSGDischargePower_Long 0;
BA_ "GenSigTimeoutTime_SGW" SG_ 1029 BSGDischargePower_InstantV 0;
BA_ "GenSigTimeoutTime_IDCM" SG_ 1029 BSGDischargePower_InstantV 0;
BA_ "GenSigTimeoutTime_EVCU2" SG_ 1029 BSGDischargePower_InstantV 0;
BA_ "GenSigTimeoutTime_BPCM" SG_ 1029 BSGDischargePower_InstantV 0;
BA_ "GenSigTimeoutTime_PPIM" SG_ 1029 BSGDischargePower_InstantV 0;
BA_ "GenSigTimeoutTime_SGW" SG_ 1029 BSGDischargePower_Instant 0;
BA_ "GenSigTimeoutTime_IDCM" SG_ 1029 BSGDischargePower_Instant 0;
BA_ "GenSigTimeoutTime_EVCU2" SG_ 1029 BSGDischargePower_Instant 0;
BA_ "GenSigTimeoutTime_BPCM" SG_ 1029 BSGDischargePower_Instant 0;
BA_ "GenSigTimeoutTime_PPIM" SG_ 1029 BSGDischargePower_Instant 0;
BA_ "GenSigTimeoutTime_SGW" SG_ 1029 BSGChargePower_ShortV 0;
BA_ "GenSigTimeoutTime_IDCM" SG_ 1029 BSGChargePower_ShortV 0;
BA_ "GenSigTimeoutTime_EVCU2" SG_ 1029 BSGChargePower_ShortV 0;
BA_ "GenSigTimeoutTime_BPCM" SG_ 1029 BSGChargePower_ShortV 0;
BA_ "GenSigTimeoutTime_PPIM" SG_ 1029 BSGChargePower_ShortV 0;
BA_ "GenSigTimeoutTime_SGW" SG_ 1029 BSGChargePower_Short 0;
BA_ "GenSigTimeoutTime_IDCM" SG_ 1029 BSGChargePower_Short 0;
BA_ "GenSigTimeoutTime_EVCU2" SG_ 1029 BSGChargePower_Short 0;
BA_ "GenSigTimeoutTime_BPCM" SG_ 1029 BSGChargePower_Short 0;
BA_ "GenSigTimeoutTime_PPIM" SG_ 1029 BSGChargePower_Short 0;
BA_ "GenSigTimeoutTime_SGW" SG_ 1029 BSGChargePower_LongV 0;
BA_ "GenSigTimeoutTime_IDCM" SG_ 1029 BSGChargePower_LongV 0;
BA_ "GenSigTimeoutTime_EVCU2" SG_ 1029 BSGChargePower_LongV 0;
BA_ "GenSigTimeoutTime_BPCM" SG_ 1029 BSGChargePower_LongV 0;
BA_ "GenSigTimeoutTime_PPIM" SG_ 1029 BSGChargePower_LongV 0;
BA_ "GenSigTimeoutTime_SGW" SG_ 1029 BSGChargePower_Long 0;
BA_ "GenSigTimeoutTime_IDCM" SG_ 1029 BSGChargePower_Long 0;
BA_ "GenSigTimeoutTime_EVCU2" SG_ 1029 BSGChargePower_Long 0;
BA_ "GenSigTimeoutTime_BPCM" SG_ 1029 BSGChargePower_Long 0;
BA_ "GenSigTimeoutTime_PPIM" SG_ 1029 BSGChargePower_Long 0;
BA_ "GenSigTimeoutTime_SGW" SG_ 1029 BSGChargePower_InstantV 0;
BA_ "GenSigTimeoutTime_IDCM" SG_ 1029 BSGChargePower_InstantV 0;
BA_ "GenSigTimeoutTime_EVCU2" SG_ 1029 BSGChargePower_InstantV 0;
BA_ "GenSigTimeoutTime_BPCM" SG_ 1029 BSGChargePower_InstantV 0;
BA_ "GenSigTimeoutTime_PPIM" SG_ 1029 BSGChargePower_InstantV 0;
BA_ "GenSigTimeoutTime_SGW" SG_ 1029 BSGChargePower_Instant 0;
BA_ "GenSigTimeoutTime_IDCM" SG_ 1029 BSGChargePower_Instant 0;
BA_ "GenSigTimeoutTime_EVCU2" SG_ 1029 BSGChargePower_Instant 0;
BA_ "GenSigTimeoutTime_BPCM" SG_ 1029 BSGChargePower_Instant 0;
BA_ "GenSigTimeoutTime_PPIM" SG_ 1029 BSGChargePower_Instant 0;
BA_ "GenSigTimeoutTime_SGW" SG_ 1027 HVBatterySOCV 0;
BA_ "GenSigTimeoutTime_IDCM" SG_ 1027 HVBatterySOCV 0;
BA_ "GenSigTimeoutTime_EVCU2" SG_ 1027 HVBatterySOCV 0;
BA_ "GenSigTimeoutTime_BPCM" SG_ 1027 HVBatterySOCV 0;
BA_ "GenSigStartValue" SG_ 1027 HVBatterySOCV 1;
BA_ "GenSigTimeoutTime_PPIM" SG_ 1027 HVBatterySOCV 0;
BA_ "GenSigTimeoutTime_IDCM" SG_ 1027 HVBatterySOC 0;
BA_ "GenSigTimeoutTime_EVCU2" SG_ 1027 HVBatterySOC 0;
BA_ "GenSigTimeoutTime_BPCM" SG_ 1027 HVBatterySOC 0;
BA_ "GenSigStartValue" SG_ 1027 HVBatterySOC 2048;
BA_ "GenSigTimeoutTime_PPIM" SG_ 1027 HVBatterySOC 0;
BA_ "GenSigTimeoutTime_SGW" SG_ 1027 HVBatteryMILRequest 0;
BA_ "GenSigTimeoutTime_IDCM" SG_ 1027 HVBatteryMILRequest 0;
BA_ "GenSigTimeoutTime_EVCU2" SG_ 1027 HVBatteryMILRequest 0;
BA_ "GenSigTimeoutTime_BPCM" SG_ 1027 HVBatteryMILRequest 0;
BA_ "GenSigTimeoutTime_PPIM" SG_ 1027 HVBatteryMILRequest 0;
BA_ "GenSigTimeoutTime_SGW" SG_ 1027 HVBatterySOH 0;
BA_ "GenSigTimeoutTime_IDCM" SG_ 1027 HVBatterySOH 0;
BA_ "GenSigTimeoutTime_EVCU2" SG_ 1027 HVBatterySOH 0;
BA_ "GenSigTimeoutTime_BPCM" SG_ 1027 HVBatterySOH 0;
BA_ "GenSigStartValue" SG_ 1027 HVBatterySOH 250;
BA_ "GenSigTimeoutTime_PPIM" SG_ 1027 HVBatterySOH 0;
BA_ "GenSigTimeoutTime_SGW" SG_ 1027 HVBatterySOC_Min 0;
BA_ "GenSigTimeoutTime_IDCM" SG_ 1027 HVBatterySOC_Min 0;
BA_ "GenSigTimeoutTime_EVCU2" SG_ 1027 HVBatterySOC_Min 0;
BA_ "GenSigTimeoutTime_BPCM" SG_ 1027 HVBatterySOC_Min 0;
BA_ "GenSigStartValue" SG_ 1027 HVBatterySOC_Min 128;
BA_ "GenSigTimeoutTime_PPIM" SG_ 1027 HVBatterySOC_Min 0;
BA_ "GenSigTimeoutTime_PPIM" SG_ 1027 HVBatterySOC_Max 0;
BA_ "GenSigTimeoutTime_SGW" SG_ 1027 HVBatterySOC_Max 0;
BA_ "GenSigTimeoutTime_IDCM" SG_ 1027 HVBatterySOC_Max 0;
BA_ "GenSigTimeoutTime_EVCU2" SG_ 1027 HVBatterySOC_Max 0;
BA_ "GenSigTimeoutTime_BPCM" SG_ 1027 HVBatterySOC_Max 0;
BA_ "GenSigStartValue" SG_ 1027 HVBatterySOC_Max 128;
BA_ "GenSigTimeoutTime_SGW" SG_ 1027 HVBatteryServiceRequest 0;
BA_ "GenSigTimeoutTime_IDCM" SG_ 1027 HVBatteryServiceRequest 0;
BA_ "GenSigTimeoutTime_EVCU2" SG_ 1027 HVBatteryServiceRequest 0;
BA_ "GenSigTimeoutTime_BPCM" SG_ 1027 HVBatteryServiceRequest 0;
BA_ "GenSigTimeoutTime_PPIM" SG_ 1027 HVBatteryServiceRequest 0;
BA_ "GenSigTimeoutTime_SGW" SG_ 1027 PrechargePenaltyTimer 0;
BA_ "GenSigTimeoutTime_IDCM" SG_ 1027 PrechargePenaltyTimer 0;
BA_ "GenSigTimeoutTime_EVCU2" SG_ 1027 PrechargePenaltyTimer 0;
BA_ "GenSigTimeoutTime_BPCM" SG_ 1027 PrechargePenaltyTimer 0;
BA_ "GenSigTimeoutTime_PPIM" SG_ 1027 PrechargePenaltyTimer 0;
BA_ "GenSigTimeoutTime_SGW" SG_ 266 HVBatteryCurrent 0;
BA_ "GenSigTimeoutTime_IDCM" SG_ 266 HVBatteryCurrent 0;
BA_ "GenSigTimeoutTime_EVCU2" SG_ 266 HVBatteryCurrent 0;
BA_ "GenSigTimeoutTime_BPCM" SG_ 266 HVBatteryCurrent 0;
BA_ "GenSigTimeoutTime_PPIM" SG_ 266 HVBatteryCurrent 0;
BA_ "GenSigTimeoutTime_SGW" SG_ 266 HVBatContactorSts 0;
BA_ "GenSigTimeoutTime_IDCM" SG_ 266 HVBatContactorSts 0;
BA_ "GenSigTimeoutTime_EVCU2" SG_ 266 HVBatContactorSts 0;
BA_ "GenSigTimeoutTime_BPCM" SG_ 266 HVBatContactorSts 0;
BA_ "GenSigTimeoutTime_PPIM" SG_ 266 HVBatContactorSts 0;
BA_ "GenSigTimeoutTime_SGW" SG_ 266 HVBatCellVoltage_NumMax 0;
BA_ "GenSigTimeoutTime_IDCM" SG_ 266 HVBatCellVoltage_NumMax 0;
BA_ "GenSigTimeoutTime_EVCU2" SG_ 266 HVBatCellVoltage_NumMax 0;
BA_ "GenSigTimeoutTime_BPCM" SG_ 266 HVBatCellVoltage_NumMax 0;
BA_ "GenSigTimeoutTime_PPIM" SG_ 266 HVBatCellVoltage_NumMax 0;
BA_ "GenSigTimeoutTime_SGW" SG_ 266 HVBatCellVoltage_Min 0;
BA_ "GenSigTimeoutTime_IDCM" SG_ 266 HVBatCellVoltage_Min 0;
BA_ "GenSigTimeoutTime_EVCU2" SG_ 266 HVBatCellVoltage_Min 0;
BA_ "GenSigTimeoutTime_BPCM" SG_ 266 HVBatCellVoltage_Min 0;
BA_ "GenSigTimeoutTime_PPIM" SG_ 266 HVBatCellVoltage_Min 0;
BA_ "GenSigTimeoutTime_SGW" SG_ 266 HVBatCellVoltage_Max 0;
BA_ "GenSigTimeoutTime_IDCM" SG_ 266 HVBatCellVoltage_Max 0;
BA_ "GenSigTimeoutTime_EVCU2" SG_ 266 HVBatCellVoltage_Max 0;
BA_ "GenSigTimeoutTime_BPCM" SG_ 266 HVBatCellVoltage_Max 0;
BA_ "GenSigTimeoutTime_PPIM" SG_ 266 HVBatCellVoltage_Max 0;
BA_ "GenSigTimeoutTime_SGW" SG_ 266 HVBatteryVoltageV 0;
BA_ "GenSigTimeoutTime_IDCM" SG_ 266 HVBatteryVoltageV 0;
BA_ "GenSigTimeoutTime_EVCU2" SG_ 266 HVBatteryVoltageV 0;
BA_ "GenSigTimeoutTime_BPCM" SG_ 266 HVBatteryVoltageV 0;
BA_ "GenSigTimeoutTime_PPIM" SG_ 266 HVBatteryVoltageV 0;
BA_ "GenSigTimeoutTime_SGW" SG_ 266 HVBatteryReady 0;
BA_ "GenSigTimeoutTime_IDCM" SG_ 266 HVBatteryReady 0;
BA_ "GenSigTimeoutTime_EVCU2" SG_ 266 HVBatteryReady 0;
BA_ "GenSigTimeoutTime_BPCM" SG_ 266 HVBatteryReady 0;
BA_ "GenSigTimeoutTime_PPIM" SG_ 266 HVBatteryReady 0;
BA_ "GenSigTimeoutTime_SGW" SG_ 266 HVBatteryCurrentV 0;
BA_ "GenSigTimeoutTime_IDCM" SG_ 266 HVBatteryCurrentV 0;
BA_ "GenSigTimeoutTime_EVCU2" SG_ 266 HVBatteryCurrentV 0;
BA_ "GenSigTimeoutTime_BPCM" SG_ 266 HVBatteryCurrentV 0;
BA_ "GenSigTimeoutTime_PPIM" SG_ 266 HVBatteryCurrentV 0;
BA_ "GenSigTimeoutTime_SGW" SG_ 266 HVBatContactorReq 0;
BA_ "GenSigTimeoutTime_IDCM" SG_ 266 HVBatContactorReq 0;
BA_ "GenSigTimeoutTime_EVCU2" SG_ 266 HVBatContactorReq 0;
BA_ "GenSigTimeoutTime_BPCM" SG_ 266 HVBatContactorReq 0;
BA_ "GenSigTimeoutTime_PPIM" SG_ 266 HVBatContactorReq 0;
BA_ "GenSigTimeoutTime_SGW" SG_ 266 HVBatContactorOpen 0;
BA_ "GenSigTimeoutTime_IDCM" SG_ 266 HVBatContactorOpen 0;
BA_ "GenSigTimeoutTime_EVCU2" SG_ 266 HVBatContactorOpen 0;
BA_ "GenSigTimeoutTime_BPCM" SG_ 266 HVBatContactorOpen 0;
BA_ "GenSigTimeoutTime_PPIM" SG_ 266 HVBatContactorOpen 0;
BA_ "GenSigTimeoutTime_SGW" SG_ 266 HVBatCellVoltage_MinV 0;
BA_ "GenSigTimeoutTime_IDCM" SG_ 266 HVBatCellVoltage_MinV 0;
BA_ "GenSigTimeoutTime_EVCU2" SG_ 266 HVBatCellVoltage_MinV 0;
BA_ "GenSigTimeoutTime_BPCM" SG_ 266 HVBatCellVoltage_MinV 0;
BA_ "GenSigTimeoutTime_PPIM" SG_ 266 HVBatCellVoltage_MinV 0;
BA_ "GenSigTimeoutTime_SGW" SG_ 266 HVBatCellVoltage_MaxV 0;
BA_ "GenSigTimeoutTime_IDCM" SG_ 266 HVBatCellVoltage_MaxV 0;
BA_ "GenSigTimeoutTime_EVCU2" SG_ 266 HVBatCellVoltage_MaxV 0;
BA_ "GenSigTimeoutTime_BPCM" SG_ 266 HVBatCellVoltage_MaxV 0;
BA_ "GenSigTimeoutTime_PPIM" SG_ 266 HVBatCellVoltage_MaxV 0;
BA_ "GenSigTimeoutTime_SGW" SG_ 266 HVBatCellVoltage_AverageV 0;
BA_ "GenSigTimeoutTime_IDCM" SG_ 266 HVBatCellVoltage_AverageV 0;
BA_ "GenSigTimeoutTime_EVCU2" SG_ 266 HVBatCellVoltage_AverageV 0;
BA_ "GenSigTimeoutTime_BPCM" SG_ 266 HVBatCellVoltage_AverageV 0;
BA_ "GenSigTimeoutTime_PPIM" SG_ 266 HVBatCellVoltage_AverageV 0;
BA_ "GenSigTimeoutTime_SGW" SG_ 266 HVBatCellVoltage_Average 0;
BA_ "GenSigTimeoutTime_IDCM" SG_ 266 HVBatCellVoltage_Average 0;
BA_ "GenSigTimeoutTime_EVCU2" SG_ 266 HVBatCellVoltage_Average 0;
BA_ "GenSigTimeoutTime_BPCM" SG_ 266 HVBatCellVoltage_Average 0;
BA_ "GenSigTimeoutTime_PPIM" SG_ 266 HVBatCellVoltage_Average 0;
BA_ "GenSigTimeoutTime_SGW" SG_ 266 HVBatteryVoltage_BSG 0;
BA_ "GenSigTimeoutTime_IDCM" SG_ 266 HVBatteryVoltage_BSG 0;
BA_ "GenSigTimeoutTime_EVCU2" SG_ 266 HVBatteryVoltage_BSG 0;
BA_ "GenSigTimeoutTime_BPCM" SG_ 266 HVBatteryVoltage_BSG 0;
BA_ "GenSigStartValue" SG_ 266 HVBatteryVoltage_BSG 22;
BA_ "GenSigTimeoutTime_PPIM" SG_ 266 HVBatteryVoltage_BSG 0;
BA_ "GenSigTimeoutTime_SGW" SG_ 266 HVBatCellVoltage_NumMin 0;
BA_ "GenSigTimeoutTime_IDCM" SG_ 266 HVBatCellVoltage_NumMin 0;
BA_ "GenSigTimeoutTime_EVCU2" SG_ 266 HVBatCellVoltage_NumMin 0;
BA_ "GenSigTimeoutTime_BPCM" SG_ 266 HVBatCellVoltage_NumMin 0;
BA_ "GenSigTimeoutTime_PPIM" SG_ 266 HVBatCellVoltage_NumMin 0;
BA_ "GenSigTimeoutTime_SGW" SG_ 266 HVBatShutdownReady 0;
BA_ "GenSigTimeoutTime_IDCM" SG_ 266 HVBatShutdownReady 0;
BA_ "GenSigTimeoutTime_EVCU2" SG_ 266 HVBatShutdownReady 0;
BA_ "GenSigTimeoutTime_BPCM" SG_ 266 HVBatShutdownReady 0;
BA_ "GenSigTimeoutTime_PPIM" SG_ 266 HVBatShutdownReady 0;
BA_ "GenSigTimeoutTime_SGW" SG_ 266 HVBatContactorWelded 0;
BA_ "GenSigTimeoutTime_IDCM" SG_ 266 HVBatContactorWelded 0;
BA_ "GenSigTimeoutTime_EVCU2" SG_ 266 HVBatContactorWelded 0;
BA_ "GenSigTimeoutTime_BPCM" SG_ 266 HVBatContactorWelded 0;
BA_ "GenSigTimeoutTime_PPIM" SG_ 266 HVBatContactorWelded 0;
BA_ "GenSigTimeoutTime_SGW" SG_ 1034 HVBatModuleTemp_MinV 0;
BA_ "GenSigTimeoutTime_IDCM" SG_ 1034 HVBatModuleTemp_MinV 0;
BA_ "GenSigTimeoutTime_EVCU2" SG_ 1034 HVBatModuleTemp_MinV 0;
BA_ "GenSigTimeoutTime_BPCM" SG_ 1034 HVBatModuleTemp_MinV 0;
BA_ "GenSigTimeoutTime_PPIM" SG_ 1034 HVBatModuleTemp_MinV 0;
BA_ "GenSigTimeoutTime_IDCM" SG_ 1034 HVBatModuleTemp_Min 0;
BA_ "GenSigTimeoutTime_EVCU2" SG_ 1034 HVBatModuleTemp_Min 0;
BA_ "GenSigTimeoutTime_BPCM" SG_ 1034 HVBatModuleTemp_Min 0;
BA_ "GenSigTimeoutTime_PPIM" SG_ 1034 HVBatModuleTemp_Min 0;
BA_ "GenSigTimeoutTime_SGW" SG_ 1034 HVBatModuleTemp_MaxV 0;
BA_ "GenSigTimeoutTime_IDCM" SG_ 1034 HVBatModuleTemp_MaxV 0;
BA_ "GenSigTimeoutTime_EVCU2" SG_ 1034 HVBatModuleTemp_MaxV 0;
BA_ "GenSigTimeoutTime_BPCM" SG_ 1034 HVBatModuleTemp_MaxV 0;
BA_ "GenSigTimeoutTime_PPIM" SG_ 1034 HVBatModuleTemp_MaxV 0;
BA_ "GenSigTimeoutTime_IDCM" SG_ 1034 HVBatModuleTemp_Max 0;
BA_ "GenSigTimeoutTime_EVCU2" SG_ 1034 HVBatModuleTemp_Max 0;
BA_ "GenSigTimeoutTime_BPCM" SG_ 1034 HVBatModuleTemp_Max 0;
BA_ "GenSigTimeoutTime_PPIM" SG_ 1034 HVBatModuleTemp_Max 0;
BA_ "GenSigTimeoutTime_SGW" SG_ 1034 HVBatSleepTime 0;
BA_ "GenSigTimeoutTime_IDCM" SG_ 1034 HVBatSleepTime 0;
BA_ "GenSigTimeoutTime_BPCM" SG_ 1034 HVBatSleepTime 0;
BA_ "GenSigTimeoutTime_SGW" SG_ 1034 HVBatModuleTemp_AverageV 0;
BA_ "GenSigTimeoutTime_IDCM" SG_ 1034 HVBatModuleTemp_AverageV 0;
BA_ "GenSigTimeoutTime_EVCU2" SG_ 1034 HVBatModuleTemp_AverageV 0;
BA_ "GenSigTimeoutTime_BPCM" SG_ 1034 HVBatModuleTemp_AverageV 0;
BA_ "GenSigTimeoutTime_PPIM" SG_ 1034 HVBatModuleTemp_AverageV 0;
BA_ "GenSigTimeoutTime_SGW" SG_ 1034 HVBatModuleTemp_Average 0;
BA_ "GenSigTimeoutTime_IDCM" SG_ 1034 HVBatModuleTemp_Average 0;
BA_ "GenSigTimeoutTime_EVCU2" SG_ 1034 HVBatModuleTemp_Average 0;
BA_ "GenSigTimeoutTime_BPCM" SG_ 1034 HVBatModuleTemp_Average 0;
BA_ "GenSigTimeoutTime_PPIM" SG_ 1034 HVBatModuleTemp_Average 0;
BA_ "GenSigTimeoutTime_SGW" SG_ 1034 HVBatLowTempThreshold 0;
BA_ "GenSigTimeoutTime_IDCM" SG_ 1034 HVBatLowTempThreshold 0;
BA_ "GenSigTimeoutTime_EVCU2" SG_ 1034 HVBatLowTempThreshold 0;
BA_ "GenSigTimeoutTime_BPCM" SG_ 1034 HVBatLowTempThreshold 0;
BA_ "GenSigStartValue" SG_ 1034 HVBatLowTempThreshold 20;
BA_ "GenSigTimeoutTime_PPIM" SG_ 1034 HVBatLowTempThreshold 0;
BA_ "GenSigTimeoutTime_SGW" SG_ 1034 HVBatHighTempThreshold 0;
BA_ "GenSigTimeoutTime_IDCM" SG_ 1034 HVBatHighTempThreshold 0;
BA_ "GenSigTimeoutTime_EVCU2" SG_ 1034 HVBatHighTempThreshold 0;
BA_ "GenSigTimeoutTime_BPCM" SG_ 1034 HVBatHighTempThreshold 0;
BA_ "GenSigStartValue" SG_ 1034 HVBatHighTempThreshold 20;
BA_ "GenSigTimeoutTime_PPIM" SG_ 1034 HVBatHighTempThreshold 0;
BA_ "GenSigTimeoutTime_IDCM" SG_ 1034 HVBatModuleTemp_NumMin 0;
BA_ "GenSigTimeoutTime_EVCU2" SG_ 1034 HVBatModuleTemp_NumMin 0;
BA_ "GenSigTimeoutTime_BPCM" SG_ 1034 HVBatModuleTemp_NumMin 0;
BA_ "GenSigTimeoutTime_PPIM" SG_ 1034 HVBatModuleTemp_NumMin 0;
BA_ "GenSigTimeoutTime_HCP" SG_ 1034 HVBatModuleTemp_NumMin 0;
BA_ "GenSigTimeoutTime_IDCM" SG_ 1034 HVBatModuleTemp_NumMax 0;
BA_ "GenSigTimeoutTime_EVCU2" SG_ 1034 HVBatModuleTemp_NumMax 0;
BA_ "GenSigTimeoutTime_BPCM" SG_ 1034 HVBatModuleTemp_NumMax 0;
BA_ "GenSigTimeoutTime_PPIM" SG_ 1034 HVBatModuleTemp_NumMax 0;
BA_ "GenSigTimeoutTime_HCP" SG_ 1034 HVBatModuleTemp_NumMax 0;
BA_ "GenSigTimeoutTime_BPCM" SG_ 1839 HVBatModuleTemp_16 0;
BA_ "GenSigTimeoutTime_IDCM" SG_ 1839 HVBatModuleTemp_16 0;
BA_ "GenSigTimeoutTime_EVCU2" SG_ 1839 HVBatModuleTemp_16 0;
BA_ "GenSigTimeoutTime_IDCM" SG_ 1839 HVBatModuleTemp_15 0;
BA_ "GenSigTimeoutTime_EVCU2" SG_ 1839 HVBatModuleTemp_15 0;
BA_ "GenSigTimeoutTime_BPCM" SG_ 1839 HVBatModuleTemp_15 0;
BA_ "GenSigTimeoutTime_IDCM" SG_ 1839 HVBatModuleTemp_14 0;
BA_ "GenSigTimeoutTime_EVCU2" SG_ 1839 HVBatModuleTemp_14 0;
BA_ "GenSigTimeoutTime_BPCM" SG_ 1839 HVBatModuleTemp_14 0;
BA_ "GenSigTimeoutTime_IDCM" SG_ 1839 HVBatModuleTemp_13 0;
BA_ "GenSigTimeoutTime_EVCU2" SG_ 1839 HVBatModuleTemp_13 0;
BA_ "GenSigTimeoutTime_BPCM" SG_ 1839 HVBatModuleTemp_13 0;
BA_ "GenSigTimeoutTime_IDCM" SG_ 1839 HVBatModuleTemp_12 0;
BA_ "GenSigTimeoutTime_EVCU2" SG_ 1839 HVBatModuleTemp_12 0;
BA_ "GenSigTimeoutTime_BPCM" SG_ 1839 HVBatModuleTemp_12 0;
BA_ "GenSigTimeoutTime_IDCM" SG_ 1839 HVBatModuleTemp_11 0;
BA_ "GenSigTimeoutTime_EVCU2" SG_ 1839 HVBatModuleTemp_11 0;
BA_ "GenSigTimeoutTime_BPCM" SG_ 1839 HVBatModuleTemp_11 0;
BA_ "GenSigTimeoutTime_IDCM" SG_ 1839 HVBatModuleTemp_10 0;
BA_ "GenSigTimeoutTime_EVCU2" SG_ 1839 HVBatModuleTemp_10 0;
BA_ "GenSigTimeoutTime_BPCM" SG_ 1839 HVBatModuleTemp_10 0;
BA_ "GenSigTimeoutTime_IDCM" SG_ 1839 HVBatModuleTemp_09 0;
BA_ "GenSigTimeoutTime_EVCU2" SG_ 1839 HVBatModuleTemp_09 0;
BA_ "GenSigTimeoutTime_BPCM" SG_ 1839 HVBatModuleTemp_09 0;
BA_ "GenSigTimeoutTime_IDCM" SG_ 1839 HVBatModuleTemp_08 0;
BA_ "GenSigTimeoutTime_EVCU2" SG_ 1839 HVBatModuleTemp_08 0;
BA_ "GenSigTimeoutTime_BPCM" SG_ 1839 HVBatModuleTemp_08 0;
BA_ "GenSigTimeoutTime_IDCM" SG_ 1839 HVBatModuleTemp_07 0;
BA_ "GenSigTimeoutTime_EVCU2" SG_ 1839 HVBatModuleTemp_07 0;
BA_ "GenSigTimeoutTime_BPCM" SG_ 1839 HVBatModuleTemp_07 0;
BA_ "GenSigTimeoutTime_IDCM" SG_ 1839 HVBatModuleTemp_06 0;
BA_ "GenSigTimeoutTime_EVCU2" SG_ 1839 HVBatModuleTemp_06 0;
BA_ "GenSigTimeoutTime_BPCM" SG_ 1839 HVBatModuleTemp_06 0;
BA_ "GenSigTimeoutTime_IDCM" SG_ 1839 HVBatModuleTemp_05 0;
BA_ "GenSigTimeoutTime_EVCU2" SG_ 1839 HVBatModuleTemp_05 0;
BA_ "GenSigTimeoutTime_BPCM" SG_ 1839 HVBatModuleTemp_05 0;
BA_ "GenSigTimeoutTime_IDCM" SG_ 1839 HVBatModuleTemp_04 0;
BA_ "GenSigTimeoutTime_EVCU2" SG_ 1839 HVBatModuleTemp_04 0;
BA_ "GenSigTimeoutTime_BPCM" SG_ 1839 HVBatModuleTemp_04 0;
BA_ "GenSigTimeoutTime_IDCM" SG_ 1839 HVBatModuleTemp_03 0;
BA_ "GenSigTimeoutTime_EVCU2" SG_ 1839 HVBatModuleTemp_03 0;
BA_ "GenSigTimeoutTime_BPCM" SG_ 1839 HVBatModuleTemp_03 0;
BA_ "GenSigTimeoutTime_IDCM" SG_ 1839 HVBatModuleTemp_02 0;
BA_ "GenSigTimeoutTime_EVCU2" SG_ 1839 HVBatModuleTemp_02 0;
BA_ "GenSigTimeoutTime_BPCM" SG_ 1839 HVBatModuleTemp_02 0;
BA_ "GenSigTimeoutTime_IDCM" SG_ 1839 HVBatModuleTemp_01 0;
BA_ "GenSigTimeoutTime_EVCU2" SG_ 1839 HVBatModuleTemp_01 0;
BA_ "GenSigTimeoutTime_BPCM" SG_ 1839 HVBatModuleTemp_01 0;
BA_ "GenSigTimeoutTime_SGW" SG_ 1839 HVBatModuleTemp_38 0;
BA_ "GenSigTimeoutTime_IDCM" SG_ 1839 HVBatModuleTemp_38 0;
BA_ "GenSigTimeoutTime_EVCU2" SG_ 1839 HVBatModuleTemp_38 0;
BA_ "GenSigTimeoutTime_BPCM" SG_ 1839 HVBatModuleTemp_38 0;
BA_ "GenSigTimeoutTime_SGW" SG_ 1839 HVBatModuleTemp_37 0;
BA_ "GenSigTimeoutTime_IDCM" SG_ 1839 HVBatModuleTemp_37 0;
BA_ "GenSigTimeoutTime_EVCU2" SG_ 1839 HVBatModuleTemp_37 0;
BA_ "GenSigTimeoutTime_BPCM" SG_ 1839 HVBatModuleTemp_37 0;
BA_ "GenSigTimeoutTime_SGW" SG_ 1839 HVBatModuleTemp_36 0;
BA_ "GenSigTimeoutTime_IDCM" SG_ 1839 HVBatModuleTemp_36 0;
BA_ "GenSigTimeoutTime_EVCU2" SG_ 1839 HVBatModuleTemp_36 0;
BA_ "GenSigTimeoutTime_BPCM" SG_ 1839 HVBatModuleTemp_36 0;
BA_ "GenSigTimeoutTime_SGW" SG_ 1839 HVBatModuleTemp_35 0;
BA_ "GenSigTimeoutTime_IDCM" SG_ 1839 HVBatModuleTemp_35 0;
BA_ "GenSigTimeoutTime_EVCU2" SG_ 1839 HVBatModuleTemp_35 0;
BA_ "GenSigTimeoutTime_BPCM" SG_ 1839 HVBatModuleTemp_35 0;
BA_ "GenSigTimeoutTime_SGW" SG_ 1839 HVBatModuleTemp_34 0;
BA_ "GenSigTimeoutTime_IDCM" SG_ 1839 HVBatModuleTemp_34 0;
BA_ "GenSigTimeoutTime_EVCU2" SG_ 1839 HVBatModuleTemp_34 0;
BA_ "GenSigTimeoutTime_BPCM" SG_ 1839 HVBatModuleTemp_34 0;
BA_ "GenSigTimeoutTime_SGW" SG_ 1839 HVBatModuleTemp_33 0;
BA_ "GenSigTimeoutTime_IDCM" SG_ 1839 HVBatModuleTemp_33 0;
BA_ "GenSigTimeoutTime_EVCU2" SG_ 1839 HVBatModuleTemp_33 0;
BA_ "GenSigTimeoutTime_BPCM" SG_ 1839 HVBatModuleTemp_33 0;
BA_ "GenSigTimeoutTime_SGW" SG_ 1839 HVBatModuleTemp_32 0;
BA_ "GenSigTimeoutTime_IDCM" SG_ 1839 HVBatModuleTemp_32 0;
BA_ "GenSigTimeoutTime_EVCU2" SG_ 1839 HVBatModuleTemp_32 0;
BA_ "GenSigTimeoutTime_BPCM" SG_ 1839 HVBatModuleTemp_32 0;
BA_ "GenSigTimeoutTime_SGW" SG_ 1839 HVBatModuleTemp_31 0;
BA_ "GenSigTimeoutTime_IDCM" SG_ 1839 HVBatModuleTemp_31 0;
BA_ "GenSigTimeoutTime_EVCU2" SG_ 1839 HVBatModuleTemp_31 0;
BA_ "GenSigTimeoutTime_BPCM" SG_ 1839 HVBatModuleTemp_31 0;
BA_ "GenSigTimeoutTime_SGW" SG_ 1839 HVBatModuleTemp_30 0;
BA_ "GenSigTimeoutTime_IDCM" SG_ 1839 HVBatModuleTemp_30 0;
BA_ "GenSigTimeoutTime_EVCU2" SG_ 1839 HVBatModuleTemp_30 0;
BA_ "GenSigTimeoutTime_BPCM" SG_ 1839 HVBatModuleTemp_30 0;
BA_ "GenSigTimeoutTime_SGW" SG_ 1839 HVBatModuleTemp_29 0;
BA_ "GenSigTimeoutTime_IDCM" SG_ 1839 HVBatModuleTemp_29 0;
BA_ "GenSigTimeoutTime_EVCU2" SG_ 1839 HVBatModuleTemp_29 0;
BA_ "GenSigTimeoutTime_BPCM" SG_ 1839 HVBatModuleTemp_29 0;
BA_ "GenSigTimeoutTime_SGW" SG_ 1839 HVBatModuleTemp_28 0;
BA_ "GenSigTimeoutTime_IDCM" SG_ 1839 HVBatModuleTemp_28 0;
BA_ "GenSigTimeoutTime_EVCU2" SG_ 1839 HVBatModuleTemp_28 0;
BA_ "GenSigTimeoutTime_BPCM" SG_ 1839 HVBatModuleTemp_28 0;
BA_ "GenSigTimeoutTime_SGW" SG_ 1839 HVBatModuleTemp_27 0;
BA_ "GenSigTimeoutTime_IDCM" SG_ 1839 HVBatModuleTemp_27 0;
BA_ "GenSigTimeoutTime_EVCU2" SG_ 1839 HVBatModuleTemp_27 0;
BA_ "GenSigTimeoutTime_BPCM" SG_ 1839 HVBatModuleTemp_27 0;
BA_ "GenSigTimeoutTime_SGW" SG_ 1839 HVBatModuleTemp_26 0;
BA_ "GenSigTimeoutTime_IDCM" SG_ 1839 HVBatModuleTemp_26 0;
BA_ "GenSigTimeoutTime_EVCU2" SG_ 1839 HVBatModuleTemp_26 0;
BA_ "GenSigTimeoutTime_BPCM" SG_ 1839 HVBatModuleTemp_26 0;
BA_ "GenSigTimeoutTime_SGW" SG_ 1839 HVBatModuleTemp_25 0;
BA_ "GenSigTimeoutTime_IDCM" SG_ 1839 HVBatModuleTemp_25 0;
BA_ "GenSigTimeoutTime_EVCU2" SG_ 1839 HVBatModuleTemp_25 0;
BA_ "GenSigTimeoutTime_BPCM" SG_ 1839 HVBatModuleTemp_25 0;
BA_ "GenSigTimeoutTime_SGW" SG_ 1839 HVBatModuleTemp_24 0;
BA_ "GenSigTimeoutTime_IDCM" SG_ 1839 HVBatModuleTemp_24 0;
BA_ "GenSigTimeoutTime_EVCU2" SG_ 1839 HVBatModuleTemp_24 0;
BA_ "GenSigTimeoutTime_BPCM" SG_ 1839 HVBatModuleTemp_24 0;
BA_ "GenSigTimeoutTime_SGW" SG_ 1839 HVBatModuleTemp_23 0;
BA_ "GenSigTimeoutTime_IDCM" SG_ 1839 HVBatModuleTemp_23 0;
BA_ "GenSigTimeoutTime_EVCU2" SG_ 1839 HVBatModuleTemp_23 0;
BA_ "GenSigTimeoutTime_BPCM" SG_ 1839 HVBatModuleTemp_23 0;
BA_ "GenSigTimeoutTime_SGW" SG_ 1839 HVBatModuleTemp_22 0;
BA_ "GenSigTimeoutTime_IDCM" SG_ 1839 HVBatModuleTemp_22 0;
BA_ "GenSigTimeoutTime_EVCU2" SG_ 1839 HVBatModuleTemp_22 0;
BA_ "GenSigTimeoutTime_BPCM" SG_ 1839 HVBatModuleTemp_22 0;
BA_ "GenSigTimeoutTime_SGW" SG_ 1839 HVBatModuleTemp_21 0;
BA_ "GenSigTimeoutTime_IDCM" SG_ 1839 HVBatModuleTemp_21 0;
BA_ "GenSigTimeoutTime_EVCU2" SG_ 1839 HVBatModuleTemp_21 0;
BA_ "GenSigTimeoutTime_BPCM" SG_ 1839 HVBatModuleTemp_21 0;
BA_ "GenSigTimeoutTime_SGW" SG_ 1839 HVBatModuleTemp_20 0;
BA_ "GenSigTimeoutTime_IDCM" SG_ 1839 HVBatModuleTemp_20 0;
BA_ "GenSigTimeoutTime_EVCU2" SG_ 1839 HVBatModuleTemp_20 0;
BA_ "GenSigTimeoutTime_BPCM" SG_ 1839 HVBatModuleTemp_20 0;
BA_ "GenSigTimeoutTime_SGW" SG_ 1839 HVBatModuleTemp_19 0;
BA_ "GenSigTimeoutTime_IDCM" SG_ 1839 HVBatModuleTemp_19 0;
BA_ "GenSigTimeoutTime_EVCU2" SG_ 1839 HVBatModuleTemp_19 0;
BA_ "GenSigTimeoutTime_BPCM" SG_ 1839 HVBatModuleTemp_19 0;
BA_ "GenSigTimeoutTime_SGW" SG_ 1839 HVBatModuleTemp_18 0;
BA_ "GenSigTimeoutTime_IDCM" SG_ 1839 HVBatModuleTemp_18 0;
BA_ "GenSigTimeoutTime_EVCU2" SG_ 1839 HVBatModuleTemp_18 0;
BA_ "GenSigTimeoutTime_BPCM" SG_ 1839 HVBatModuleTemp_18 0;
BA_ "GenSigTimeoutTime_SGW" SG_ 1839 HVBatModuleTemp_17 0;
BA_ "GenSigTimeoutTime_IDCM" SG_ 1839 HVBatModuleTemp_17 0;
BA_ "GenSigTimeoutTime_EVCU2" SG_ 1839 HVBatModuleTemp_17 0;
BA_ "GenSigTimeoutTime_BPCM" SG_ 1839 HVBatModuleTemp_17 0;
BA_ "GenSigTimeoutTime_IDCM" SG_ 1840 IsolationResistance 0;
BA_ "GenSigTimeoutTime_EVCU2" SG_ 1840 IsolationResistance 0;
BA_ "GenSigTimeoutTime_BPCM" SG_ 1840 IsolationResistance 0;
BA_ "GenSigTimeoutTime_PPIM" SG_ 1840 IsolationResistance 0;
BA_ "GenSigTimeoutTime_HCP" SG_ 1840 IsolationResistance 0;
BA_ "GenSigTimeoutTime_IDCM" SG_ 1840 Warning_SOCJump 0;
BA_ "GenSigTimeoutTime_EVCU2" SG_ 1840 Warning_SOCJump 0;
BA_ "GenSigTimeoutTime_BPCM" SG_ 1840 Warning_SOCJump 0;
BA_ "GenSigTimeoutTime_PPIM" SG_ 1840 Warning_SOCJump 0;
BA_ "GenSigTimeoutTime_HCP" SG_ 1840 Warning_SOCJump 0;
BA_ "GenSigTimeoutTime_IDCM" SG_ 1840 Warning_PackUnmatched 0;
BA_ "GenSigTimeoutTime_EVCU2" SG_ 1840 Warning_PackUnmatched 0;
BA_ "GenSigTimeoutTime_BPCM" SG_ 1840 Warning_PackUnmatched 0;
BA_ "GenSigTimeoutTime_PPIM" SG_ 1840 Warning_PackUnmatched 0;
BA_ "GenSigTimeoutTime_HCP" SG_ 1840 Warning_PackUnmatched 0;
BA_ "GenSigTimeoutTime_IDCM" SG_ 1840 Warning_PackUndervoltage 0;
BA_ "GenSigTimeoutTime_EVCU2" SG_ 1840 Warning_PackUndervoltage 0;
BA_ "GenSigTimeoutTime_BPCM" SG_ 1840 Warning_PackUndervoltage 0;
BA_ "GenSigTimeoutTime_PPIM" SG_ 1840 Warning_PackUndervoltage 0;
BA_ "GenSigTimeoutTime_HCP" SG_ 1840 Warning_PackUndervoltage 0;
BA_ "GenSigTimeoutTime_IDCM" SG_ 1840 Warning_PackTempHigh 0;
BA_ "GenSigTimeoutTime_EVCU2" SG_ 1840 Warning_PackTempHigh 0;
BA_ "GenSigTimeoutTime_BPCM" SG_ 1840 Warning_PackTempHigh 0;
BA_ "GenSigTimeoutTime_PPIM" SG_ 1840 Warning_PackTempHigh 0;
BA_ "GenSigTimeoutTime_HCP" SG_ 1840 Warning_PackTempHigh 0;
BA_ "GenSigTimeoutTime_IDCM" SG_ 1840 Warning_PackTempDiff 0;
BA_ "GenSigTimeoutTime_EVCU2" SG_ 1840 Warning_PackTempDiff 0;
BA_ "GenSigTimeoutTime_BPCM" SG_ 1840 Warning_PackTempDiff 0;
BA_ "GenSigTimeoutTime_PPIM" SG_ 1840 Warning_PackTempDiff 0;
BA_ "GenSigTimeoutTime_HCP" SG_ 1840 Warning_PackTempDiff 0;
BA_ "GenSigTimeoutTime_IDCM" SG_ 1840 Warning_PackOvervoltage 0;
BA_ "GenSigTimeoutTime_EVCU2" SG_ 1840 Warning_PackOvervoltage 0;
BA_ "GenSigTimeoutTime_BPCM" SG_ 1840 Warning_PackOvervoltage 0;
BA_ "GenSigTimeoutTime_PPIM" SG_ 1840 Warning_PackOvervoltage 0;
BA_ "GenSigTimeoutTime_HCP" SG_ 1840 Warning_PackOvervoltage 0;
BA_ "GenSigTimeoutTime_IDCM" SG_ 1840 Warning_Overcharging 0;
BA_ "GenSigTimeoutTime_EVCU2" SG_ 1840 Warning_Overcharging 0;
BA_ "GenSigTimeoutTime_BPCM" SG_ 1840 Warning_Overcharging 0;
BA_ "GenSigTimeoutTime_PPIM" SG_ 1840 Warning_Overcharging 0;
BA_ "GenSigTimeoutTime_HCP" SG_ 1840 Warning_Overcharging 0;
BA_ "GenSigTimeoutTime_IDCM" SG_ 1840 Warning_LowSOC 0;
BA_ "GenSigTimeoutTime_EVCU2" SG_ 1840 Warning_LowSOC 0;
BA_ "GenSigTimeoutTime_BPCM" SG_ 1840 Warning_LowSOC 0;
BA_ "GenSigTimeoutTime_PPIM" SG_ 1840 Warning_LowSOC 0;
BA_ "GenSigTimeoutTime_HCP" SG_ 1840 Warning_LowSOC 0;
BA_ "GenSigTimeoutTime_IDCM" SG_ 1840 Warning_Insulation 0;
BA_ "GenSigTimeoutTime_EVCU2" SG_ 1840 Warning_Insulation 0;
BA_ "GenSigTimeoutTime_BPCM" SG_ 1840 Warning_Insulation 0;
BA_ "GenSigTimeoutTime_PPIM" SG_ 1840 Warning_Insulation 0;
BA_ "GenSigTimeoutTime_HCP" SG_ 1840 Warning_Insulation 0;
BA_ "GenSigTimeoutTime_IDCM" SG_ 1840 Warning_HVIL 0;
BA_ "GenSigTimeoutTime_EVCU2" SG_ 1840 Warning_HVIL 0;
BA_ "GenSigTimeoutTime_BPCM" SG_ 1840 Warning_HVIL 0;
BA_ "GenSigTimeoutTime_PPIM" SG_ 1840 Warning_HVIL 0;
BA_ "GenSigTimeoutTime_HCP" SG_ 1840 Warning_HVIL 0;
BA_ "GenSigTimeoutTime_IDCM" SG_ 1840 Warning_HighSOC 0;
BA_ "GenSigTimeoutTime_EVCU2" SG_ 1840 Warning_HighSOC 0;
BA_ "GenSigTimeoutTime_BPCM" SG_ 1840 Warning_HighSOC 0;
BA_ "GenSigTimeoutTime_PPIM" SG_ 1840 Warning_HighSOC 0;
BA_ "GenSigTimeoutTime_HCP" SG_ 1840 Warning_HighSOC 0;
BA_ "GenSigTimeoutTime_IDCM" SG_ 1840 Warning_CellUndervoltage 0;
BA_ "GenSigTimeoutTime_EVCU2" SG_ 1840 Warning_CellUndervoltage 0;
BA_ "GenSigTimeoutTime_BPCM" SG_ 1840 Warning_CellUndervoltage 0;
BA_ "GenSigTimeoutTime_PPIM" SG_ 1840 Warning_CellUndervoltage 0;
BA_ "GenSigTimeoutTime_HCP" SG_ 1840 Warning_CellUndervoltage 0;
BA_ "GenSigTimeoutTime_IDCM" SG_ 1840 Warning_CellOvervoltage 0;
BA_ "GenSigTimeoutTime_EVCU2" SG_ 1840 Warning_CellOvervoltage 0;
BA_ "GenSigTimeoutTime_BPCM" SG_ 1840 Warning_CellOvervoltage 0;
BA_ "GenSigTimeoutTime_PPIM" SG_ 1840 Warning_CellOvervoltage 0;
BA_ "GenSigTimeoutTime_HCP" SG_ 1840 Warning_CellOvervoltage 0;
BA_ "GenSigTimeoutTime_IDCM" SG_ 1840 Warning_CellBalance 0;
BA_ "GenSigTimeoutTime_EVCU2" SG_ 1840 Warning_CellBalance 0;
BA_ "GenSigTimeoutTime_BPCM" SG_ 1840 Warning_CellBalance 0;
BA_ "GenSigTimeoutTime_PPIM" SG_ 1840 Warning_CellBalance 0;
BA_ "GenSigTimeoutTime_HCP" SG_ 1840 Warning_CellBalance 0;
BA_ "GenSigTimeoutTime_IDCM" SG_ 1840 HighestWarningLevel 0;
BA_ "GenSigTimeoutTime_EVCU2" SG_ 1840 HighestWarningLevel 0;
BA_ "GenSigTimeoutTime_BPCM" SG_ 1840 HighestWarningLevel 0;
BA_ "GenSigTimeoutTime_PPIM" SG_ 1840 HighestWarningLevel 0;
BA_ "GenSigTimeoutTime_HCP" SG_ 1840 HighestWarningLevel 0;
BA_ "GenSigTimeoutTime_IDCM" SG_ 1838 HVBatCellVoltage_Cell096 0;
BA_ "GenSigTimeoutTime_EVCU2" SG_ 1838 HVBatCellVoltage_Cell096 0;
BA_ "GenSigTimeoutTime_BPCM" SG_ 1838 HVBatCellVoltage_Cell096 0;
BA_ "GenSigTimeoutTime_IDCM" SG_ 1838 HVBatCellVoltage_Cell095 0;
BA_ "GenSigTimeoutTime_EVCU2" SG_ 1838 HVBatCellVoltage_Cell095 0;
BA_ "GenSigTimeoutTime_BPCM" SG_ 1838 HVBatCellVoltage_Cell095 0;
BA_ "GenSigTimeoutTime_IDCM" SG_ 1838 HVBatCellVoltage_Cell094 0;
BA_ "GenSigTimeoutTime_EVCU2" SG_ 1838 HVBatCellVoltage_Cell094 0;
BA_ "GenSigTimeoutTime_BPCM" SG_ 1838 HVBatCellVoltage_Cell094 0;
BA_ "GenSigTimeoutTime_IDCM" SG_ 1838 HVBatCellVoltage_Cell093 0;
BA_ "GenSigTimeoutTime_EVCU2" SG_ 1838 HVBatCellVoltage_Cell093 0;
BA_ "GenSigTimeoutTime_BPCM" SG_ 1838 HVBatCellVoltage_Cell093 0;
BA_ "GenSigTimeoutTime_IDCM" SG_ 1838 HVBatCellVoltage_Cell092 0;
BA_ "GenSigTimeoutTime_EVCU2" SG_ 1838 HVBatCellVoltage_Cell092 0;
BA_ "GenSigTimeoutTime_BPCM" SG_ 1838 HVBatCellVoltage_Cell092 0;
BA_ "GenSigTimeoutTime_IDCM" SG_ 1838 HVBatCellVoltage_Cell091 0;
BA_ "GenSigTimeoutTime_EVCU2" SG_ 1838 HVBatCellVoltage_Cell091 0;
BA_ "GenSigTimeoutTime_BPCM" SG_ 1838 HVBatCellVoltage_Cell091 0;
BA_ "GenSigTimeoutTime_IDCM" SG_ 1838 HVBatCellVoltage_Cell090 0;
BA_ "GenSigTimeoutTime_EVCU2" SG_ 1838 HVBatCellVoltage_Cell090 0;
BA_ "GenSigTimeoutTime_BPCM" SG_ 1838 HVBatCellVoltage_Cell090 0;
BA_ "GenSigTimeoutTime_IDCM" SG_ 1838 HVBatCellVoltage_Cell089 0;
BA_ "GenSigTimeoutTime_EVCU2" SG_ 1838 HVBatCellVoltage_Cell089 0;
BA_ "GenSigTimeoutTime_BPCM" SG_ 1838 HVBatCellVoltage_Cell089 0;
BA_ "GenSigTimeoutTime_IDCM" SG_ 1838 HVBatCellVoltage_Cell088 0;
BA_ "GenSigTimeoutTime_EVCU2" SG_ 1838 HVBatCellVoltage_Cell088 0;
BA_ "GenSigTimeoutTime_BPCM" SG_ 1838 HVBatCellVoltage_Cell088 0;
BA_ "GenSigTimeoutTime_IDCM" SG_ 1838 HVBatCellVoltage_Cell087 0;
BA_ "GenSigTimeoutTime_EVCU2" SG_ 1838 HVBatCellVoltage_Cell087 0;
BA_ "GenSigTimeoutTime_BPCM" SG_ 1838 HVBatCellVoltage_Cell087 0;
BA_ "GenSigTimeoutTime_IDCM" SG_ 1838 HVBatCellVoltage_Cell086 0;
BA_ "GenSigTimeoutTime_EVCU2" SG_ 1838 HVBatCellVoltage_Cell086 0;
BA_ "GenSigTimeoutTime_BPCM" SG_ 1838 HVBatCellVoltage_Cell086 0;
BA_ "GenSigTimeoutTime_IDCM" SG_ 1838 HVBatCellVoltage_Cell085 0;
BA_ "GenSigTimeoutTime_EVCU2" SG_ 1838 HVBatCellVoltage_Cell085 0;
BA_ "GenSigTimeoutTime_BPCM" SG_ 1838 HVBatCellVoltage_Cell085 0;
BA_ "GenSigTimeoutTime_IDCM" SG_ 1838 HVBatCellVoltage_Cell084 0;
BA_ "GenSigTimeoutTime_EVCU2" SG_ 1838 HVBatCellVoltage_Cell084 0;
BA_ "GenSigTimeoutTime_BPCM" SG_ 1838 HVBatCellVoltage_Cell084 0;
BA_ "GenSigTimeoutTime_IDCM" SG_ 1838 HVBatCellVoltage_Cell083 0;
BA_ "GenSigTimeoutTime_EVCU2" SG_ 1838 HVBatCellVoltage_Cell083 0;
BA_ "GenSigTimeoutTime_BPCM" SG_ 1838 HVBatCellVoltage_Cell083 0;
BA_ "GenSigTimeoutTime_IDCM" SG_ 1838 HVBatCellVoltage_Cell082 0;
BA_ "GenSigTimeoutTime_EVCU2" SG_ 1838 HVBatCellVoltage_Cell082 0;
BA_ "GenSigTimeoutTime_BPCM" SG_ 1838 HVBatCellVoltage_Cell082 0;
BA_ "GenSigTimeoutTime_IDCM" SG_ 1838 HVBatCellVoltage_Cell108 0;
BA_ "GenSigTimeoutTime_EVCU2" SG_ 1838 HVBatCellVoltage_Cell108 0;
BA_ "GenSigTimeoutTime_BPCM" SG_ 1838 HVBatCellVoltage_Cell108 0;
BA_ "GenSigTimeoutTime_IDCM" SG_ 1838 HVBatCellVoltage_Cell107 0;
BA_ "GenSigTimeoutTime_EVCU2" SG_ 1838 HVBatCellVoltage_Cell107 0;
BA_ "GenSigTimeoutTime_BPCM" SG_ 1838 HVBatCellVoltage_Cell107 0;
BA_ "GenSigTimeoutTime_IDCM" SG_ 1838 HVBatCellVoltage_Cell106 0;
BA_ "GenSigTimeoutTime_EVCU2" SG_ 1838 HVBatCellVoltage_Cell106 0;
BA_ "GenSigTimeoutTime_BPCM" SG_ 1838 HVBatCellVoltage_Cell106 0;
BA_ "GenSigTimeoutTime_IDCM" SG_ 1838 HVBatCellVoltage_Cell105 0;
BA_ "GenSigTimeoutTime_EVCU2" SG_ 1838 HVBatCellVoltage_Cell105 0;
BA_ "GenSigTimeoutTime_BPCM" SG_ 1838 HVBatCellVoltage_Cell105 0;
BA_ "GenSigTimeoutTime_IDCM" SG_ 1838 HVBatCellVoltage_Cell104 0;
BA_ "GenSigTimeoutTime_EVCU2" SG_ 1838 HVBatCellVoltage_Cell104 0;
BA_ "GenSigTimeoutTime_BPCM" SG_ 1838 HVBatCellVoltage_Cell104 0;
BA_ "GenSigTimeoutTime_IDCM" SG_ 1838 HVBatCellVoltage_Cell103 0;
BA_ "GenSigTimeoutTime_EVCU2" SG_ 1838 HVBatCellVoltage_Cell103 0;
BA_ "GenSigTimeoutTime_BPCM" SG_ 1838 HVBatCellVoltage_Cell103 0;
BA_ "GenSigTimeoutTime_BPCM" SG_ 1838 HVBatCellVoltage_Cell102 0;
BA_ "GenSigTimeoutTime_IDCM" SG_ 1838 HVBatCellVoltage_Cell102 0;
BA_ "GenSigTimeoutTime_EVCU2" SG_ 1838 HVBatCellVoltage_Cell102 0;
BA_ "GenSigTimeoutTime_IDCM" SG_ 1838 HVBatCellVoltage_Cell101 0;
BA_ "GenSigTimeoutTime_EVCU2" SG_ 1838 HVBatCellVoltage_Cell101 0;
BA_ "GenSigTimeoutTime_BPCM" SG_ 1838 HVBatCellVoltage_Cell101 0;
BA_ "GenSigTimeoutTime_IDCM" SG_ 1838 HVBatCellVoltage_Cell100 0;
BA_ "GenSigTimeoutTime_EVCU2" SG_ 1838 HVBatCellVoltage_Cell100 0;
BA_ "GenSigTimeoutTime_BPCM" SG_ 1838 HVBatCellVoltage_Cell100 0;
BA_ "GenSigTimeoutTime_IDCM" SG_ 1838 HVBatCellVoltage_Cell099 0;
BA_ "GenSigTimeoutTime_EVCU2" SG_ 1838 HVBatCellVoltage_Cell099 0;
BA_ "GenSigTimeoutTime_BPCM" SG_ 1838 HVBatCellVoltage_Cell099 0;
BA_ "GenSigTimeoutTime_IDCM" SG_ 1838 HVBatCellVoltage_Cell098 0;
BA_ "GenSigTimeoutTime_EVCU2" SG_ 1838 HVBatCellVoltage_Cell098 0;
BA_ "GenSigTimeoutTime_BPCM" SG_ 1838 HVBatCellVoltage_Cell098 0;
BA_ "GenSigTimeoutTime_IDCM" SG_ 1838 HVBatCellVoltage_Cell097 0;
BA_ "GenSigTimeoutTime_EVCU2" SG_ 1838 HVBatCellVoltage_Cell097 0;
BA_ "GenSigTimeoutTime_BPCM" SG_ 1838 HVBatCellVoltage_Cell097 0;
BA_ "GenSigTimeoutTime_IDCM" SG_ 1837 HVBatCellVoltage_Cell081 0;
BA_ "GenSigTimeoutTime_EVCU2" SG_ 1837 HVBatCellVoltage_Cell081 0;
BA_ "GenSigTimeoutTime_BPCM" SG_ 1837 HVBatCellVoltage_Cell081 0;
BA_ "GenSigTimeoutTime_IDCM" SG_ 1837 HVBatCellVoltage_Cell080 0;
BA_ "GenSigTimeoutTime_EVCU2" SG_ 1837 HVBatCellVoltage_Cell080 0;
BA_ "GenSigTimeoutTime_BPCM" SG_ 1837 HVBatCellVoltage_Cell080 0;
BA_ "GenSigTimeoutTime_IDCM" SG_ 1837 HVBatCellVoltage_Cell079 0;
BA_ "GenSigTimeoutTime_EVCU2" SG_ 1837 HVBatCellVoltage_Cell079 0;
BA_ "GenSigTimeoutTime_BPCM" SG_ 1837 HVBatCellVoltage_Cell079 0;
BA_ "GenSigTimeoutTime_IDCM" SG_ 1837 HVBatCellVoltage_Cell078 0;
BA_ "GenSigTimeoutTime_EVCU2" SG_ 1837 HVBatCellVoltage_Cell078 0;
BA_ "GenSigTimeoutTime_BPCM" SG_ 1837 HVBatCellVoltage_Cell078 0;
BA_ "GenSigTimeoutTime_IDCM" SG_ 1837 HVBatCellVoltage_Cell077 0;
BA_ "GenSigTimeoutTime_EVCU2" SG_ 1837 HVBatCellVoltage_Cell077 0;
BA_ "GenSigTimeoutTime_BPCM" SG_ 1837 HVBatCellVoltage_Cell077 0;
BA_ "GenSigTimeoutTime_IDCM" SG_ 1837 HVBatCellVoltage_Cell076 0;
BA_ "GenSigTimeoutTime_EVCU2" SG_ 1837 HVBatCellVoltage_Cell076 0;
BA_ "GenSigTimeoutTime_BPCM" SG_ 1837 HVBatCellVoltage_Cell076 0;
BA_ "GenSigTimeoutTime_IDCM" SG_ 1837 HVBatCellVoltage_Cell075 0;
BA_ "GenSigTimeoutTime_EVCU2" SG_ 1837 HVBatCellVoltage_Cell075 0;
BA_ "GenSigTimeoutTime_BPCM" SG_ 1837 HVBatCellVoltage_Cell075 0;
BA_ "GenSigTimeoutTime_IDCM" SG_ 1837 HVBatCellVoltage_Cell074 0;
BA_ "GenSigTimeoutTime_EVCU2" SG_ 1837 HVBatCellVoltage_Cell074 0;
BA_ "GenSigTimeoutTime_BPCM" SG_ 1837 HVBatCellVoltage_Cell074 0;
BA_ "GenSigTimeoutTime_IDCM" SG_ 1837 HVBatCellVoltage_Cell073 0;
BA_ "GenSigTimeoutTime_EVCU2" SG_ 1837 HVBatCellVoltage_Cell073 0;
BA_ "GenSigTimeoutTime_BPCM" SG_ 1837 HVBatCellVoltage_Cell073 0;
BA_ "GenSigTimeoutTime_IDCM" SG_ 1837 HVBatCellVoltage_Cell072 0;
BA_ "GenSigTimeoutTime_EVCU2" SG_ 1837 HVBatCellVoltage_Cell072 0;
BA_ "GenSigTimeoutTime_BPCM" SG_ 1837 HVBatCellVoltage_Cell072 0;
BA_ "GenSigTimeoutTime_IDCM" SG_ 1837 HVBatCellVoltage_Cell071 0;
BA_ "GenSigTimeoutTime_EVCU2" SG_ 1837 HVBatCellVoltage_Cell071 0;
BA_ "GenSigTimeoutTime_BPCM" SG_ 1837 HVBatCellVoltage_Cell071 0;
BA_ "GenSigTimeoutTime_IDCM" SG_ 1837 HVBatCellVoltage_Cell070 0;
BA_ "GenSigTimeoutTime_EVCU2" SG_ 1837 HVBatCellVoltage_Cell070 0;
BA_ "GenSigTimeoutTime_BPCM" SG_ 1837 HVBatCellVoltage_Cell070 0;
BA_ "GenSigTimeoutTime_IDCM" SG_ 1837 HVBatCellVoltage_Cell069 0;
BA_ "GenSigTimeoutTime_EVCU2" SG_ 1837 HVBatCellVoltage_Cell069 0;
BA_ "GenSigTimeoutTime_BPCM" SG_ 1837 HVBatCellVoltage_Cell069 0;
BA_ "GenSigTimeoutTime_IDCM" SG_ 1837 HVBatCellVoltage_Cell068 0;
BA_ "GenSigTimeoutTime_EVCU2" SG_ 1837 HVBatCellVoltage_Cell068 0;
BA_ "GenSigTimeoutTime_BPCM" SG_ 1837 HVBatCellVoltage_Cell068 0;
BA_ "GenSigTimeoutTime_IDCM" SG_ 1837 HVBatCellVoltage_Cell067 0;
BA_ "GenSigTimeoutTime_EVCU2" SG_ 1837 HVBatCellVoltage_Cell067 0;
BA_ "GenSigTimeoutTime_BPCM" SG_ 1837 HVBatCellVoltage_Cell067 0;
BA_ "GenSigTimeoutTime_IDCM" SG_ 1837 HVBatCellVoltage_Cell066 0;
BA_ "GenSigTimeoutTime_EVCU2" SG_ 1837 HVBatCellVoltage_Cell066 0;
BA_ "GenSigTimeoutTime_BPCM" SG_ 1837 HVBatCellVoltage_Cell066 0;
BA_ "GenSigTimeoutTime_IDCM" SG_ 1837 HVBatCellVoltage_Cell065 0;
BA_ "GenSigTimeoutTime_EVCU2" SG_ 1837 HVBatCellVoltage_Cell065 0;
BA_ "GenSigTimeoutTime_BPCM" SG_ 1837 HVBatCellVoltage_Cell065 0;
BA_ "GenSigTimeoutTime_IDCM" SG_ 1837 HVBatCellVoltage_Cell064 0;
BA_ "GenSigTimeoutTime_EVCU2" SG_ 1837 HVBatCellVoltage_Cell064 0;
BA_ "GenSigTimeoutTime_BPCM" SG_ 1837 HVBatCellVoltage_Cell064 0;
BA_ "GenSigTimeoutTime_IDCM" SG_ 1837 HVBatCellVoltage_Cell063 0;
BA_ "GenSigTimeoutTime_EVCU2" SG_ 1837 HVBatCellVoltage_Cell063 0;
BA_ "GenSigTimeoutTime_BPCM" SG_ 1837 HVBatCellVoltage_Cell063 0;
BA_ "GenSigTimeoutTime_IDCM" SG_ 1837 HVBatCellVoltage_Cell062 0;
BA_ "GenSigTimeoutTime_EVCU2" SG_ 1837 HVBatCellVoltage_Cell062 0;
BA_ "GenSigTimeoutTime_BPCM" SG_ 1837 HVBatCellVoltage_Cell062 0;
BA_ "GenSigTimeoutTime_IDCM" SG_ 1837 HVBatCellVoltage_Cell061 0;
BA_ "GenSigTimeoutTime_EVCU2" SG_ 1837 HVBatCellVoltage_Cell061 0;
BA_ "GenSigTimeoutTime_BPCM" SG_ 1837 HVBatCellVoltage_Cell061 0;
BA_ "GenSigTimeoutTime_IDCM" SG_ 1837 HVBatCellVoltage_Cell060 0;
BA_ "GenSigTimeoutTime_EVCU2" SG_ 1837 HVBatCellVoltage_Cell060 0;
BA_ "GenSigTimeoutTime_BPCM" SG_ 1837 HVBatCellVoltage_Cell060 0;
BA_ "GenSigTimeoutTime_IDCM" SG_ 1837 HVBatCellVoltage_Cell059 0;
BA_ "GenSigTimeoutTime_EVCU2" SG_ 1837 HVBatCellVoltage_Cell059 0;
BA_ "GenSigTimeoutTime_BPCM" SG_ 1837 HVBatCellVoltage_Cell059 0;
BA_ "GenSigTimeoutTime_IDCM" SG_ 1837 HVBatCellVoltage_Cell058 0;
BA_ "GenSigTimeoutTime_EVCU2" SG_ 1837 HVBatCellVoltage_Cell058 0;
BA_ "GenSigTimeoutTime_BPCM" SG_ 1837 HVBatCellVoltage_Cell058 0;
BA_ "GenSigTimeoutTime_IDCM" SG_ 1837 HVBatCellVoltage_Cell057 0;
BA_ "GenSigTimeoutTime_EVCU2" SG_ 1837 HVBatCellVoltage_Cell057 0;
BA_ "GenSigTimeoutTime_BPCM" SG_ 1837 HVBatCellVoltage_Cell057 0;
BA_ "GenSigTimeoutTime_IDCM" SG_ 1837 HVBatCellVoltage_Cell056 0;
BA_ "GenSigTimeoutTime_EVCU2" SG_ 1837 HVBatCellVoltage_Cell056 0;
BA_ "GenSigTimeoutTime_BPCM" SG_ 1837 HVBatCellVoltage_Cell056 0;
BA_ "GenSigTimeoutTime_IDCM" SG_ 1837 HVBatCellVoltage_Cell055 0;
BA_ "GenSigTimeoutTime_EVCU2" SG_ 1837 HVBatCellVoltage_Cell055 0;
BA_ "GenSigTimeoutTime_BPCM" SG_ 1837 HVBatCellVoltage_Cell055 0;
BA_ "GenSigTimeoutTime_IDCM" SG_ 1836 HVBatCellVoltage_Cell054 0;
BA_ "GenSigTimeoutTime_EVCU2" SG_ 1836 HVBatCellVoltage_Cell054 0;
BA_ "GenSigTimeoutTime_BPCM" SG_ 1836 HVBatCellVoltage_Cell054 0;
BA_ "GenSigTimeoutTime_IDCM" SG_ 1836 HVBatCellVoltage_Cell053 0;
BA_ "GenSigTimeoutTime_EVCU2" SG_ 1836 HVBatCellVoltage_Cell053 0;
BA_ "GenSigTimeoutTime_BPCM" SG_ 1836 HVBatCellVoltage_Cell053 0;
BA_ "GenSigTimeoutTime_IDCM" SG_ 1836 HVBatCellVoltage_Cell052 0;
BA_ "GenSigTimeoutTime_EVCU2" SG_ 1836 HVBatCellVoltage_Cell052 0;
BA_ "GenSigTimeoutTime_BPCM" SG_ 1836 HVBatCellVoltage_Cell052 0;
BA_ "GenSigTimeoutTime_IDCM" SG_ 1836 HVBatCellVoltage_Cell051 0;
BA_ "GenSigTimeoutTime_EVCU2" SG_ 1836 HVBatCellVoltage_Cell051 0;
BA_ "GenSigTimeoutTime_BPCM" SG_ 1836 HVBatCellVoltage_Cell051 0;
BA_ "GenSigTimeoutTime_IDCM" SG_ 1836 HVBatCellVoltage_Cell050 0;
BA_ "GenSigTimeoutTime_EVCU2" SG_ 1836 HVBatCellVoltage_Cell050 0;
BA_ "GenSigTimeoutTime_BPCM" SG_ 1836 HVBatCellVoltage_Cell050 0;
BA_ "GenSigTimeoutTime_IDCM" SG_ 1836 HVBatCellVoltage_Cell049 0;
BA_ "GenSigTimeoutTime_EVCU2" SG_ 1836 HVBatCellVoltage_Cell049 0;
BA_ "GenSigTimeoutTime_BPCM" SG_ 1836 HVBatCellVoltage_Cell049 0;
BA_ "GenSigTimeoutTime_IDCM" SG_ 1836 HVBatCellVoltage_Cell048 0;
BA_ "GenSigTimeoutTime_EVCU2" SG_ 1836 HVBatCellVoltage_Cell048 0;
BA_ "GenSigTimeoutTime_BPCM" SG_ 1836 HVBatCellVoltage_Cell048 0;
BA_ "GenSigTimeoutTime_IDCM" SG_ 1836 HVBatCellVoltage_Cell047 0;
BA_ "GenSigTimeoutTime_EVCU2" SG_ 1836 HVBatCellVoltage_Cell047 0;
BA_ "GenSigTimeoutTime_BPCM" SG_ 1836 HVBatCellVoltage_Cell047 0;
BA_ "GenSigTimeoutTime_IDCM" SG_ 1836 HVBatCellVoltage_Cell046 0;
BA_ "GenSigTimeoutTime_EVCU2" SG_ 1836 HVBatCellVoltage_Cell046 0;
BA_ "GenSigTimeoutTime_BPCM" SG_ 1836 HVBatCellVoltage_Cell046 0;
BA_ "GenSigTimeoutTime_IDCM" SG_ 1836 HVBatCellVoltage_Cell045 0;
BA_ "GenSigTimeoutTime_EVCU2" SG_ 1836 HVBatCellVoltage_Cell045 0;
BA_ "GenSigTimeoutTime_BPCM" SG_ 1836 HVBatCellVoltage_Cell045 0;
BA_ "GenSigTimeoutTime_IDCM" SG_ 1836 HVBatCellVoltage_Cell044 0;
BA_ "GenSigTimeoutTime_EVCU2" SG_ 1836 HVBatCellVoltage_Cell044 0;
BA_ "GenSigTimeoutTime_BPCM" SG_ 1836 HVBatCellVoltage_Cell044 0;
BA_ "GenSigTimeoutTime_IDCM" SG_ 1836 HVBatCellVoltage_Cell043 0;
BA_ "GenSigTimeoutTime_EVCU2" SG_ 1836 HVBatCellVoltage_Cell043 0;
BA_ "GenSigTimeoutTime_BPCM" SG_ 1836 HVBatCellVoltage_Cell043 0;
BA_ "GenSigTimeoutTime_IDCM" SG_ 1836 HVBatCellVoltage_Cell042 0;
BA_ "GenSigTimeoutTime_EVCU2" SG_ 1836 HVBatCellVoltage_Cell042 0;
BA_ "GenSigTimeoutTime_BPCM" SG_ 1836 HVBatCellVoltage_Cell042 0;
BA_ "GenSigTimeoutTime_IDCM" SG_ 1836 HVBatCellVoltage_Cell041 0;
BA_ "GenSigTimeoutTime_EVCU2" SG_ 1836 HVBatCellVoltage_Cell041 0;
BA_ "GenSigTimeoutTime_BPCM" SG_ 1836 HVBatCellVoltage_Cell041 0;
BA_ "GenSigTimeoutTime_IDCM" SG_ 1836 HVBatCellVoltage_Cell040 0;
BA_ "GenSigTimeoutTime_EVCU2" SG_ 1836 HVBatCellVoltage_Cell040 0;
BA_ "GenSigTimeoutTime_BPCM" SG_ 1836 HVBatCellVoltage_Cell040 0;
BA_ "GenSigTimeoutTime_IDCM" SG_ 1836 HVBatCellVoltage_Cell039 0;
BA_ "GenSigTimeoutTime_EVCU2" SG_ 1836 HVBatCellVoltage_Cell039 0;
BA_ "GenSigTimeoutTime_BPCM" SG_ 1836 HVBatCellVoltage_Cell039 0;
BA_ "GenSigTimeoutTime_IDCM" SG_ 1836 HVBatCellVoltage_Cell038 0;
BA_ "GenSigTimeoutTime_EVCU2" SG_ 1836 HVBatCellVoltage_Cell038 0;
BA_ "GenSigTimeoutTime_BPCM" SG_ 1836 HVBatCellVoltage_Cell038 0;
BA_ "GenSigTimeoutTime_IDCM" SG_ 1836 HVBatCellVoltage_Cell037 0;
BA_ "GenSigTimeoutTime_EVCU2" SG_ 1836 HVBatCellVoltage_Cell037 0;
BA_ "GenSigTimeoutTime_BPCM" SG_ 1836 HVBatCellVoltage_Cell037 0;
BA_ "GenSigTimeoutTime_IDCM" SG_ 1836 HVBatCellVoltage_Cell036 0;
BA_ "GenSigTimeoutTime_EVCU2" SG_ 1836 HVBatCellVoltage_Cell036 0;
BA_ "GenSigTimeoutTime_BPCM" SG_ 1836 HVBatCellVoltage_Cell036 0;
BA_ "GenSigTimeoutTime_IDCM" SG_ 1836 HVBatCellVoltage_Cell035 0;
BA_ "GenSigTimeoutTime_EVCU2" SG_ 1836 HVBatCellVoltage_Cell035 0;
BA_ "GenSigTimeoutTime_BPCM" SG_ 1836 HVBatCellVoltage_Cell035 0;
BA_ "GenSigTimeoutTime_IDCM" SG_ 1836 HVBatCellVoltage_Cell034 0;
BA_ "GenSigTimeoutTime_EVCU2" SG_ 1836 HVBatCellVoltage_Cell034 0;
BA_ "GenSigTimeoutTime_BPCM" SG_ 1836 HVBatCellVoltage_Cell034 0;
BA_ "GenSigTimeoutTime_IDCM" SG_ 1836 HVBatCellVoltage_Cell033 0;
BA_ "GenSigTimeoutTime_EVCU2" SG_ 1836 HVBatCellVoltage_Cell033 0;
BA_ "GenSigTimeoutTime_BPCM" SG_ 1836 HVBatCellVoltage_Cell033 0;
BA_ "GenSigTimeoutTime_IDCM" SG_ 1836 HVBatCellVoltage_Cell032 0;
BA_ "GenSigTimeoutTime_EVCU2" SG_ 1836 HVBatCellVoltage_Cell032 0;
BA_ "GenSigTimeoutTime_BPCM" SG_ 1836 HVBatCellVoltage_Cell032 0;
BA_ "GenSigTimeoutTime_IDCM" SG_ 1836 HVBatCellVoltage_Cell031 0;
BA_ "GenSigTimeoutTime_EVCU2" SG_ 1836 HVBatCellVoltage_Cell031 0;
BA_ "GenSigTimeoutTime_BPCM" SG_ 1836 HVBatCellVoltage_Cell031 0;
BA_ "GenSigTimeoutTime_IDCM" SG_ 1836 HVBatCellVoltage_Cell030 0;
BA_ "GenSigTimeoutTime_EVCU2" SG_ 1836 HVBatCellVoltage_Cell030 0;
BA_ "GenSigTimeoutTime_BPCM" SG_ 1836 HVBatCellVoltage_Cell030 0;
BA_ "GenSigTimeoutTime_IDCM" SG_ 1836 HVBatCellVoltage_Cell029 0;
BA_ "GenSigTimeoutTime_EVCU2" SG_ 1836 HVBatCellVoltage_Cell029 0;
BA_ "GenSigTimeoutTime_BPCM" SG_ 1836 HVBatCellVoltage_Cell029 0;
BA_ "GenSigTimeoutTime_IDCM" SG_ 1836 HVBatCellVoltage_Cell028 0;
BA_ "GenSigTimeoutTime_EVCU2" SG_ 1836 HVBatCellVoltage_Cell028 0;
BA_ "GenSigTimeoutTime_BPCM" SG_ 1836 HVBatCellVoltage_Cell028 0;
BA_ "GenSigTimeoutTime_IDCM" SG_ 1835 HVBatCellVoltage_Cell027 0;
BA_ "GenSigTimeoutTime_EVCU2" SG_ 1835 HVBatCellVoltage_Cell027 0;
BA_ "GenSigTimeoutTime_BPCM" SG_ 1835 HVBatCellVoltage_Cell027 0;
BA_ "GenSigTimeoutTime_IDCM" SG_ 1835 HVBatCellVoltage_Cell026 0;
BA_ "GenSigTimeoutTime_EVCU2" SG_ 1835 HVBatCellVoltage_Cell026 0;
BA_ "GenSigTimeoutTime_BPCM" SG_ 1835 HVBatCellVoltage_Cell026 0;
BA_ "GenSigTimeoutTime_IDCM" SG_ 1835 HVBatCellVoltage_Cell025 0;
BA_ "GenSigTimeoutTime_EVCU2" SG_ 1835 HVBatCellVoltage_Cell025 0;
BA_ "GenSigTimeoutTime_BPCM" SG_ 1835 HVBatCellVoltage_Cell025 0;
BA_ "GenSigTimeoutTime_IDCM" SG_ 1835 HVBatCellVoltage_Cell024 0;
BA_ "GenSigTimeoutTime_EVCU2" SG_ 1835 HVBatCellVoltage_Cell024 0;
BA_ "GenSigTimeoutTime_BPCM" SG_ 1835 HVBatCellVoltage_Cell024 0;
BA_ "GenSigTimeoutTime_IDCM" SG_ 1835 HVBatCellVoltage_Cell023 0;
BA_ "GenSigTimeoutTime_EVCU2" SG_ 1835 HVBatCellVoltage_Cell023 0;
BA_ "GenSigTimeoutTime_BPCM" SG_ 1835 HVBatCellVoltage_Cell023 0;
BA_ "GenSigTimeoutTime_IDCM" SG_ 1835 HVBatCellVoltage_Cell022 0;
BA_ "GenSigTimeoutTime_EVCU2" SG_ 1835 HVBatCellVoltage_Cell022 0;
BA_ "GenSigTimeoutTime_BPCM" SG_ 1835 HVBatCellVoltage_Cell022 0;
BA_ "GenSigTimeoutTime_IDCM" SG_ 1835 HVBatCellVoltage_Cell021 0;
BA_ "GenSigTimeoutTime_EVCU2" SG_ 1835 HVBatCellVoltage_Cell021 0;
BA_ "GenSigTimeoutTime_BPCM" SG_ 1835 HVBatCellVoltage_Cell021 0;
BA_ "GenSigTimeoutTime_IDCM" SG_ 1835 HVBatCellVoltage_Cell020 0;
BA_ "GenSigTimeoutTime_EVCU2" SG_ 1835 HVBatCellVoltage_Cell020 0;
BA_ "GenSigTimeoutTime_BPCM" SG_ 1835 HVBatCellVoltage_Cell020 0;
BA_ "GenSigTimeoutTime_IDCM" SG_ 1835 HVBatCellVoltage_Cell019 0;
BA_ "GenSigTimeoutTime_EVCU2" SG_ 1835 HVBatCellVoltage_Cell019 0;
BA_ "GenSigTimeoutTime_BPCM" SG_ 1835 HVBatCellVoltage_Cell019 0;
BA_ "GenSigTimeoutTime_IDCM" SG_ 1835 HVBatCellVoltage_Cell018 0;
BA_ "GenSigTimeoutTime_EVCU2" SG_ 1835 HVBatCellVoltage_Cell018 0;
BA_ "GenSigTimeoutTime_BPCM" SG_ 1835 HVBatCellVoltage_Cell018 0;
BA_ "GenSigTimeoutTime_IDCM" SG_ 1835 HVBatCellVoltage_Cell017 0;
BA_ "GenSigTimeoutTime_EVCU2" SG_ 1835 HVBatCellVoltage_Cell017 0;
BA_ "GenSigTimeoutTime_BPCM" SG_ 1835 HVBatCellVoltage_Cell017 0;
BA_ "GenSigTimeoutTime_IDCM" SG_ 1835 HVBatCellVoltage_Cell016 0;
BA_ "GenSigTimeoutTime_EVCU2" SG_ 1835 HVBatCellVoltage_Cell016 0;
BA_ "GenSigTimeoutTime_BPCM" SG_ 1835 HVBatCellVoltage_Cell016 0;
BA_ "GenSigTimeoutTime_IDCM" SG_ 1835 HVBatCellVoltage_Cell015 0;
BA_ "GenSigTimeoutTime_EVCU2" SG_ 1835 HVBatCellVoltage_Cell015 0;
BA_ "GenSigTimeoutTime_BPCM" SG_ 1835 HVBatCellVoltage_Cell015 0;
BA_ "GenSigTimeoutTime_IDCM" SG_ 1835 HVBatCellVoltage_Cell014 0;
BA_ "GenSigTimeoutTime_EVCU2" SG_ 1835 HVBatCellVoltage_Cell014 0;
BA_ "GenSigTimeoutTime_BPCM" SG_ 1835 HVBatCellVoltage_Cell014 0;
BA_ "GenSigTimeoutTime_IDCM" SG_ 1835 HVBatCellVoltage_Cell013 0;
BA_ "GenSigTimeoutTime_EVCU2" SG_ 1835 HVBatCellVoltage_Cell013 0;
BA_ "GenSigTimeoutTime_BPCM" SG_ 1835 HVBatCellVoltage_Cell013 0;
BA_ "GenSigTimeoutTime_IDCM" SG_ 1835 HVBatCellVoltage_Cell012 0;
BA_ "GenSigTimeoutTime_EVCU2" SG_ 1835 HVBatCellVoltage_Cell012 0;
BA_ "GenSigTimeoutTime_BPCM" SG_ 1835 HVBatCellVoltage_Cell012 0;
BA_ "GenSigTimeoutTime_IDCM" SG_ 1835 HVBatCellVoltage_Cell011 0;
BA_ "GenSigTimeoutTime_EVCU2" SG_ 1835 HVBatCellVoltage_Cell011 0;
BA_ "GenSigTimeoutTime_BPCM" SG_ 1835 HVBatCellVoltage_Cell011 0;
BA_ "GenSigTimeoutTime_IDCM" SG_ 1835 HVBatCellVoltage_Cell010 0;
BA_ "GenSigTimeoutTime_EVCU2" SG_ 1835 HVBatCellVoltage_Cell010 0;
BA_ "GenSigTimeoutTime_BPCM" SG_ 1835 HVBatCellVoltage_Cell010 0;
BA_ "GenSigTimeoutTime_IDCM" SG_ 1835 HVBatCellVoltage_Cell009 0;
BA_ "GenSigTimeoutTime_EVCU2" SG_ 1835 HVBatCellVoltage_Cell009 0;
BA_ "GenSigTimeoutTime_BPCM" SG_ 1835 HVBatCellVoltage_Cell009 0;
BA_ "GenSigTimeoutTime_IDCM" SG_ 1835 HVBatCellVoltage_Cell008 0;
BA_ "GenSigTimeoutTime_EVCU2" SG_ 1835 HVBatCellVoltage_Cell008 0;
BA_ "GenSigTimeoutTime_BPCM" SG_ 1835 HVBatCellVoltage_Cell008 0;
BA_ "GenSigTimeoutTime_IDCM" SG_ 1835 HVBatCellVoltage_Cell007 0;
BA_ "GenSigTimeoutTime_EVCU2" SG_ 1835 HVBatCellVoltage_Cell007 0;
BA_ "GenSigTimeoutTime_BPCM" SG_ 1835 HVBatCellVoltage_Cell007 0;
BA_ "GenSigTimeoutTime_IDCM" SG_ 1835 HVBatCellVoltage_Cell006 0;
BA_ "GenSigTimeoutTime_EVCU2" SG_ 1835 HVBatCellVoltage_Cell006 0;
BA_ "GenSigTimeoutTime_BPCM" SG_ 1835 HVBatCellVoltage_Cell006 0;
BA_ "GenSigTimeoutTime_IDCM" SG_ 1835 HVBatCellVoltage_Cell005 0;
BA_ "GenSigTimeoutTime_EVCU2" SG_ 1835 HVBatCellVoltage_Cell005 0;
BA_ "GenSigTimeoutTime_BPCM" SG_ 1835 HVBatCellVoltage_Cell005 0;
BA_ "GenSigTimeoutTime_IDCM" SG_ 1835 HVBatCellVoltage_Cell004 0;
BA_ "GenSigTimeoutTime_EVCU2" SG_ 1835 HVBatCellVoltage_Cell004 0;
BA_ "GenSigTimeoutTime_BPCM" SG_ 1835 HVBatCellVoltage_Cell004 0;
BA_ "GenSigTimeoutTime_IDCM" SG_ 1835 HVBatCellVoltage_Cell003 0;
BA_ "GenSigTimeoutTime_EVCU2" SG_ 1835 HVBatCellVoltage_Cell003 0;
BA_ "GenSigTimeoutTime_BPCM" SG_ 1835 HVBatCellVoltage_Cell003 0;
BA_ "GenSigTimeoutTime_IDCM" SG_ 1835 HVBatCellVoltage_Cell002 0;
BA_ "GenSigTimeoutTime_EVCU2" SG_ 1835 HVBatCellVoltage_Cell002 0;
BA_ "GenSigTimeoutTime_BPCM" SG_ 1835 HVBatCellVoltage_Cell002 0;
BA_ "GenSigTimeoutTime_IDCM" SG_ 1835 HVBatCellVoltage_Cell001 0;
BA_ "GenSigTimeoutTime_EVCU2" SG_ 1835 HVBatCellVoltage_Cell001 0;
BA_ "GenSigTimeoutTime_BPCM" SG_ 1835 HVBatCellVoltage_Cell001 0;
BA_ "GenSigTimeoutTime_SGW" SG_ 1035 RadFanReq 0;
BA_ "GenSigTimeoutTime_IDCM" SG_ 1035 RadFanReq 0;
BA_ "GenSigTimeoutTime_EVCU2" SG_ 1035 RadFanReq 0;
BA_ "GenSigTimeoutTime_PPIM" SG_ 1035 RadFanReq 0;
BA_ "GenSigTimeoutTime_HCP" SG_ 1035 RadFanReq 0;
BA_ "GenSigTimeoutTime_SGW" SG_ 1035 EngSpd 0;
BA_ "GenSigTimeoutTime_IDCM" SG_ 1035 EngSpd 0;
BA_ "GenSigTimeoutTime_EVCU2" SG_ 1035 EngSpd 0;
BA_ "GenSigTimeoutTime_PPIM" SG_ 1035 EngSpd 0;
BA_ "GenSigTimeoutTime_HCP" SG_ 1035 EngSpd 0;
BA_ "GenSigTimeoutTime_SGW" SG_ 1035 EngCltTmpV 0;
BA_ "GenSigTimeoutTime_IDCM" SG_ 1035 EngCltTmpV 0;
BA_ "GenSigTimeoutTime_EVCU2" SG_ 1035 EngCltTmpV 0;
BA_ "GenSigTimeoutTime_PPIM" SG_ 1035 EngCltTmpV 0;
BA_ "GenSigTimeoutTime_HCP" SG_ 1035 EngCltTmpV 0;
BA_ "GenSigTimeoutTime_SGW" SG_ 1035 EngCltTmp 0;
BA_ "GenSigTimeoutTime_IDCM" SG_ 1035 EngCltTmp 0;
BA_ "GenSigTimeoutTime_EVCU2" SG_ 1035 EngCltTmp 0;
BA_ "GenSigStartValue" SG_ 1035 EngCltTmp 255;
BA_ "GenSigTimeoutTime_PPIM" SG_ 1035 EngCltTmp 0;
BA_ "GenSigTimeoutTime_HCP" SG_ 1035 EngCltTmp 0;
BA_ "GenSigTimeoutTime_SGW" SG_ 750 Battery_Volt_1 0;
BA_ "GenSigTimeoutTime_EVCU2" SG_ 750 Battery_Volt_1 0;
BA_ "GenSigTimeoutTime_HCP" SG_ 750 Battery_Volt_1 0;
BA_ "GenSigTimeoutTime_SGW" SG_ 1436 Blower_Speed 0;
BA_ "GenSigTimeoutTime_IDCM" SG_ 1436 Blower_Speed 0;
BA_ "GenSigTimeoutTime_EVCU2" SG_ 1436 Blower_Speed 0;
BA_ "GenSigSendType" SG_ 1436 Blower_Speed 3;
BA_ "GenSigTimeoutTime_PPIM" SG_ 1436 Blower_Speed 0;
BA_ "GenSigTimeoutTime_HCP" SG_ 1436 Blower_Speed 0;
BA_ "GenSigTimeoutTime_SGW" SG_ 2654486640 CBV_bit1_1E384070 0;
BA_ "GenSigTimeoutTime_IDCM" SG_ 2654486640 CBV_bit1_1E384070 0;
BA_ "GenSigTimeoutTime_EVCU2" SG_ 2654486640 CBV_bit1_1E384070 0;
BA_ "GenSigTimeoutTime_BPCM" SG_ 2654486640 CBV_bit1_1E384070 0;
BA_ "GenSigTimeoutTime_PPIM" SG_ 2654486640 CBV_bit1_1E384070 0;
BA_ "GenSigTimeoutTime_HCP" SG_ 2654486640 CBV_bit1_1E384070 0;
BA_ "GenSigTimeoutTime_SGW" SG_ 2654486640 CBV_bit2_1E384070 0;
BA_ "GenSigTimeoutTime_IDCM" SG_ 2654486640 CBV_bit2_1E384070 0;
BA_ "GenSigTimeoutTime_EVCU2" SG_ 2654486640 CBV_bit2_1E384070 0;
BA_ "GenSigTimeoutTime_BPCM" SG_ 2654486640 CBV_bit2_1E384070 0;
BA_ "GenSigTimeoutTime_PPIM" SG_ 2654486640 CBV_bit2_1E384070 0;
BA_ "GenSigTimeoutTime_HCP" SG_ 2654486640 CBV_bit2_1E384070 0;
BA_ "GenSigTimeoutTime_SGW" SG_ 2654486640 CBV_bit5_1E384070 0;
BA_ "GenSigTimeoutTime_IDCM" SG_ 2654486640 CBV_bit5_1E384070 0;
BA_ "GenSigTimeoutTime_EVCU2" SG_ 2654486640 CBV_bit5_1E384070 0;
BA_ "GenSigTimeoutTime_BPCM" SG_ 2654486640 CBV_bit5_1E384070 0;
BA_ "GenSigTimeoutTime_PPIM" SG_ 2654486640 CBV_bit5_1E384070 0;
BA_ "GenSigTimeoutTime_HCP" SG_ 2654486640 CBV_bit5_1E384070 0;
BA_ "GenSigTimeoutTime_SGW" SG_ 2654486640 CBV_bit7_1E384070 0;
BA_ "GenSigTimeoutTime_IDCM" SG_ 2654486640 CBV_bit7_1E384070 0;
BA_ "GenSigTimeoutTime_EVCU2" SG_ 2654486640 CBV_bit7_1E384070 0;
BA_ "GenSigTimeoutTime_BPCM" SG_ 2654486640 CBV_bit7_1E384070 0;
BA_ "GenSigTimeoutTime_PPIM" SG_ 2654486640 CBV_bit7_1E384070 0;
BA_ "GenSigTimeoutTime_HCP" SG_ 2654486640 CBV_bit7_1E384070 0;
BA_ "GenSigTimeoutTime_SGW" SG_ 2654486640 SourceNodeIdentifier_1E384070 0;
BA_ "GenSigTimeoutTime_IDCM" SG_ 2654486640 SourceNodeIdentifier_1E384070 0;
BA_ "GenSigTimeoutTime_EVCU2" SG_ 2654486640 SourceNodeIdentifier_1E384070 0;
BA_ "GenSigTimeoutTime_BPCM" SG_ 2654486640 SourceNodeIdentifier_1E384070 0;
BA_ "GenSigTimeoutTime_PPIM" SG_ 2654486640 SourceNodeIdentifier_1E384070 0;
BA_ "GenSigTimeoutTime_HCP" SG_ 2654486640 SourceNodeIdentifier_1E384070 0;
BA_ "GenSigTimeoutTime_SGW" SG_ 2654486640 CBV_bit0_RepeatMessageRequestBit 0;
BA_ "GenSigTimeoutTime_IDCM" SG_ 2654486640 CBV_bit0_RepeatMessageRequestBit 0;
BA_ "GenSigTimeoutTime_EVCU2" SG_ 2654486640 CBV_bit0_RepeatMessageRequestBit 0;
BA_ "GenSigTimeoutTime_BPCM" SG_ 2654486640 CBV_bit0_RepeatMessageRequestBit 0;
BA_ "GenSigTimeoutTime_PPIM" SG_ 2654486640 CBV_bit0_RepeatMessageRequestBit 0;
BA_ "GenSigTimeoutTime_HCP" SG_ 2654486640 CBV_bit0_RepeatMessageRequestBit 0;
BA_ "SystemSignalLongSymbol" SG_ 2654486640 CBV_bit0_RepeatMessageRequestBit "CBV_bit0_RepeatMessageRequestBit_1E384070";
BA_ "GenSigTimeoutTime_SGW" SG_ 2654486640 CBV_bit3_NMCoordinatorBit_1E3840 0;
BA_ "GenSigTimeoutTime_IDCM" SG_ 2654486640 CBV_bit3_NMCoordinatorBit_1E3840 0;
BA_ "GenSigTimeoutTime_EVCU2" SG_ 2654486640 CBV_bit3_NMCoordinatorBit_1E3840 0;
BA_ "GenSigTimeoutTime_BPCM" SG_ 2654486640 CBV_bit3_NMCoordinatorBit_1E3840 0;
BA_ "GenSigTimeoutTime_PPIM" SG_ 2654486640 CBV_bit3_NMCoordinatorBit_1E3840 0;
BA_ "GenSigTimeoutTime_HCP" SG_ 2654486640 CBV_bit3_NMCoordinatorBit_1E3840 0;
BA_ "SystemSignalLongSymbol" SG_ 2654486640 CBV_bit3_NMCoordinatorBit_1E3840 "CBV_bit3_NMCoordinatorBit_1E384070";
BA_ "GenSigTimeoutTime_SGW" SG_ 2654486640 CBV_bit4_ActiveWakeupBit_1E38407 0;
BA_ "GenSigTimeoutTime_IDCM" SG_ 2654486640 CBV_bit4_ActiveWakeupBit_1E38407 0;
BA_ "GenSigTimeoutTime_EVCU2" SG_ 2654486640 CBV_bit4_ActiveWakeupBit_1E38407 0;
BA_ "GenSigTimeoutTime_BPCM" SG_ 2654486640 CBV_bit4_ActiveWakeupBit_1E38407 0;
BA_ "GenSigTimeoutTime_PPIM" SG_ 2654486640 CBV_bit4_ActiveWakeupBit_1E38407 0;
BA_ "GenSigTimeoutTime_HCP" SG_ 2654486640 CBV_bit4_ActiveWakeupBit_1E38407 0;
BA_ "SystemSignalLongSymbol" SG_ 2654486640 CBV_bit4_ActiveWakeupBit_1E38407 "CBV_bit4_ActiveWakeupBit_1E384070";
BA_ "GenSigTimeoutTime_SGW" SG_ 2654486640 CBV_bit6_PartialNtwInfBit_1E3840 0;
BA_ "GenSigTimeoutTime_IDCM" SG_ 2654486640 CBV_bit6_PartialNtwInfBit_1E3840 0;
BA_ "GenSigTimeoutTime_EVCU2" SG_ 2654486640 CBV_bit6_PartialNtwInfBit_1E3840 0;
BA_ "GenSigTimeoutTime_BPCM" SG_ 2654486640 CBV_bit6_PartialNtwInfBit_1E3840 0;
BA_ "GenSigTimeoutTime_PPIM" SG_ 2654486640 CBV_bit6_PartialNtwInfBit_1E3840 0;
BA_ "GenSigTimeoutTime_HCP" SG_ 2654486640 CBV_bit6_PartialNtwInfBit_1E3840 0;
BA_ "SystemSignalLongSymbol" SG_ 2654486640 CBV_bit6_PartialNtwInfBit_1E3840 "CBV_bit6_PartialNtwInfBit_1E384070";
BA_ "GenSigTimeoutTime_SGW" SG_ 2654486626 CBV_bit1_1E384062 0;
BA_ "GenSigTimeoutTime_IDCM" SG_ 2654486626 CBV_bit1_1E384062 0;
BA_ "GenSigTimeoutTime_EVCU2" SG_ 2654486626 CBV_bit1_1E384062 0;
BA_ "GenSigTimeoutTime_BPCM" SG_ 2654486626 CBV_bit1_1E384062 0;
BA_ "GenSigTimeoutTime_PPIM" SG_ 2654486626 CBV_bit1_1E384062 0;
BA_ "GenSigTimeoutTime_HCP" SG_ 2654486626 CBV_bit1_1E384062 0;
BA_ "GenSigTimeoutTime_SGW" SG_ 2654486626 CBV_bit2_1E384062 0;
BA_ "GenSigTimeoutTime_IDCM" SG_ 2654486626 CBV_bit2_1E384062 0;
BA_ "GenSigTimeoutTime_EVCU2" SG_ 2654486626 CBV_bit2_1E384062 0;
BA_ "GenSigTimeoutTime_BPCM" SG_ 2654486626 CBV_bit2_1E384062 0;
BA_ "GenSigTimeoutTime_PPIM" SG_ 2654486626 CBV_bit2_1E384062 0;
BA_ "GenSigTimeoutTime_HCP" SG_ 2654486626 CBV_bit2_1E384062 0;
BA_ "GenSigTimeoutTime_SGW" SG_ 2654486626 CBV_bit5_1E384062 0;
BA_ "GenSigTimeoutTime_IDCM" SG_ 2654486626 CBV_bit5_1E384062 0;
BA_ "GenSigTimeoutTime_EVCU2" SG_ 2654486626 CBV_bit5_1E384062 0;
BA_ "GenSigTimeoutTime_BPCM" SG_ 2654486626 CBV_bit5_1E384062 0;
BA_ "GenSigTimeoutTime_PPIM" SG_ 2654486626 CBV_bit5_1E384062 0;
BA_ "GenSigTimeoutTime_HCP" SG_ 2654486626 CBV_bit5_1E384062 0;
BA_ "GenSigTimeoutTime_SGW" SG_ 2654486626 CBV_bit7_1E384062 0;
BA_ "GenSigTimeoutTime_IDCM" SG_ 2654486626 CBV_bit7_1E384062 0;
BA_ "GenSigTimeoutTime_EVCU2" SG_ 2654486626 CBV_bit7_1E384062 0;
BA_ "GenSigTimeoutTime_BPCM" SG_ 2654486626 CBV_bit7_1E384062 0;
BA_ "GenSigTimeoutTime_PPIM" SG_ 2654486626 CBV_bit7_1E384062 0;
BA_ "GenSigTimeoutTime_HCP" SG_ 2654486626 CBV_bit7_1E384062 0;
BA_ "GenSigTimeoutTime_SGW" SG_ 2654486626 SourceNodeIdentifier_1E384062 0;
BA_ "GenSigTimeoutTime_IDCM" SG_ 2654486626 SourceNodeIdentifier_1E384062 0;
BA_ "GenSigTimeoutTime_EVCU2" SG_ 2654486626 SourceNodeIdentifier_1E384062 0;
BA_ "GenSigTimeoutTime_BPCM" SG_ 2654486626 SourceNodeIdentifier_1E384062 0;
BA_ "GenSigTimeoutTime_PPIM" SG_ 2654486626 SourceNodeIdentifier_1E384062 0;
BA_ "GenSigTimeoutTime_HCP" SG_ 2654486626 SourceNodeIdentifier_1E384062 0;
BA_ "GenSigTimeoutTime_SGW" SG_ 2654486626 CBV_bit0_RepeatMessageReque_0000 0;
BA_ "GenSigTimeoutTime_IDCM" SG_ 2654486626 CBV_bit0_RepeatMessageReque_0000 0;
BA_ "GenSigTimeoutTime_EVCU2" SG_ 2654486626 CBV_bit0_RepeatMessageReque_0000 0;
BA_ "GenSigTimeoutTime_BPCM" SG_ 2654486626 CBV_bit0_RepeatMessageReque_0000 0;
BA_ "GenSigTimeoutTime_PPIM" SG_ 2654486626 CBV_bit0_RepeatMessageReque_0000 0;
BA_ "GenSigTimeoutTime_HCP" SG_ 2654486626 CBV_bit0_RepeatMessageReque_0000 0;
BA_ "SystemSignalLongSymbol" SG_ 2654486626 CBV_bit0_RepeatMessageReque_0000 "CBV_bit0_RepeatMessageRequestBit_1E384062";
BA_ "GenSigTimeoutTime_SGW" SG_ 2654486626 CBV_bit3_NMCoordinatorBit_1_0000 0;
BA_ "GenSigTimeoutTime_IDCM" SG_ 2654486626 CBV_bit3_NMCoordinatorBit_1_0000 0;
BA_ "GenSigTimeoutTime_EVCU2" SG_ 2654486626 CBV_bit3_NMCoordinatorBit_1_0000 0;
BA_ "GenSigTimeoutTime_BPCM" SG_ 2654486626 CBV_bit3_NMCoordinatorBit_1_0000 0;
BA_ "GenSigTimeoutTime_PPIM" SG_ 2654486626 CBV_bit3_NMCoordinatorBit_1_0000 0;
BA_ "GenSigTimeoutTime_HCP" SG_ 2654486626 CBV_bit3_NMCoordinatorBit_1_0000 0;
BA_ "SystemSignalLongSymbol" SG_ 2654486626 CBV_bit3_NMCoordinatorBit_1_0000 "CBV_bit3_NMCoordinatorBit_1E384062";
BA_ "GenSigTimeoutTime_SGW" SG_ 2654486626 CBV_bit4_ActiveWakeupBit_1E38406 0;
BA_ "GenSigTimeoutTime_IDCM" SG_ 2654486626 CBV_bit4_ActiveWakeupBit_1E38406 0;
BA_ "GenSigTimeoutTime_EVCU2" SG_ 2654486626 CBV_bit4_ActiveWakeupBit_1E38406 0;
BA_ "GenSigTimeoutTime_BPCM" SG_ 2654486626 CBV_bit4_ActiveWakeupBit_1E38406 0;
BA_ "GenSigTimeoutTime_PPIM" SG_ 2654486626 CBV_bit4_ActiveWakeupBit_1E38406 0;
BA_ "GenSigTimeoutTime_HCP" SG_ 2654486626 CBV_bit4_ActiveWakeupBit_1E38406 0;
BA_ "SystemSignalLongSymbol" SG_ 2654486626 CBV_bit4_ActiveWakeupBit_1E38406 "CBV_bit4_ActiveWakeupBit_1E384062";
BA_ "GenSigTimeoutTime_SGW" SG_ 2654486626 CBV_bit6_PartialNtwInfBit_1_0000 0;
BA_ "GenSigTimeoutTime_IDCM" SG_ 2654486626 CBV_bit6_PartialNtwInfBit_1_0000 0;
BA_ "GenSigTimeoutTime_EVCU2" SG_ 2654486626 CBV_bit6_PartialNtwInfBit_1_0000 0;
BA_ "GenSigTimeoutTime_BPCM" SG_ 2654486626 CBV_bit6_PartialNtwInfBit_1_0000 0;
BA_ "GenSigTimeoutTime_PPIM" SG_ 2654486626 CBV_bit6_PartialNtwInfBit_1_0000 0;
BA_ "GenSigTimeoutTime_HCP" SG_ 2654486626 CBV_bit6_PartialNtwInfBit_1_0000 0;
BA_ "SystemSignalLongSymbol" SG_ 2654486626 CBV_bit6_PartialNtwInfBit_1_0000 "CBV_bit6_PartialNtwInfBit_1E384062";
BA_ "GenSigTimeoutTime_SGW" SG_ 276 HEV_ESS_Mode 0;
BA_ "GenSigTimeoutTime_IDCM" SG_ 276 HEV_ESS_Mode 0;
BA_ "GenSigTimeoutTime_EVCU2" SG_ 276 HEV_ESS_Mode 0;
BA_ "GenSigTimeoutTime_PPIM" SG_ 276 HEV_ESS_Mode 0;
BA_ "GenSigTimeoutTime_HCP" SG_ 276 HEV_ESS_Mode 0;
BA_ "GenSigTimeoutTime_SGW" SG_ 276 PropulsionSystemActive_114 0;
BA_ "GenSigTimeoutTime_IDCM" SG_ 276 PropulsionSystemActive_114 0;
BA_ "GenSigTimeoutTime_EVCU2" SG_ 276 PropulsionSystemActive_114 0;
BA_ "GenSigTimeoutTime_PPIM" SG_ 276 PropulsionSystemActive_114 0;
BA_ "GenSigTimeoutTime_HCP" SG_ 276 PropulsionSystemActive_114 0;
BA_ "GenSigTimeoutTime_PPIM" SG_ 262 PowertrainPrplsnActv 0;
BA_ "GenSigTimeoutTime_HCP" SG_ 262 PowertrainPrplsnActv 0;
BA_ "GenSigTimeoutTime_SGW" SG_ 262 PowertrainPrplsnActv 0;
BA_ "GenSigTimeoutTime_EVCU2" SG_ 262 PowertrainPrplsnActv 0;
BA_ "GenSigTimeoutTime_HCP" SG_ 262 EngineSpeed_W 0;
BA_ "GenSigTimeoutTime_SGW" SG_ 262 EngineSpeed_W 0;
BA_ "GenSigTimeoutTime_EVCU2" SG_ 262 EngineSpeed_W 0;
BA_ "GenSigTimeoutTime_SGW" SG_ 258 VehicleSpeedVSOSig 0;
BA_ "GenSigTimeoutTime_EVCU2" SG_ 258 VehicleSpeedVSOSig 0;
BA_ "GenSigTimeoutTime_HCP" SG_ 258 VehicleSpeedVSOSig 0;
BA_ "GenSigTimeoutTime_SGW" SG_ 2654486653 CBV_bit1_1E38407D 0;
BA_ "GenSigTimeoutTime_IDCM" SG_ 2654486653 CBV_bit1_1E38407D 0;
BA_ "GenSigTimeoutTime_EVCU2" SG_ 2654486653 CBV_bit1_1E38407D 0;
BA_ "GenSigTimeoutTime_BPCM" SG_ 2654486653 CBV_bit1_1E38407D 0;
BA_ "GenSigTimeoutTime_PPIM" SG_ 2654486653 CBV_bit1_1E38407D 0;
BA_ "GenSigTimeoutTime_HCP" SG_ 2654486653 CBV_bit1_1E38407D 0;
BA_ "GenSigTimeoutTime_SGW" SG_ 2654486653 CBV_bit2_1E38407D 0;
BA_ "GenSigTimeoutTime_IDCM" SG_ 2654486653 CBV_bit2_1E38407D 0;
BA_ "GenSigTimeoutTime_EVCU2" SG_ 2654486653 CBV_bit2_1E38407D 0;
BA_ "GenSigTimeoutTime_BPCM" SG_ 2654486653 CBV_bit2_1E38407D 0;
BA_ "GenSigTimeoutTime_PPIM" SG_ 2654486653 CBV_bit2_1E38407D 0;
BA_ "GenSigTimeoutTime_HCP" SG_ 2654486653 CBV_bit2_1E38407D 0;
BA_ "GenSigTimeoutTime_SGW" SG_ 2654486653 CBV_bit5_1E38407D 0;
BA_ "GenSigTimeoutTime_IDCM" SG_ 2654486653 CBV_bit5_1E38407D 0;
BA_ "GenSigTimeoutTime_EVCU2" SG_ 2654486653 CBV_bit5_1E38407D 0;
BA_ "GenSigTimeoutTime_BPCM" SG_ 2654486653 CBV_bit5_1E38407D 0;
BA_ "GenSigTimeoutTime_PPIM" SG_ 2654486653 CBV_bit5_1E38407D 0;
BA_ "GenSigTimeoutTime_HCP" SG_ 2654486653 CBV_bit5_1E38407D 0;
BA_ "GenSigTimeoutTime_SGW" SG_ 2654486653 CBV_bit7_1E38407D 0;
BA_ "GenSigTimeoutTime_IDCM" SG_ 2654486653 CBV_bit7_1E38407D 0;
BA_ "GenSigTimeoutTime_EVCU2" SG_ 2654486653 CBV_bit7_1E38407D 0;
BA_ "GenSigTimeoutTime_BPCM" SG_ 2654486653 CBV_bit7_1E38407D 0;
BA_ "GenSigTimeoutTime_PPIM" SG_ 2654486653 CBV_bit7_1E38407D 0;
BA_ "GenSigTimeoutTime_HCP" SG_ 2654486653 CBV_bit7_1E38407D 0;
BA_ "GenSigTimeoutTime_SGW" SG_ 2654486653 SourceNodeIdentifier_1E38407D 0;
BA_ "GenSigTimeoutTime_IDCM" SG_ 2654486653 SourceNodeIdentifier_1E38407D 0;
BA_ "GenSigTimeoutTime_EVCU2" SG_ 2654486653 SourceNodeIdentifier_1E38407D 0;
BA_ "GenSigTimeoutTime_BPCM" SG_ 2654486653 SourceNodeIdentifier_1E38407D 0;
BA_ "GenSigTimeoutTime_PPIM" SG_ 2654486653 SourceNodeIdentifier_1E38407D 0;
BA_ "GenSigTimeoutTime_HCP" SG_ 2654486653 SourceNodeIdentifier_1E38407D 0;
BA_ "GenSigTimeoutTime_SGW" SG_ 2654486653 CBV_bit0_RepeatMessageReque_0001 0;
BA_ "GenSigTimeoutTime_IDCM" SG_ 2654486653 CBV_bit0_RepeatMessageReque_0001 0;
BA_ "GenSigTimeoutTime_EVCU2" SG_ 2654486653 CBV_bit0_RepeatMessageReque_0001 0;
BA_ "GenSigTimeoutTime_BPCM" SG_ 2654486653 CBV_bit0_RepeatMessageReque_0001 0;
BA_ "GenSigTimeoutTime_PPIM" SG_ 2654486653 CBV_bit0_RepeatMessageReque_0001 0;
BA_ "GenSigTimeoutTime_HCP" SG_ 2654486653 CBV_bit0_RepeatMessageReque_0001 0;
BA_ "SystemSignalLongSymbol" SG_ 2654486653 CBV_bit0_RepeatMessageReque_0001 "CBV_bit0_RepeatMessageRequestBit_1E38407D";
BA_ "GenSigTimeoutTime_SGW" SG_ 2654486653 CBV_bit3_NMCoordinatorBit_1_0001 0;
BA_ "GenSigTimeoutTime_IDCM" SG_ 2654486653 CBV_bit3_NMCoordinatorBit_1_0001 0;
BA_ "GenSigTimeoutTime_EVCU2" SG_ 2654486653 CBV_bit3_NMCoordinatorBit_1_0001 0;
BA_ "GenSigTimeoutTime_BPCM" SG_ 2654486653 CBV_bit3_NMCoordinatorBit_1_0001 0;
BA_ "GenSigTimeoutTime_PPIM" SG_ 2654486653 CBV_bit3_NMCoordinatorBit_1_0001 0;
BA_ "GenSigTimeoutTime_HCP" SG_ 2654486653 CBV_bit3_NMCoordinatorBit_1_0001 0;
BA_ "SystemSignalLongSymbol" SG_ 2654486653 CBV_bit3_NMCoordinatorBit_1_0001 "CBV_bit3_NMCoordinatorBit_1E38407D";
BA_ "GenSigTimeoutTime_SGW" SG_ 2654486653 CBV_bit4_ActiveWakeupBit_1E_0000 0;
BA_ "GenSigTimeoutTime_IDCM" SG_ 2654486653 CBV_bit4_ActiveWakeupBit_1E_0000 0;
BA_ "GenSigTimeoutTime_EVCU2" SG_ 2654486653 CBV_bit4_ActiveWakeupBit_1E_0000 0;
BA_ "GenSigTimeoutTime_BPCM" SG_ 2654486653 CBV_bit4_ActiveWakeupBit_1E_0000 0;
BA_ "GenSigTimeoutTime_PPIM" SG_ 2654486653 CBV_bit4_ActiveWakeupBit_1E_0000 0;
BA_ "GenSigTimeoutTime_HCP" SG_ 2654486653 CBV_bit4_ActiveWakeupBit_1E_0000 0;
BA_ "SystemSignalLongSymbol" SG_ 2654486653 CBV_bit4_ActiveWakeupBit_1E_0000 "CBV_bit4_ActiveWakeupBit_1E38407D";
BA_ "GenSigTimeoutTime_SGW" SG_ 2654486653 CBV_bit6_PartialNtwInfBit_1_0001 0;
BA_ "GenSigTimeoutTime_IDCM" SG_ 2654486653 CBV_bit6_PartialNtwInfBit_1_0001 0;
BA_ "GenSigTimeoutTime_EVCU2" SG_ 2654486653 CBV_bit6_PartialNtwInfBit_1_0001 0;
BA_ "GenSigTimeoutTime_BPCM" SG_ 2654486653 CBV_bit6_PartialNtwInfBit_1_0001 0;
BA_ "GenSigTimeoutTime_PPIM" SG_ 2654486653 CBV_bit6_PartialNtwInfBit_1_0001 0;
BA_ "GenSigTimeoutTime_HCP" SG_ 2654486653 CBV_bit6_PartialNtwInfBit_1_0001 0;
BA_ "SystemSignalLongSymbol" SG_ 2654486653 CBV_bit6_PartialNtwInfBit_1_0001 "CBV_bit6_PartialNtwInfBit_1E38407D";
BA_ "GenSigTimeoutTime_SGW" SG_ 2654486598 CBV_bit1_1E384046 0;
BA_ "GenSigTimeoutTime_IDCM" SG_ 2654486598 CBV_bit1_1E384046 0;
BA_ "GenSigTimeoutTime_EVCU2" SG_ 2654486598 CBV_bit1_1E384046 0;
BA_ "GenSigTimeoutTime_BPCM" SG_ 2654486598 CBV_bit1_1E384046 0;
BA_ "GenSigTimeoutTime_PPIM" SG_ 2654486598 CBV_bit1_1E384046 0;
BA_ "GenSigTimeoutTime_HCP" SG_ 2654486598 CBV_bit1_1E384046 0;
BA_ "GenSigTimeoutTime_SGW" SG_ 2654486598 CBV_bit2_1E384046 0;
BA_ "GenSigTimeoutTime_IDCM" SG_ 2654486598 CBV_bit2_1E384046 0;
BA_ "GenSigTimeoutTime_EVCU2" SG_ 2654486598 CBV_bit2_1E384046 0;
BA_ "GenSigTimeoutTime_BPCM" SG_ 2654486598 CBV_bit2_1E384046 0;
BA_ "GenSigTimeoutTime_PPIM" SG_ 2654486598 CBV_bit2_1E384046 0;
BA_ "GenSigTimeoutTime_HCP" SG_ 2654486598 CBV_bit2_1E384046 0;
BA_ "GenSigTimeoutTime_SGW" SG_ 2654486598 CBV_bit5_1E384046 0;
BA_ "GenSigTimeoutTime_IDCM" SG_ 2654486598 CBV_bit5_1E384046 0;
BA_ "GenSigTimeoutTime_EVCU2" SG_ 2654486598 CBV_bit5_1E384046 0;
BA_ "GenSigTimeoutTime_BPCM" SG_ 2654486598 CBV_bit5_1E384046 0;
BA_ "GenSigTimeoutTime_PPIM" SG_ 2654486598 CBV_bit5_1E384046 0;
BA_ "GenSigTimeoutTime_HCP" SG_ 2654486598 CBV_bit5_1E384046 0;
BA_ "GenSigTimeoutTime_SGW" SG_ 2654486598 CBV_bit7_1E384046 0;
BA_ "GenSigTimeoutTime_IDCM" SG_ 2654486598 CBV_bit7_1E384046 0;
BA_ "GenSigTimeoutTime_EVCU2" SG_ 2654486598 CBV_bit7_1E384046 0;
BA_ "GenSigTimeoutTime_BPCM" SG_ 2654486598 CBV_bit7_1E384046 0;
BA_ "GenSigTimeoutTime_PPIM" SG_ 2654486598 CBV_bit7_1E384046 0;
BA_ "GenSigTimeoutTime_HCP" SG_ 2654486598 CBV_bit7_1E384046 0;
BA_ "GenSigTimeoutTime_SGW" SG_ 2654486598 SourceNodeIdentifier_1E384046 0;
BA_ "GenSigTimeoutTime_IDCM" SG_ 2654486598 SourceNodeIdentifier_1E384046 0;
BA_ "GenSigTimeoutTime_EVCU2" SG_ 2654486598 SourceNodeIdentifier_1E384046 0;
BA_ "GenSigTimeoutTime_BPCM" SG_ 2654486598 SourceNodeIdentifier_1E384046 0;
BA_ "GenSigTimeoutTime_PPIM" SG_ 2654486598 SourceNodeIdentifier_1E384046 0;
BA_ "GenSigTimeoutTime_HCP" SG_ 2654486598 SourceNodeIdentifier_1E384046 0;
BA_ "GenSigTimeoutTime_SGW" SG_ 2654486598 CBV_bit0_RepeatMessageReque_0002 0;
BA_ "GenSigTimeoutTime_IDCM" SG_ 2654486598 CBV_bit0_RepeatMessageReque_0002 0;
BA_ "GenSigTimeoutTime_EVCU2" SG_ 2654486598 CBV_bit0_RepeatMessageReque_0002 0;
BA_ "GenSigTimeoutTime_BPCM" SG_ 2654486598 CBV_bit0_RepeatMessageReque_0002 0;
BA_ "GenSigTimeoutTime_PPIM" SG_ 2654486598 CBV_bit0_RepeatMessageReque_0002 0;
BA_ "GenSigTimeoutTime_HCP" SG_ 2654486598 CBV_bit0_RepeatMessageReque_0002 0;
BA_ "SystemSignalLongSymbol" SG_ 2654486598 CBV_bit0_RepeatMessageReque_0002 "CBV_bit0_RepeatMessageRequestBit_1E384046";
BA_ "GenSigTimeoutTime_SGW" SG_ 2654486598 CBV_bit3_NMCoordinatorBit_1_0002 0;
BA_ "GenSigTimeoutTime_IDCM" SG_ 2654486598 CBV_bit3_NMCoordinatorBit_1_0002 0;
BA_ "GenSigTimeoutTime_EVCU2" SG_ 2654486598 CBV_bit3_NMCoordinatorBit_1_0002 0;
BA_ "GenSigTimeoutTime_BPCM" SG_ 2654486598 CBV_bit3_NMCoordinatorBit_1_0002 0;
BA_ "GenSigTimeoutTime_PPIM" SG_ 2654486598 CBV_bit3_NMCoordinatorBit_1_0002 0;
BA_ "GenSigTimeoutTime_HCP" SG_ 2654486598 CBV_bit3_NMCoordinatorBit_1_0002 0;
BA_ "SystemSignalLongSymbol" SG_ 2654486598 CBV_bit3_NMCoordinatorBit_1_0002 "CBV_bit3_NMCoordinatorBit_1E384046";
BA_ "GenSigTimeoutTime_SGW" SG_ 2654486598 CBV_bit4_ActiveWakeupBit_1E38404 0;
BA_ "GenSigTimeoutTime_IDCM" SG_ 2654486598 CBV_bit4_ActiveWakeupBit_1E38404 0;
BA_ "GenSigTimeoutTime_EVCU2" SG_ 2654486598 CBV_bit4_ActiveWakeupBit_1E38404 0;
BA_ "GenSigTimeoutTime_BPCM" SG_ 2654486598 CBV_bit4_ActiveWakeupBit_1E38404 0;
BA_ "GenSigTimeoutTime_PPIM" SG_ 2654486598 CBV_bit4_ActiveWakeupBit_1E38404 0;
BA_ "GenSigTimeoutTime_HCP" SG_ 2654486598 CBV_bit4_ActiveWakeupBit_1E38404 0;
BA_ "SystemSignalLongSymbol" SG_ 2654486598 CBV_bit4_ActiveWakeupBit_1E38404 "CBV_bit4_ActiveWakeupBit_1E384046";
BA_ "GenSigTimeoutTime_SGW" SG_ 2654486598 CBV_bit6_PartialNtwInfBit_1_0002 0;
BA_ "GenSigTimeoutTime_IDCM" SG_ 2654486598 CBV_bit6_PartialNtwInfBit_1_0002 0;
BA_ "GenSigTimeoutTime_EVCU2" SG_ 2654486598 CBV_bit6_PartialNtwInfBit_1_0002 0;
BA_ "GenSigTimeoutTime_BPCM" SG_ 2654486598 CBV_bit6_PartialNtwInfBit_1_0002 0;
BA_ "GenSigTimeoutTime_PPIM" SG_ 2654486598 CBV_bit6_PartialNtwInfBit_1_0002 0;
BA_ "GenSigTimeoutTime_HCP" SG_ 2654486598 CBV_bit6_PartialNtwInfBit_1_0002 0;
BA_ "SystemSignalLongSymbol" SG_ 2654486598 CBV_bit6_PartialNtwInfBit_1_0002 "CBV_bit6_PartialNtwInfBit_1E384046";
VAL_ 1053 VIN_MSG 0 "VIN_LO" 1 "VIN_MID" 2 "VIN_HI" 3 "SNA" ;
VAL_ 520 GearEngagedForDisplay 0 "Initialize" 1 "1st_gear" 2 "2nd_gear" 3 "3rd_gear" 4 "4th_gear" 5 "5th_gear" 6 "6th_gear" 7 "7th_gear" 8 "8th_gear " 9 "9th_gear" 10 "Not_used1" 11 "Not_Used2" 12 "P" 13 "N" 14 "R" 15 "D" 16 "L" 17 "M" 18 "S" 31 "SNA" ;
VAL_ 156 GPS_UTC_Second 65535 "SNA" ;
VAL_ 156 GPS_UTC_Minute 255 "SNA" ;
VAL_ 156 GPS_UTC_Hour 255 "SNA" ;
VAL_ 156 GPS_Date_Year 65535 "SNA" ;
VAL_ 156 GPS_Date_Month 255 "SNA" ;
VAL_ 156 GPS_Date_Day 255 "SNA" ;
VAL_ 1058 CARB_PERM 0 "False" 1 "True" ;
VAL_ 1058 OAT_PT_EstV 0 "Valid" 1 "Not_Valid" ;
VAL_ 1626 IMPACTConfirm 0 "Actuate" 1 "Do_Not_Actuate" ;
VAL_ 1626 IMPACTCommand 0 "Do_Not_Actuate" 1 "Actuate" ;
VAL_ 609 EPBSts 0 "Released" 1 "Applied" 2 "DynamicBrkESC" 3 "DynamicBrkEPB" 4 "Emergency_Braking" 5 "Applying" 6 "Maintenance_Mode" 7 "Assembly_Check" 8 "Inspection_Mode" 9 "Re_Clamping" 10 "Adjuste_Mode" 11 "Releasing" 12 "Fault_EPB_Released" 13 "Fault_EPB_Applied" 14 "Fault_Present" 15 "SNA" ;
VAL_ 1066 ExternalTemperature 511 "SNA" ;
VAL_ 256 OperationalModeSts 0 "Initialization" 1 "Ignition_Off_WithoutKey" 2 "Ignition_Off" 3 "Ignition_Acc" 4 "Ignition_On" 5 "Ignition_Pre_Start" 6 "Ignition_Start" 7 "Ignition_Cranking" 8 "Ignition_On_EngOn" 9 "Ignition_Pre_Acc" 10 "Ignition_Pre_Off" 11 "Automatic_Cranking" 12 "Automatic_Stop" 13 "Key_Authenticated" 14 "Not_Used" 15 "SNA" ;
VAL_ 1153 ExternalTemperatureC 511 "SNA" ;
VAL_ 1153 CmdIgnSts 0 "Initialization" 1 "IGN_LK" 3 "ACC" 4 "RUN" 5 "START" 7 "SNA" ;
VAL_ 1373 DCDC_OutputPower 1023 "SNA" ;
VAL_ 1373 DCDC_Utilization 127 "SNA" ;
VAL_ 1373 DCDC_TotalOperatingTime 65535 "SNA" ;
VAL_ 1373 DCDC_InputPower 1023 "SNA" ;
VAL_ 1373 DCDC_DeratingReason 0 "No_Derating" 1 "high_temp_De_rating" 2 "low_temp_De_rating" 3 "OverVolt_HV_De_rating" 4 "lowVolt_HV_De_rating" 5 "highVolt_LV_De_rating" 6 "lowVolt_LV_De_rating" 7 "highCurrent_LV_Current_limit" 8 "internal_HD_fail_De_rating" 9 "high_current_HV_De_rating" 31 "SNA" ;
VAL_ 1373 DCDC_DeratingPower 63 "SNA" ;
VAL_ 1373 DCDC_DeratingModeSts 0 "No_derating" 1 "Derating_Initialized" 2 "Derating_Initialization_Failure" 3 "Derating_Mode" 7 "SNA" ;
VAL_ 1373 DCDC_CurrentCycleTime 65535 "SNA" ;
VAL_ 1373 DCDC_BatteryFeedVoltage 4095 "SNA" ;
VAL_ 1030 DCDC_FailureReason 0 "No_Failure" 1 "Fail_high_voltage_at_HV" 2 "Fail_low_voltage_at_HV" 3 "Fail_high_voltage_at_LV" 4 "Fail_low_voltage_at_LV" 5 "Fail_high_PCB_temperature" 6 "Fail_high_DBC_temperature" 7 "Fail_high_cur_at_LV" 8 "Fail_high_curr_at_HV" 9 "Fail_short_circ_at_LV" 10 "Fail_short_circ_at_HV" 11 "Fail_open_circ_at_LV" 12 "Fail_open_circ_at_HV" 13 "Fail_init_failure" 14 "Fail_wake_up_issue" 15 "Fail_internal_hardware" 16 "Fail_bat_feed_low" 17 "Fail_bat_feed_high_" 18 "Fail_Aux_OV" 19 "Fail_Aux_UV" 20 "Fail_HVIL_fault" 21 "Fail_LOC_with_HCP" 22 "Fail_LOC_with_BPCM" 23 "Fail_cont_not_closed" 24 "Fail_SBC_fault" 25 "Memory_Fail" 26 "Implausible_data_from_HCP" 27 "Implausible_data_from_BPCM" 28 "CAN_bus_off" 29 "Fail_temp_diff_is_high" 30 "Fail_high_voltage_diff_is_high" 31 "Fail_for_other_reason" 32 "LOC_ORC" 33 "Implausible_data_ORC" 63 "SNA" ;
VAL_ 1030 LVDC_VoltageSetpointFdbk 255 "SNA" ;
VAL_ 1030 LVDC_CurrentSetpointFdbk 511 "SNA" ;
VAL_ 1030 HVDC_VoltageSetpointFdbk 511 "SNA" ;
VAL_ 1030 HVDC_CurrentSetpointFdbk 1023 "SNA" ;
VAL_ 1030 DCDC_InternalMode 0 "Not_in_Buck" 1 "Current_control" 2 "voltage_control" 3 "Default_current_set_point" 4 "Default_voltage_set_point" 7 "SNA" ;
VAL_ 1030 DCDC_FailureType 0 "No_Failure" 1 "Failure_ChargingInhibited" 2 "Failure_ChargingAllowed" 3 "SNA" ;
VAL_ 1030 DCDC_EstimatedPowerLoss 255 "SNA" ;
VAL_ 753 LVDC_CurrentFeedback 4095 "SNA" ;
VAL_ 753 DCDC_OperationModeSts 0 "IDLE" 1 "Buck_CV" 2 "Buck_CC" 3 "Buck_CP" 4 "Buck_Special" 5 "Boost" 6 "Precharge" 7 "Discharge" 8 "Failure" 15 "SNA" ;
VAL_ 753 LVDC_VoltageFeedback 4095 "SNA" ;
VAL_ 753 HVDC_VoltageFeedback 4095 "SNA" ;
VAL_ 753 HVDC_CurrentFeedback 4095 "SNA" ;
VAL_ 753 IDCM_Wakeup_HCP 0 "No_Event" 1 "WakeUp_Event" ;
VAL_ 752 IBS3_Vbatt 511 "SNA" ;
VAL_ 267 LOC_DiagEnable_ePT 0 "Default" 1 "ENB_LOC" 2 "ENB_LOC_LIMIT" ;
VAL_ 267 HybridDriveModeSts 0 "Drive_Mode_Unavailable" 1 "Hybrid" 2 "Sport" 4 "ESave" 8 "Electric" 15 "SNA" ;
VAL_ 267 HCP_ShutdownCommand 0 "default" 1 "Initiate_Powerdown" 2 "Shutdown" 3 "Cancel_Powerdown" 7 "SNA" ;
VAL_ 1956 Warning_MotorB_Overtemp 0 "Normal" 1 "Warning" ;
VAL_ 1956 Warning_MotorA_Overtemp 0 "Normal" 1 "Warning" ;
VAL_ 1956 Warning_InverterA_Overtemp 0 "Normal" 1 "Warning" ;
VAL_ 1956 Warning_DCDCTemp_DPT 0 "Normal" 1 "Warning" ;
VAL_ 1956 Warning_DCDCPerformance_DPT 0 "Normal" 1 "Warning" ;
VAL_ 1956 MotorB_InverterState 0 "NORMAL_PWR_STAGE_OFF" 1 "NORMAL_PWR_STAGE_ON" 2 "PWR_STAGE_ON_SHUTDWN_PNDING" 3 "ACTIVE_DISCHARGE" 4 "INVERTER_FAULTED" ;
VAL_ 1956 MotorA_InverterState 0 "NORMAL_PWR_STAGE_OFF" 1 "NORMAL_PWR_STAGE_ON" 2 "PWR_STAGE_ON_SHUTDWN_PNDING" 3 "ACTIVE_DISCHARGE" 4 "INVERTER_FAULTED" ;
VAL_ 1956 Warning_InverterB_Overtemp 0 "Normal" 1 "Warning" ;
VAL_ 1033 MCP_DC_Current 0 "SNA" ;
VAL_ 1033 MCP_DC_CurrentV 0 "Valid" 1 "Not_Valid" ;
VAL_ 1834 HVBattery_RealTimeClockV 0 "Valid" 1 "Not_Valid" ;
VAL_ 1834 HVBattery_RealTimeClock -2147483648 "SNA" ;
VAL_ 1834 HVBatteryBalanceMode 0 "NoBalancing" 1 "Balancing" ;
VAL_ 1834 HVBatteryBalanceComplete 0 "INCOMPLETE" 1 "COMPLETE" ;
VAL_ 1834 HVBatCellOCVoltage_MinV 0 "Valid" 1 "Not_Valid" ;
VAL_ 1834 HVBatCellOCVoltage_Min 4095 "SNA" ;
VAL_ 1834 HVBatCellOCVoltage_MaxV 0 "Valid" 1 "Not_Valid" ;
VAL_ 1834 HVBatCellOCVoltage_Max 4095 "SNA" ;
VAL_ 1834 HVBatCellOCVoltage_AverageV 0 "Valid" 1 "Not_Valid" ;
VAL_ 1834 HVBatCellOCVoltage_Average 4095 "SNA" ;
VAL_ 1834 HVBatCellDischargeImped_Min 4095 "SNA" ;
VAL_ 1834 HVBatCellDischargeImped_Max 4095 "SNA" ;
VAL_ 1029 HVBatPowerLimited 0 "FALSE" 1 "TRUE" ;
VAL_ 1029 BSGDischargePower_ShortV 0 "Valid" 1 "Not_Valid" ;
VAL_ 1029 BSGDischargePower_Short 255 "SNA" ;
VAL_ 1029 BSGDischargePower_LongV 0 "Valid" 1 "Not_Valid" ;
VAL_ 1029 BSGDischargePower_Long 255 "SNA" ;
VAL_ 1029 BSGDischargePower_InstantV 0 "Valid" 1 "Not_Valid" ;
VAL_ 1029 BSGDischargePower_Instant 255 "SNA" ;
VAL_ 1029 BSGChargePower_ShortV 0 "Valid" 1 "Not_Valid" ;
VAL_ 1029 BSGChargePower_Short 255 "SNA" ;
VAL_ 1029 BSGChargePower_LongV 0 "Valid" 1 "Not_Valid" ;
VAL_ 1029 BSGChargePower_Long 255 "SNA" ;
VAL_ 1029 BSGChargePower_InstantV 0 "Valid" 1 "Not_Valid" ;
VAL_ 1029 BSGChargePower_Instant 255 "SNA" ;
VAL_ 1027 HVBatteryMILRequest 0 "FALSE" 1 "TRUE" ;
VAL_ 1027 HVBatterySOH 255 "SNA" ;
VAL_ 1027 HVBatteryServiceRequest 0 "FALSE" 1 "TRUE" ;
VAL_ 1027 PrechargePenaltyTimer 1023 "SNA" ;
VAL_ 266 HVBatteryCurrent 16383 "SNA" ;
VAL_ 266 HVBatContactorSts 0 "Open" 1 "Precharging" 2 "Closed" 3 "Precharge_Failed" 4 "Precharge_Inhibited" 7 "SNA" ;
VAL_ 266 HVBatCellVoltage_Min 8191 "SNA" ;
VAL_ 266 HVBatCellVoltage_Max 8191 "SNA" ;
VAL_ 266 HVBatteryVoltageV 0 "Valid" 1 "Not_Valid" ;
VAL_ 266 HVBatteryReady 0 "FALSE" 1 "TRUE" ;
VAL_ 266 HVBatteryCurrentV 0 "Valid" 1 "Not_Valid" ;
VAL_ 266 HVBatContactorReq 0 "FALSE" 1 "TRUE" ;
VAL_ 266 HVBatContactorOpen 0 "FALSE" 1 "TRUE" ;
VAL_ 266 HVBatCellVoltage_MinV 0 "Valid" 1 "Not_Valid" ;
VAL_ 266 HVBatCellVoltage_MaxV 0 "Valid" 1 "Not_Valid" ;
VAL_ 266 HVBatCellVoltage_AverageV 0 "Valid" 1 "Not_Valid" ;
VAL_ 266 HVBatCellVoltage_Average 8191 "SNA" ;
VAL_ 266 HVBatShutdownReady 0 "Not_Ready_for_Shutdown" 1 "Ready_for_Shutdown_Req" 2 "Shutdown_in_Process" 3 "Shutdown_Complete" ;
VAL_ 266 HVBatContactorWelded 0 "Normal" 1 "Stuck_Open" 2 "Stuck_Closed" 3 "SNA" ;
VAL_ 1034 HVBatModuleTemp_MinV 0 "Valid" 1 "Not_Valid" ;
VAL_ 1034 HVBatModuleTemp_Min 255 "SNA" ;
VAL_ 1034 HVBatModuleTemp_MaxV 0 "Valid" 1 "Not_Valid" ;
VAL_ 1034 HVBatModuleTemp_Max 255 "SNA" ;
VAL_ 1034 HVBatSleepTime 255 "SNA" ;
VAL_ 1034 HVBatModuleTemp_AverageV 0 "Valid" 1 "Not_Valid" ;
VAL_ 1034 HVBatModuleTemp_Average 255 "SNA" ;
VAL_ 1034 HVBatLowTempThreshold 255 "SNA" ;
VAL_ 1034 HVBatHighTempThreshold 255 "SNA" ;
VAL_ 1839 HVBatModuleTemp_16 255 "SNA" ;
VAL_ 1839 HVBatModuleTemp_15 255 "SNA" ;
VAL_ 1839 HVBatModuleTemp_14 255 "SNA" ;
VAL_ 1839 HVBatModuleTemp_13 255 "SNA" ;
VAL_ 1839 HVBatModuleTemp_12 255 "SNA" ;
VAL_ 1839 HVBatModuleTemp_11 255 "SNA" ;
VAL_ 1839 HVBatModuleTemp_10 255 "SNA" ;
VAL_ 1839 HVBatModuleTemp_09 255 "SNA" ;
VAL_ 1839 HVBatModuleTemp_08 255 "SNA" ;
VAL_ 1839 HVBatModuleTemp_07 255 "SNA" ;
VAL_ 1839 HVBatModuleTemp_06 255 "SNA" ;
VAL_ 1839 HVBatModuleTemp_05 255 "SNA" ;
VAL_ 1839 HVBatModuleTemp_04 255 "SNA" ;
VAL_ 1839 HVBatModuleTemp_03 255 "SNA" ;
VAL_ 1839 HVBatModuleTemp_02 255 "SNA" ;
VAL_ 1839 HVBatModuleTemp_01 255 "SNA" ;
VAL_ 1839 HVBatModuleTemp_38 255 "SNA" ;
VAL_ 1839 HVBatModuleTemp_37 255 "SNA" ;
VAL_ 1839 HVBatModuleTemp_36 255 "SNA" ;
VAL_ 1839 HVBatModuleTemp_35 255 "SNA" ;
VAL_ 1839 HVBatModuleTemp_34 255 "SNA" ;
VAL_ 1839 HVBatModuleTemp_33 255 "SNA" ;
VAL_ 1839 HVBatModuleTemp_32 255 "SNA" ;
VAL_ 1839 HVBatModuleTemp_31 255 "SNA" ;
VAL_ 1839 HVBatModuleTemp_30 255 "SNA" ;
VAL_ 1839 HVBatModuleTemp_29 255 "SNA" ;
VAL_ 1839 HVBatModuleTemp_28 255 "SNA" ;
VAL_ 1839 HVBatModuleTemp_27 255 "SNA" ;
VAL_ 1839 HVBatModuleTemp_26 255 "SNA" ;
VAL_ 1839 HVBatModuleTemp_25 255 "SNA" ;
VAL_ 1839 HVBatModuleTemp_24 255 "SNA" ;
VAL_ 1839 HVBatModuleTemp_23 255 "SNA" ;
VAL_ 1839 HVBatModuleTemp_22 255 "SNA" ;
VAL_ 1839 HVBatModuleTemp_21 255 "SNA" ;
VAL_ 1839 HVBatModuleTemp_20 255 "SNA" ;
VAL_ 1839 HVBatModuleTemp_19 255 "SNA" ;
VAL_ 1839 HVBatModuleTemp_18 255 "SNA" ;
VAL_ 1839 HVBatModuleTemp_17 255 "SNA" ;
VAL_ 1840 IsolationResistance 65535 "SNA" ;
VAL_ 1840 Warning_SOCJump 0 "Normal" 1 "Warning" ;
VAL_ 1840 Warning_PackUnmatched 0 "Normal" 1 "Warning" ;
VAL_ 1840 Warning_PackUndervoltage 0 "Normal" 1 "Warning" ;
VAL_ 1840 Warning_PackTempHigh 0 "Normal" 1 "Warning" ;
VAL_ 1840 Warning_PackTempDiff 0 "Normal" 1 "Warning" ;
VAL_ 1840 Warning_PackOvervoltage 0 "Normal" 1 "Warning" ;
VAL_ 1840 Warning_Overcharging 0 "Normal" 1 "Warning" ;
VAL_ 1840 Warning_LowSOC 0 "Normal" 1 "Warning" ;
VAL_ 1840 Warning_Insulation 0 "Normal" 1 "Warning" ;
VAL_ 1840 Warning_HVIL 0 "Normal" 1 "Warning" ;
VAL_ 1840 Warning_HighSOC 0 "Normal" 1 "Warning" ;
VAL_ 1840 Warning_CellUndervoltage 0 "Normal" 1 "Warning" ;
VAL_ 1840 Warning_CellOvervoltage 0 "Normal" 1 "Warning" ;
VAL_ 1840 Warning_CellBalance 0 "Normal" 1 "Warning" ;
VAL_ 1840 HighestWarningLevel 0 "No_Faults" 1 "Level_1" 2 "Level_2" 3 "Level_3" ;
VAL_ 1838 HVBatCellVoltage_Cell096 8191 "SNA" ;
VAL_ 1838 HVBatCellVoltage_Cell095 8191 "SNA" ;
VAL_ 1838 HVBatCellVoltage_Cell094 8191 "SNA" ;
VAL_ 1838 HVBatCellVoltage_Cell093 8191 "SNA" ;
VAL_ 1838 HVBatCellVoltage_Cell092 8191 "SNA" ;
VAL_ 1838 HVBatCellVoltage_Cell091 8191 "SNA" ;
VAL_ 1838 HVBatCellVoltage_Cell090 8191 "SNA" ;
VAL_ 1838 HVBatCellVoltage_Cell089 8191 "SNA" ;
VAL_ 1838 HVBatCellVoltage_Cell088 8191 "SNA" ;
VAL_ 1838 HVBatCellVoltage_Cell087 8191 "SNA" ;
VAL_ 1838 HVBatCellVoltage_Cell086 8191 "SNA" ;
VAL_ 1838 HVBatCellVoltage_Cell085 8191 "SNA" ;
VAL_ 1838 HVBatCellVoltage_Cell084 8191 "SNA" ;
VAL_ 1838 HVBatCellVoltage_Cell083 8191 "SNA" ;
VAL_ 1838 HVBatCellVoltage_Cell082 8191 "SNA" ;
VAL_ 1838 HVBatCellVoltage_Cell108 8191 "SNA" ;
VAL_ 1838 HVBatCellVoltage_Cell107 8191 "SNA" ;
VAL_ 1838 HVBatCellVoltage_Cell106 8191 "SNA" ;
VAL_ 1838 HVBatCellVoltage_Cell105 8191 "SNA" ;
VAL_ 1838 HVBatCellVoltage_Cell104 8191 "SNA" ;
VAL_ 1838 HVBatCellVoltage_Cell103 8191 "SNA" ;
VAL_ 1838 HVBatCellVoltage_Cell102 8191 "SNA" ;
VAL_ 1838 HVBatCellVoltage_Cell101 8191 "SNA" ;
VAL_ 1838 HVBatCellVoltage_Cell100 8191 "SNA" ;
VAL_ 1838 HVBatCellVoltage_Cell099 8191 "SNA" ;
VAL_ 1838 HVBatCellVoltage_Cell098 8191 "SNA" ;
VAL_ 1838 HVBatCellVoltage_Cell097 8191 "SNA" ;
VAL_ 1837 HVBatCellVoltage_Cell081 8191 "SNA" ;
VAL_ 1837 HVBatCellVoltage_Cell080 8191 "SNA" ;
VAL_ 1837 HVBatCellVoltage_Cell079 8191 "SNA" ;
VAL_ 1837 HVBatCellVoltage_Cell078 8191 "SNA" ;
VAL_ 1837 HVBatCellVoltage_Cell077 8191 "SNA" ;
VAL_ 1837 HVBatCellVoltage_Cell076 8191 "SNA" ;
VAL_ 1837 HVBatCellVoltage_Cell075 8191 "SNA" ;
VAL_ 1837 HVBatCellVoltage_Cell074 8191 "SNA" ;
VAL_ 1837 HVBatCellVoltage_Cell073 8191 "SNA" ;
VAL_ 1837 HVBatCellVoltage_Cell072 8191 "SNA" ;
VAL_ 1837 HVBatCellVoltage_Cell071 8191 "SNA" ;
VAL_ 1837 HVBatCellVoltage_Cell070 8191 "SNA" ;
VAL_ 1837 HVBatCellVoltage_Cell069 8191 "SNA" ;
VAL_ 1837 HVBatCellVoltage_Cell068 8191 "SNA" ;
VAL_ 1837 HVBatCellVoltage_Cell067 8191 "SNA" ;
VAL_ 1837 HVBatCellVoltage_Cell066 8191 "SNA" ;
VAL_ 1837 HVBatCellVoltage_Cell065 8191 "SNA" ;
VAL_ 1837 HVBatCellVoltage_Cell064 8191 "SNA" ;
VAL_ 1837 HVBatCellVoltage_Cell063 8191 "SNA" ;
VAL_ 1837 HVBatCellVoltage_Cell062 8191 "SNA" ;
VAL_ 1837 HVBatCellVoltage_Cell061 8191 "SNA" ;
VAL_ 1837 HVBatCellVoltage_Cell060 8191 "SNA" ;
VAL_ 1837 HVBatCellVoltage_Cell059 8191 "SNA" ;
VAL_ 1837 HVBatCellVoltage_Cell058 8191 "SNA" ;
VAL_ 1837 HVBatCellVoltage_Cell057 8191 "SNA" ;
VAL_ 1837 HVBatCellVoltage_Cell056 8191 "SNA" ;
VAL_ 1837 HVBatCellVoltage_Cell055 8191 "SNA" ;
VAL_ 1836 HVBatCellVoltage_Cell054 8191 "SNA" ;
VAL_ 1836 HVBatCellVoltage_Cell053 8191 "SNA" ;
VAL_ 1836 HVBatCellVoltage_Cell052 8191 "SNA" ;
VAL_ 1836 HVBatCellVoltage_Cell051 8191 "SNA" ;
VAL_ 1836 HVBatCellVoltage_Cell050 8191 "SNA" ;
VAL_ 1836 HVBatCellVoltage_Cell049 8191 "SNA" ;
VAL_ 1836 HVBatCellVoltage_Cell048 8191 "SNA" ;
VAL_ 1836 HVBatCellVoltage_Cell047 8191 "SNA" ;
VAL_ 1836 HVBatCellVoltage_Cell046 8191 "SNA" ;
VAL_ 1836 HVBatCellVoltage_Cell045 8191 "SNA" ;
VAL_ 1836 HVBatCellVoltage_Cell044 8191 "SNA" ;
VAL_ 1836 HVBatCellVoltage_Cell043 8191 "SNA" ;
VAL_ 1836 HVBatCellVoltage_Cell042 8191 "SNA" ;
VAL_ 1836 HVBatCellVoltage_Cell041 8191 "SNA" ;
VAL_ 1836 HVBatCellVoltage_Cell040 8191 "SNA" ;
VAL_ 1836 HVBatCellVoltage_Cell039 8191 "SNA" ;
VAL_ 1836 HVBatCellVoltage_Cell038 8191 "SNA" ;
VAL_ 1836 HVBatCellVoltage_Cell037 8191 "SNA" ;
VAL_ 1836 HVBatCellVoltage_Cell036 8191 "SNA" ;
VAL_ 1836 HVBatCellVoltage_Cell035 8191 "SNA" ;
VAL_ 1836 HVBatCellVoltage_Cell034 8191 "SNA" ;
VAL_ 1836 HVBatCellVoltage_Cell033 8191 "SNA" ;
VAL_ 1836 HVBatCellVoltage_Cell032 8191 "SNA" ;
VAL_ 1836 HVBatCellVoltage_Cell031 8191 "SNA" ;
VAL_ 1836 HVBatCellVoltage_Cell030 8191 "SNA" ;
VAL_ 1836 HVBatCellVoltage_Cell029 8191 "SNA" ;
VAL_ 1836 HVBatCellVoltage_Cell028 8191 "SNA" ;
VAL_ 1835 HVBatCellVoltage_Cell027 8191 "SNA" ;
VAL_ 1835 HVBatCellVoltage_Cell026 8191 "SNA" ;
VAL_ 1835 HVBatCellVoltage_Cell025 8191 "SNA" ;
VAL_ 1835 HVBatCellVoltage_Cell024 8191 "SNA" ;
VAL_ 1835 HVBatCellVoltage_Cell023 8191 "SNA" ;
VAL_ 1835 HVBatCellVoltage_Cell022 8191 "SNA" ;
VAL_ 1835 HVBatCellVoltage_Cell021 8191 "SNA" ;
VAL_ 1835 HVBatCellVoltage_Cell020 8191 "SNA" ;
VAL_ 1835 HVBatCellVoltage_Cell019 8191 "SNA" ;
VAL_ 1835 HVBatCellVoltage_Cell018 8191 "SNA" ;
VAL_ 1835 HVBatCellVoltage_Cell017 8191 "SNA" ;
VAL_ 1835 HVBatCellVoltage_Cell016 8191 "SNA" ;
VAL_ 1835 HVBatCellVoltage_Cell015 8191 "SNA" ;
VAL_ 1835 HVBatCellVoltage_Cell014 8191 "SNA" ;
VAL_ 1835 HVBatCellVoltage_Cell013 8191 "SNA" ;
VAL_ 1835 HVBatCellVoltage_Cell012 8191 "SNA" ;
VAL_ 1835 HVBatCellVoltage_Cell011 8191 "SNA" ;
VAL_ 1835 HVBatCellVoltage_Cell010 8191 "SNA" ;
VAL_ 1835 HVBatCellVoltage_Cell009 8191 "SNA" ;
VAL_ 1835 HVBatCellVoltage_Cell008 8191 "SNA" ;
VAL_ 1835 HVBatCellVoltage_Cell007 8191 "SNA" ;
VAL_ 1835 HVBatCellVoltage_Cell006 8191 "SNA" ;
VAL_ 1835 HVBatCellVoltage_Cell005 8191 "SNA" ;
VAL_ 1835 HVBatCellVoltage_Cell004 8191 "SNA" ;
VAL_ 1835 HVBatCellVoltage_Cell003 8191 "SNA" ;
VAL_ 1835 HVBatCellVoltage_Cell002 8191 "SNA" ;
VAL_ 1835 HVBatCellVoltage_Cell001 8191 "SNA" ;
VAL_ 1035 RadFanReq 127 "SNA" ;
VAL_ 1035 EngCltTmpV 0 "False" 1 "True" ;
VAL_ 1035 EngCltTmp 255 "SNA" ;
VAL_ 750 Battery_Volt_1 511 "SNA" ;
VAL_ 1436 Blower_Speed 511 "SNA" ;
VAL_ 2654486640 CBV_bit0_RepeatMessageRequestBit 0 "Repeat_Message_State_not_requested" 1 "Repeat_Message_State_requested" ;
VAL_ 2654486640 CBV_bit3_NMCoordinatorBit_1E3840 0 "Start_of_synchronized_shutdown_is_not_requested_by_main_coordinator" 1 "Start_of_synchronized_shutdown_is_requested_by_main_coordinator" ;
VAL_ 2654486640 CBV_bit4_ActiveWakeupBit_1E38407 0 "PassiveWakeup" 1 "ActiveWakeup" ;
VAL_ 2654486640 CBV_bit6_PartialNtwInfBit_1E3840 0 "NM_PDU_contains_no_Partial_Network_request_information" 1 "NM_PDU_contains_Partial_Network_request_information" ;
VAL_ 2654486626 CBV_bit0_RepeatMessageReque_0000 0 "Repeat Message State not requested" 1 "Repeat Message State requested" ;
VAL_ 2654486626 CBV_bit3_NMCoordinatorBit_1_0000 0 "Start of synchronized shutdown is not requested by main coordinator" 1 "Start of synchronized shutdown is requested by main coordinator" ;
VAL_ 2654486626 CBV_bit4_ActiveWakeupBit_1E38406 0 "PassiveWakeup" 1 "ActiveWakeup" ;
VAL_ 2654486626 CBV_bit6_PartialNtwInfBit_1_0000 0 "NM PDU contains no Partial Network request information" 1 "NM PDU contains Partial Network request information" ;
VAL_ 276 HEV_ESS_Mode 0 "EngOff" 1 "IS" 2 "STPA" 3 "EFA" 4 "ETS" 5 "PT" 6 "DFA" 7 "SPPA" 8 "SF" 9 "CT" 15 "SNA" ;
VAL_ 276 PropulsionSystemActive_114 0 "Not_Active" 1 "Active" ;
VAL_ 262 PowertrainPrplsnActv 0 "Off" 1 "Active" ;
VAL_ 262 EngineSpeed_W 16383 "SNA" ;
VAL_ 258 VehicleSpeedVSOSig 8191 "SNA" ;
VAL_ 2654486653 CBV_bit0_RepeatMessageReque_0001 0 "Repeat Message State not requested" 1 "Repeat Message State requested" ;
VAL_ 2654486653 CBV_bit3_NMCoordinatorBit_1_0001 0 "Start of synchronized shutdown is not requested by main coordinator" 1 "Start of synchronized shutdown is requested by main coordinator" ;
VAL_ 2654486653 CBV_bit4_ActiveWakeupBit_1E_0000 0 "PassiveWakeup" 1 "ActiveWakeup" ;
VAL_ 2654486653 CBV_bit6_PartialNtwInfBit_1_0001 0 "NM PDU contains no Partial Network request information" 1 "NM PDU contains Partial Network request information" ;
VAL_ 2654486598 CBV_bit0_RepeatMessageReque_0002 0 "Repeat Message State not requested" 1 "Repeat Message State requested" ;
VAL_ 2654486598 CBV_bit3_NMCoordinatorBit_1_0002 0 "Start of synchronized shutdown is not requested by main coordinator" 1 "Start of synchronized shutdown is requested by main coordinator" ;
VAL_ 2654486598 CBV_bit4_ActiveWakeupBit_1E38404 0 "PassiveWakeup" 1 "ActiveWakeup" ;
VAL_ 2654486598 CBV_bit6_PartialNtwInfBit_1_0002 0 "NM PDU contains no Partial Network request information" 1 "NM PDU contains Partial Network request information" ;
SIG_GROUP_ 276 HYBRID_POWERTRAIN1_Pkt 1 : HEV_ESS_Mode PropulsionSystemActive_114;
